VERSION "HNNBNNNYNNNNNNNNNNNNNNNNNNNNNNNNNNNNNNNNNN/4/%%%/4/'%**4NNN///"

NS_ :

BS_:

BU_: BAP_Tester conBox Gateway Gateway_PAG OTA_FC

BO_ 64 Airbag_01: 8 Gateway
 SG_ Airbag_01_CRC : 0|8@1+ (1,0) [0|255] ""  Vector__XXX
 SG_ Airbag_01_BZ : 8|4@1+ (1,0) [0|15] ""  Vector__XXX
 SG_ AB_RGS_Anst : 12|4@1+ (1.0,0.0) [0.0|15] ""  Vector__XXX
 SG_ AB_Front_Crash : 16|1@1+ (1.0,0.0) [0.0|1] ""  conBox
 SG_ AB_Heck_Crash : 17|1@1+ (1.0,0.0) [0.0|1] ""  conBox
 SG_ AB_SF_Crash : 18|1@1+ (1.0,0.0) [0.0|1] ""  conBox
 SG_ AB_SB_Crash : 19|1@1+ (1.0,0.0) [0.0|1] ""  conBox
 SG_ AB_Rollover_Crash : 20|1@1+ (1.0,0.0) [0.0|1] ""  conBox
 SG_ AB_Crash_Int : 21|3@1+ (1.0,0.0) [0.0|7] ""  conBox
 SG_ AB_Lampe : 24|1@1+ (1.0,0.0) [0.0|1] ""  Vector__XXX
 SG_ AB_Deaktiviert : 25|1@1+ (1.0,0.0) [0.0|1] ""  Vector__XXX
 SG_ AB_VB_deaktiviert : 26|1@1+ (1.0,0.0) [0.0|1] ""  Vector__XXX
 SG_ AB_Systemfehler : 27|1@1+ (1.0,0.0) [0.0|1] ""  conBox
 SG_ AB_Diagnose : 28|1@1+ (1.0,0.0) [0.0|1] ""  conBox
 SG_ AB_Stellgliedtest : 29|1@1+ (1.0,0.0) [0.0|1] ""  conBox
 SG_ AB_Erh_Auf_VB : 30|2@1+ (1.0,0.0) [0.0|3] ""  Vector__XXX
 SG_ AB_Gurtwarn_VF : 32|1@1+ (1.0,0.0) [0.0|1] ""  Vector__XXX
 SG_ AB_Gurtwarn_VB : 33|1@1+ (1.0,0.0) [0.0|1] ""  Vector__XXX
 SG_ AB_Anzeige_Fussg : 34|2@1+ (1.0,0.0) [0.0|3] ""  conBox
 SG_ AB_Texte_AKS : 36|2@1+ (1.0,0.0) [0.0|3] ""  Vector__XXX
 SG_ AB_MKB_gueltig : 39|1@1+ (1.0,0.0) [0.0|1] ""  Vector__XXX
 SG_ AB_MKB_Anforderung : 40|1@1+ (1.0,0.0) [0.0|1] ""  Vector__XXX
 SG_ AB_Versorgungsspannung : 41|1@1+ (1.0,0.0) [0.0|1] ""  Vector__XXX
 SG_ AB_Deaktivierung_HV : 42|3@1+ (1.0,0.0) [0.0|7] ""  Vector__XXX
 SG_ AB_EDR_Trigger : 45|2@1+ (1.0,0.0) [0.0|3] ""  Vector__XXX
 SG_ AB_Belegung_VF : 47|2@1+ (1.0,0.0) [0.0|3] ""  Vector__XXX
 SG_ SC_Masterzeit_Offset : 53|2@1+ (5.08,0) [0.00|15.24] "Unit_Secon"  Vector__XXX
 SG_ SC_LowSpeedCrashErkannt : 55|2@1+ (1.0,0.0) [0.0|3] ""  Vector__XXX
 SG_ SC_Masterzeit : 57|7@1+ (0.04,0) [0.00|5.04] "Unit_Secon"  Vector__XXX

BO_ 1312 Airbag_02: 8 Gateway
 SG_ Airbag_02_CRC : 0|8@1+ (1,0) [0|255] ""  Vector__XXX
 SG_ Airbag_02_BZ : 8|4@1+ (1,0) [0|15] ""  Vector__XXX
 SG_ LoGeWa_Event_Kombiwarnung : 12|4@1+ (1.0,0.0) [0.0|15] ""  Vector__XXX
 SG_ AB_Anforderung_eCall : 16|1@1+ (1.0,0.0) [0.0|1] ""  conBox
 SG_ AB_Anprall_Seite_Beifahrer : 17|1@1+ (1.0,0.0) [0.0|1] ""  Vector__XXX
 SG_ AB_Anprall_Rollover : 18|1@1+ (1.0,0.0) [0.0|1] ""  Vector__XXX
 SG_ AB_Anprall_FGS : 19|1@1+ (1.0,0.0) [0.0|1] ""  Vector__XXX
 SG_ AB_Anprall_Front_Beifahrer : 20|1@1+ (1.0,0.0) [0.0|1] ""  Vector__XXX
 SG_ AB_Anprall_Front_Fahrer : 21|1@1+ (1.0,0.0) [0.0|1] ""  Vector__XXX
 SG_ AB_Anprall_Heck_Beifahrer : 22|1@1+ (1.0,0.0) [0.0|1] ""  Vector__XXX
 SG_ AB_Anprall_Heck_Fahrer : 23|1@1+ (1.0,0.0) [0.0|1] ""  Vector__XXX
 SG_ AB_Wickelklappung_Reihe2_MI : 24|2@1+ (1.0,0.0) [0.0|3] ""  Vector__XXX
 SG_ AB_Belegung_VB : 26|2@1+ (1.0,0.0) [0.0|3] ""  conBox
 SG_ AB_Abschaltanf_SIH_BF : 28|1@1+ (1.0,0.0) [0.0|1] ""  Vector__XXX
 SG_ AB_Anprall_Seite_Fahrer : 29|1@1+ (1.0,0.0) [0.0|1] ""  Vector__XXX
 SG_ SC_PAO_Schriftzug_Anf : 30|2@1+ (1.0,0.0) [0.0|3] ""  Vector__XXX
 SG_ SC_PAO_ON_Anf : 32|2@1+ (1.0,0.0) [0.0|3] ""  Vector__XXX
 SG_ SC_PAO_OFF_Anf : 34|2@1+ (1.0,0.0) [0.0|3] ""  Vector__XXX
 SG_ AB_Crashschwere : 36|3@1+ (1.0,0.0) [0.0|7] ""  Vector__XXX
 SG_ AB_Anforderung_USM : 39|1@1+ (1.0,0.0) [0.0|1] ""  Vector__XXX
 SG_ AB_Gurtschloss_FA : 40|2@1+ (1.0,0.0) [0.0|3] ""  conBox
 SG_ AB_Gurtschloss_BF : 42|2@1+ (1.0,0.0) [0.0|3] ""  conBox
 SG_ AB_Gurtschloss_Reihe2_FA : 44|2@1+ (1.0,0.0) [0.0|3] ""  conBox
 SG_ AB_Gurtschloss_Reihe2_MI : 46|2@1+ (1.0,0.0) [0.0|3] ""  conBox
 SG_ AB_Gurtschloss_Reihe2_BF : 48|2@1+ (1.0,0.0) [0.0|3] ""  conBox
 SG_ AB_Gurtschloss_Reihe3_FA : 50|2@1+ (1.0,0.0) [0.0|3] ""  conBox
 SG_ AB_Gurtschloss_Reihe3_MI : 52|2@1+ (1.0,0.0) [0.0|3] ""  conBox
 SG_ AB_Gurtschloss_Reihe3_BF : 54|2@1+ (1.0,0.0) [0.0|3] ""  conBox
 SG_ AB_Sitzpos_Sens_FA : 56|2@1+ (1.0,0.0) [0.0|3] ""  Vector__XXX
 SG_ AB_Sitzpos_Sens_BF : 58|2@1+ (1.0,0.0) [0.0|3] ""  Vector__XXX
 SG_ AB_Wickelklappung_Reihe2_BF : 60|2@1+ (1.0,0.0) [0.0|3] ""  Vector__XXX
 SG_ AB_Wickelklappung_Reihe2_FA : 62|2@1+ (1.0,0.0) [0.0|3] ""  Vector__XXX

BO_ 2536705796 BAP_BC_ASG_05: 8 OTA_FC
 SG_ BAP_BC_ASG_05_Header : 0|8@1+ (1,0) [0|255] "Unit_None"  Gateway_PAG

BO_ 2536705808 BAP_BC_FSG_01: 8 Gateway_PAG
 SG_ BAP_BC_FSG_01_Header : 0|8@1+ (1.0,0.0) [0.0|255] ""  OTA_FC

BO_ 2536720128 BAP_ConnectionMngr_ASG_01: 8 Gateway
 SG_ BAP_ConnectionMngr_ASG_01_Header : 0|8@1+ (1,0) [0|255] "Unit_None"  Vector__XXX

BO_ 2536720129 BAP_ConnectionMngr_ASG_02: 8 Gateway
 SG_ BAP_ConnectionMngr_ASG_02_Header : 0|64@1+ (1.0,0.0) [0.0|18446744073709551615] ""  conBox

BO_ 2536720130 BAP_ConnectionMngr_ASG_03: 8 Gateway
 SG_ BAP_ConnectionMngr_ASG_03_Header : 0|64@1+ (1.0,0.0) [0.0|18446744073709551615] ""  conBox

BO_ 2536720144 BAP_ConnectionMngr_FSG_01: 8 conBox
 SG_ BAP_ConnectionMngr_FSG_01_Header : 0|8@1+ (1,0) [0|255] "Unit_None"  Gateway,Gateway_PAG

BO_ 2536767264 BAP_Debug_Cmd: 8 BAP_Tester
 SG_ BAP_Debug_Cmd : 0|16@1+ (1.0,0.0) [0.0|65535] ""  conBox,Gateway_PAG,OTA_FC

BO_ 2536767280 BAP_Debug_Data: 8 conBox
 SG_ BAP_Debug_Data : 0|64@1+ (1.0,0.0) [0.0|18446744073709551615] ""  BAP_Tester

BO_ 2536715008 BAP_eCall_ASG_01: 8 Gateway
 SG_ BAP_eCall_ASG_01_Header : 0|8@1+ (1.0,0.0) [0.0|255] ""  conBox

BO_ 2536715024 BAP_eCall_FSG_01: 8 conBox
 SG_ BAP_eCall_FSG_01_Header : 0|8@1+ (1.0,0.0) [0.0|255] ""  Gateway,Gateway_PAG

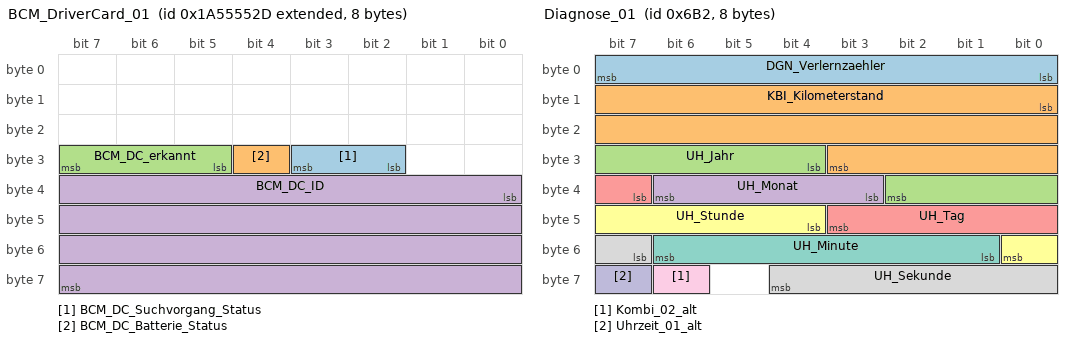
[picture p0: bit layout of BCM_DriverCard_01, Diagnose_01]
BO_ 2589283629 BCM_DriverCard_01: 8 Gateway
 SG_ BCM_DC_Suchvorgang_Status : 26|2@1+ (1.0,0.0) [0.0|3] ""  conBox
 SG_ BCM_DC_Batterie_Status : 28|1@1+ (1.0,0.0) [0.0|1] ""  conBox
 SG_ BCM_DC_erkannt : 29|3@1+ (1.0,0.0) [0.0|7] ""  conBox
 SG_ BCM_DC_ID : 32|32@1+ (1,0) [0|4294967294] ""  conBox

BO_ 961 BCM_Taster_01: 8 Gateway
 SG_ Heckrollo_2_Taster : 10|2@1+ (1.0,0.0) [0.0|3] ""  Vector__XXX
 SG_ APS_Taster : 12|2@1+ (1.0,0.0) [0.0|3] ""  Vector__XXX
 SG_ PLA_Taster : 14|2@1+ (1.0,0.0) [0.0|3] ""  Vector__XXX
 SG_ ESP_Off_Taster : 16|2@1+ (1.0,0.0) [0.0|3] ""  Vector__XXX
 SG_ HDC_Taster : 18|2@1+ (1.0,0.0) [0.0|3] ""  Vector__XXX
 SG_ AVH_Taster : 20|2@1+ (1.0,0.0) [0.0|3] ""  Vector__XXX
 SG_ Display_Taster : 22|2@1+ (1.0,0.0) [0.0|3] ""  Vector__XXX
 SG_ Heckrollo_Taster : 24|2@1+ (1.0,0.0) [0.0|3] ""  Vector__XXX
 SG_ Spoiler_Taster : 26|2@1+ (1.0,0.0) [0.0|3] ""  Vector__XXX
 SG_ Drivesel_1_Taster : 28|2@1+ (1.0,0.0) [0.0|3] ""  Vector__XXX
 SG_ Drivesel_2_Taster : 30|2@1+ (1.0,0.0) [0.0|3] ""  Vector__XXX
 SG_ Sideview_Taster : 32|2@1+ (1.0,0.0) [0.0|3] ""  Vector__XXX
 SG_ LIM_PAO_Alivesignal : 34|4@1+ (1,0) [0|15] ""  Vector__XXX
 SG_ LKS_Taster : 38|2@1+ (1.0,0.0) [0.0|3] ""  Vector__XXX
 SG_ SWA_Taster : 40|2@1+ (1.0,0.0) [0.0|3] ""  Vector__XXX
 SG_ LIM_bCall_Taster : 42|1@1+ (1.0,0.0) [0.0|1] ""  Vector__XXX
 SG_ eCall_Taste : 43|2@1+ (1.0,0.0) [0.0|3] ""  conBox
 SG_ PLA_Taster_Fehler_Roh : 45|1@1+ (1.0,0.0) [0.0|1] ""  Vector__XXX
 SG_ LIM_PAO_ON_Status : 46|2@1+ (1.0,0.0) [0.0|3] ""  Vector__XXX
 SG_ LIM_PAO_OFF_Status : 48|2@1+ (1.0,0.0) [0.0|3] ""  Vector__XXX
 SG_ LIM_PAO_Schriftzug_Status : 50|2@1+ (1.0,0.0) [0.0|3] ""  Vector__XXX
 SG_ Spoiler_LED_Status : 52|2@1+ (1.0,0.0) [0.0|3] ""  Vector__XXX
 SG_ AVH_LED_Status : 54|2@1+ (1.0,0.0) [0.0|3] ""  Vector__XXX
 SG_ HDC_LED_Status : 56|2@1+ (1.0,0.0) [0.0|3] ""  Vector__XXX
 SG_ PLA_LED_Status : 60|2@1+ (1.0,0.0) [0.0|3] ""  Vector__XXX
 SG_ APS_LED_Status : 62|2@1+ (1.0,0.0) [0.0|3] ""  Vector__XXX

BO_ 870 Blinkmodi_02: 8 Gateway
 SG_ BM_ZV_auf : 12|1@1+ (1.0,0.0) [0.0|1] ""  Vector__XXX
 SG_ BM_ZV_zu : 13|1@1+ (1.0,0.0) [0.0|1] ""  Vector__XXX
 SG_ BM_DWA_ein : 14|1@1+ (1.0,0.0) [0.0|1] ""  Vector__XXX
 SG_ BM_DWA_Alarm : 15|1@1+ (1.0,0.0) [0.0|1] ""  conBox
 SG_ BM_Crash : 16|1@1+ (1.0,0.0) [0.0|1] ""  Vector__XXX
 SG_ BM_Panik : 17|1@1+ (1.0,0.0) [0.0|1] ""  Vector__XXX
 SG_ BM_Not_Bremsung : 18|1@1+ (1.0,0.0) [0.0|1] ""  Vector__XXX
 SG_ BM_GDO : 19|1@1+ (1.0,0.0) [0.0|1] ""  Vector__XXX
 SG_ BM_Warnblinken : 20|1@1+ (1.0,0.0) [0.0|1] ""  conBox
 SG_ BM_Taxi_Notalarm : 21|1@1+ (1.0,0.0) [0.0|1] ""  Vector__XXX
 SG_ BM_Telematik : 22|1@1+ (1.0,0.0) [0.0|1] ""  Vector__XXX
 SG_ BM_links : 23|1@1+ (1.0,0.0) [0.0|1] ""  conBox
 SG_ BM_rechts : 24|1@1+ (1.0,0.0) [0.0|1] ""  conBox
 SG_ Blinken_li_Fzg_Takt : 25|1@1+ (1.0,0.0) [0.0|1] ""  Vector__XXX
 SG_ Blinken_re_Fzg_Takt : 26|1@1+ (1.0,0.0) [0.0|1] ""  Vector__XXX
 SG_ Blinken_li_Kombi_Takt : 27|1@1+ (1.0,0.0) [0.0|1] ""  Vector__XXX
 SG_ Blinken_re_Kombi_Takt : 28|1@1+ (1.0,0.0) [0.0|1] ""  Vector__XXX
 SG_ BM_NBA_n_codiert_n_aktiv : 29|1@1+ (1.0,0.0) [0.0|1] ""  Vector__XXX
 SG_ BM_NBA_Status : 30|2@1+ (1.0,0.0) [0.0|3] ""  Vector__XXX
 SG_ BM_WBT_Beleuchtung : 32|1@1+ (1.0,0.0) [0.0|1] ""  Vector__XXX
 SG_ BM_HD_Oeffnung_angelernt : 33|1@1+ (1.0,0.0) [0.0|1] ""  Vector__XXX
 SG_ BM_Autobahn : 34|1@1+ (1.0,0.0) [0.0|1] ""  Vector__XXX
 SG_ BM_Rollenmodus_Blinken : 35|1@1+ (1.0,0.0) [0.0|1] ""  Vector__XXX
 SG_ BM_Recas : 36|1@1+ (1.0,0.0) [0.0|1] ""  Vector__XXX
 SG_ BM_Wischblinken : 37|1@1+ (1.0,0.0) [0.0|1] ""  Vector__XXX
 SG_ BM_Telematik_Abbruchgrund : 38|6@1+ (1.0,0.0) [0.0|63] ""  Vector__XXX
 SG_ BM_PiloPa : 44|1@1+ (1.0,0.0) [0.0|1] ""  Vector__XXX
 SG_ DWA_Alarmquelle : 59|5@1+ (1.0,0.0) [0.0|31] ""  conBox

BO_ 2617195008 DEV_eCall_Resp_00: 8 conBox
 SG_ DEV_eCall_Resp_00_Data : 0|64@1+ (1.0,0.0) [0.0|18446744073709551615] ""  Vector__XXX

BO_ 2617195263 DEV_eCall_Resp_FF: 8 conBox
 SG_ DEV_eCall_Resp_FF_Data : 0|64@1+ (1.0,0.0) [0.0|18446744073709551615] ""  Vector__XXX

BO_ 2616996608 DEV_OTA_FC_Resp_00: 8 OTA_FC
 SG_ DEV_OTA_FC_Resp_00_Data : 0|64@1+ (1.0,0.0) [0.0|18446744073709551615] ""  Vector__XXX

BO_ 2616996863 DEV_OTA_FC_Resp_FF: 8 OTA_FC
 SG_ DEV_OTA_FC_Resp_FF_Data : 0|64@1+ (1.0,0.0) [0.0|18446744073709551615] ""  Vector__XXX

BO_ 1714 Diagnose_01: 8 Gateway
 SG_ DGN_Verlernzaehler : 0|8@1+ (1,0) [0|254] ""  conBox
 SG_ KBI_Kilometerstand : 8|20@1+ (1,0) [0|1048573] "Unit_KiloMeter"  conBox
 SG_ UH_Jahr : 28|7@1+ (1,2000) [2000|2127] "Unit_Year"  conBox
 SG_ UH_Monat : 35|4@1+ (1,0) [1|12] "Unit_Month"  conBox
 SG_ UH_Tag : 39|5@1+ (1,0) [1|31] "Unit_Day"  conBox
 SG_ UH_Stunde : 44|5@1+ (1,0) [0|23] "Unit_Hours"  conBox
 SG_ UH_Minute : 49|6@1+ (1,0) [0|59] "Unit_Minut"  conBox
 SG_ UH_Sekunde : 55|6@1+ (1,0) [0|59] "Unit_Secon"  conBox
 SG_ Kombi_02_alt : 62|1@1+ (1.0,0.0) [0.0|1] ""  Vector__XXX
 SG_ Uhrzeit_01_alt : 63|1@1+ (1.0,0.0) [0.0|1] ""  Vector__XXX

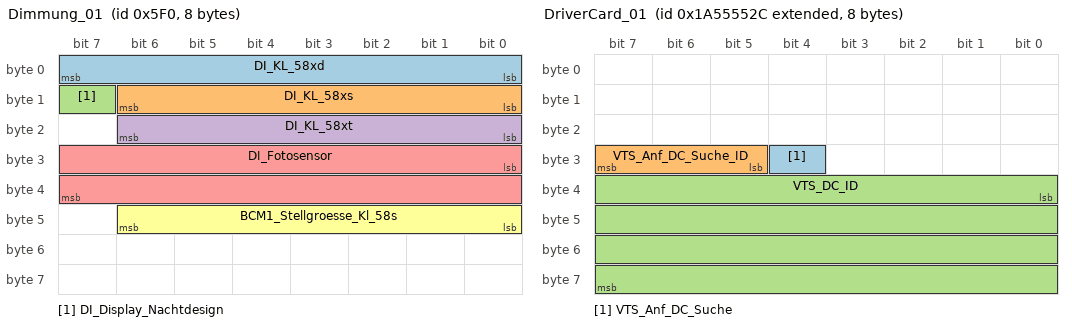
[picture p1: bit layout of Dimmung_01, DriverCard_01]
BO_ 1520 Dimmung_01: 8 Gateway
 SG_ DI_KL_58xd : 0|8@1+ (1,0) [0|253] ""  conBox
 SG_ DI_KL_58xs : 8|7@1+ (1,0) [0|100] "Unit_PerCent"  Vector__XXX
 SG_ DI_Display_Nachtdesign : 15|1@1+ (1.0,0.0) [0.0|1] ""  Vector__XXX
 SG_ DI_KL_58xt : 16|7@1+ (1,0) [0|100] "Unit_PerCent"  Vector__XXX
 SG_ DI_Fotosensor : 24|16@1+ (1,0) [0|65535] ""  Vector__XXX
 SG_ BCM1_Stellgroesse_Kl_58s : 40|7@1+ (1,0) [0|100] ""  Vector__XXX

BO_ 2589283628 DriverCard_01: 8 conBox
 SG_ VTS_Anf_DC_Suche : 28|1@1+ (1.0,0.0) [0.0|1] ""  Gateway,Gateway_PAG
 SG_ VTS_Anf_DC_Suche_ID : 29|3@1+ (1.0,0.0) [0.0|7] ""  Gateway,Gateway_PAG
 SG_ VTS_DC_ID : 32|32@1+ (1,0) [0|4294967294] "Unit_None"  Gateway,Gateway_PAG

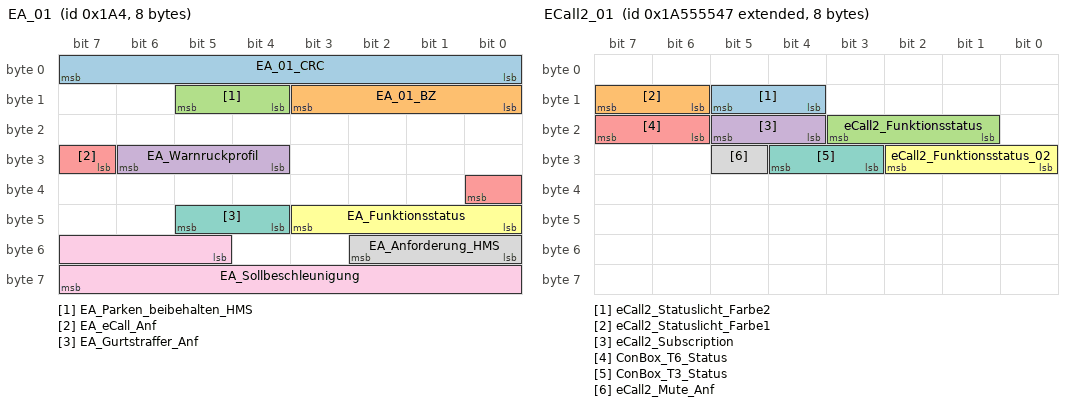
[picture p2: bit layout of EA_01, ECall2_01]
BO_ 420 EA_01: 8 Gateway
 SG_ EA_01_CRC : 0|8@1+ (1,0) [0|255] ""  Vector__XXX
 SG_ EA_01_BZ : 8|4@1+ (1,0) [0|15] ""  Vector__XXX
 SG_ EA_Parken_beibehalten_HMS : 12|2@1+ (1.0,0.0) [0.0|3] ""  Vector__XXX
 SG_ EA_Warnruckprofil : 28|3@1+ (1.0,0.0) [0.0|7] ""  Vector__XXX
 SG_ EA_eCall_Anf : 31|2@1+ (1.0,0.0) [0.0|3] ""  conBox
 SG_ EA_Funktionsstatus : 40|4@1+ (1.0,0.0) [0.0|15] ""  Vector__XXX
 SG_ EA_Gurtstraffer_Anf : 44|2@1+ (1.0,0.0) [0.0|3] ""  Vector__XXX
 SG_ EA_Anforderung_HMS : 48|3@1+ (1.0,0.0) [0.0|7] ""  Vector__XXX
 SG_ EA_Sollbeschleunigung : 53|11@1+ (0.005,-7.22) [-7.220|3.005] "Unit_MeterPerSeconSquar"  Vector__XXX

BO_ 2589283655 ECall2_01: 8 conBox
 SG_ eCall2_Statuslicht_Farbe2 : 12|2@1+ (1.0,0.0) [0.0|3] ""  Gateway,Gateway_PAG
 SG_ eCall2_Statuslicht_Farbe1 : 14|2@1+ (1.0,0.0) [0.0|3] ""  Gateway,Gateway_PAG
 SG_ eCall2_Funktionsstatus : 17|3@1+ (1.0,0.0) [0.0|7] ""  Gateway,Gateway_PAG
 SG_ eCall2_Subscription : 20|2@1+ (1.0,0.0) [0.0|3] ""  Gateway,Gateway_PAG
 SG_ ConBox_T6_Status : 22|2@1+ (1.0,0.0) [0.0|3] ""  Gateway,Gateway_PAG
 SG_ eCall2_Funktionsstatus_02 : 24|3@1+ (1.0,0.0) [0.0|7] ""  Gateway,Gateway_PAG
 SG_ ConBox_T3_Status : 27|2@1+ (1.0,0.0) [0.0|3] ""  Gateway,Gateway_PAG
 SG_ eCall2_Mute_Anf : 29|1@1+ (1.0,0.0) [0.0|1] ""  Gateway,Gateway_PAG

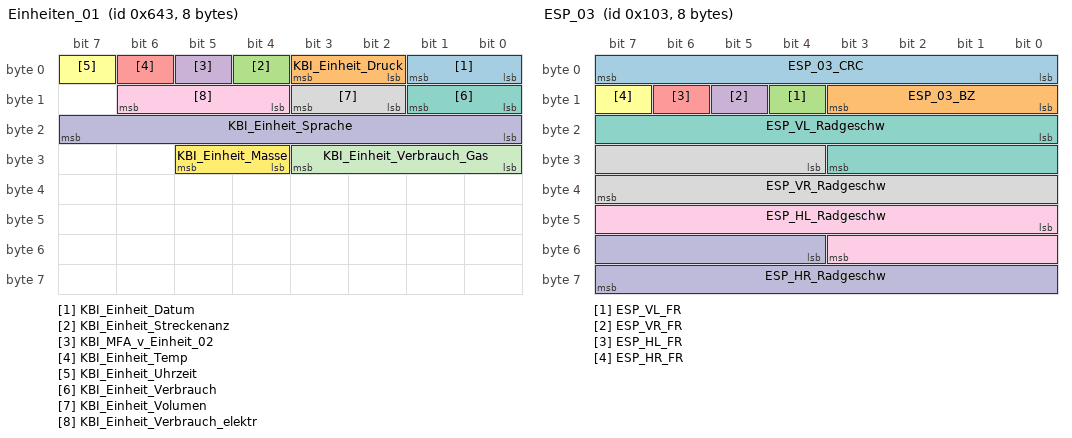
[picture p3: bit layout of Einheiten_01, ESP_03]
BO_ 1603 Einheiten_01: 8 Gateway
 SG_ KBI_Einheit_Datum : 0|2@1+ (1.0,0.0) [0.0|3] ""  Vector__XXX
 SG_ KBI_Einheit_Druck : 2|2@1+ (1.0,0.0) [0.0|3] ""  Vector__XXX
 SG_ KBI_Einheit_Streckenanz : 4|1@1+ (1.0,0.0) [0.0|1] ""  Vector__XXX
 SG_ KBI_MFA_v_Einheit_02 : 5|1@1+ (1.0,0.0) [0.0|1] ""  Vector__XXX
 SG_ KBI_Einheit_Temp : 6|1@1+ (1.0,0.0) [0.0|1] ""  Vector__XXX
 SG_ KBI_Einheit_Uhrzeit : 7|1@1+ (1.0,0.0) [0.0|1] ""  Vector__XXX
 SG_ KBI_Einheit_Verbrauch : 8|2@1+ (1.0,0.0) [0.0|3] ""  Vector__XXX
 SG_ KBI_Einheit_Volumen : 10|2@1+ (1.0,0.0) [0.0|3] ""  Vector__XXX
 SG_ KBI_Einheit_Verbrauch_elektr : 12|3@1+ (1.0,0.0) [0.0|7] ""  Vector__XXX
 SG_ KBI_Einheit_Sprache : 16|8@1+ (1,0) [0|255] ""  conBox
 SG_ KBI_Einheit_Verbrauch_Gas : 24|4@1+ (1.0,0.0) [0.0|15] ""  Vector__XXX
 SG_ KBI_Einheit_Masse : 28|2@1+ (1.0,0.0) [0.0|3] ""  Vector__XXX

BO_ 259 ESP_03: 8 Gateway
 SG_ ESP_03_CRC : 0|8@1+ (1,0) [0|255] ""  Vector__XXX
 SG_ ESP_03_BZ : 8|4@1+ (1,0) [0|15] ""  Vector__XXX
 SG_ ESP_VL_FR : 12|1@1+ (1.0,0.0) [0.0|1] ""  conBox
 SG_ ESP_VR_FR : 13|1@1+ (1.0,0.0) [0.0|1] ""  conBox
 SG_ ESP_HL_FR : 14|1@1+ (1.0,0.0) [0.0|1] ""  conBox
 SG_ ESP_HR_FR : 15|1@1+ (1.0,0.0) [0.0|1] ""  conBox
 SG_ ESP_VL_Radgeschw : 16|12@1+ (0.1,0) [0.0|409.2] "Unit_KiloMeterPerHour"  conBox
 SG_ ESP_VR_Radgeschw : 28|12@1+ (0.1,0) [0.0|409.2] "Unit_KiloMeterPerHour"  conBox
 SG_ ESP_HL_Radgeschw : 40|12@1+ (0.1,0) [0.0|409.2] "Unit_KiloMeterPerHour"  conBox
 SG_ ESP_HR_Radgeschw : 52|12@1+ (0.1,0) [0.0|409.2] "Unit_KiloMeterPerHour"  conBox

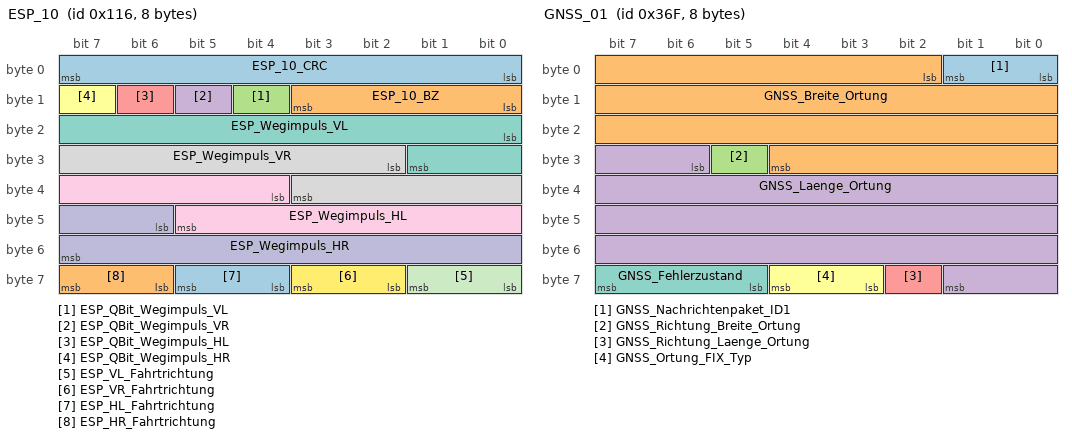
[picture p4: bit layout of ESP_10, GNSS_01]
BO_ 278 ESP_10: 8 Gateway
 SG_ ESP_10_CRC : 0|8@1+ (1,0) [0|255] ""  Vector__XXX
 SG_ ESP_10_BZ : 8|4@1+ (1,0) [0|15] ""  Vector__XXX
 SG_ ESP_QBit_Wegimpuls_VL : 12|1@1+ (1.0,0.0) [0.0|1] ""  conBox
 SG_ ESP_QBit_Wegimpuls_VR : 13|1@1+ (1.0,0.0) [0.0|1] ""  conBox
 SG_ ESP_QBit_Wegimpuls_HL : 14|1@1+ (1.0,0.0) [0.0|1] ""  conBox
 SG_ ESP_QBit_Wegimpuls_HR : 15|1@1+ (1.0,0.0) [0.0|1] ""  conBox
 SG_ ESP_Wegimpuls_VL : 16|10@1+ (1,0) [0|1000] ""  conBox
 SG_ ESP_Wegimpuls_VR : 26|10@1+ (1,0) [0|1000] ""  conBox
 SG_ ESP_Wegimpuls_HL : 36|10@1+ (1,0) [0|1000] ""  conBox
 SG_ ESP_Wegimpuls_HR : 46|10@1+ (1,0) [0|1000] ""  conBox
 SG_ ESP_VL_Fahrtrichtung : 56|2@1+ (1.0,0.0) [0.0|3] ""  conBox
 SG_ ESP_VR_Fahrtrichtung : 58|2@1+ (1.0,0.0) [0.0|3] ""  conBox
 SG_ ESP_HL_Fahrtrichtung : 60|2@1+ (1.0,0.0) [0.0|3] ""  conBox
 SG_ ESP_HR_Fahrtrichtung : 62|2@1+ (1.0,0.0) [0.0|3] ""  conBox

BO_ 1629 ESP_20: 8 Gateway
 SG_ ESP_20_CRC : 0|8@1+ (1,0) [0|255] ""  Vector__XXX
 SG_ ESP_20_BZ : 8|4@1+ (1,0) [0|15] ""  Vector__XXX
 SG_ BR_Systemart : 12|2@1+ (1.0,0.0) [0.0|3] ""  Vector__XXX
 SG_ ESP_SpannungsAnf_02 : 14|2@1+ (1.0,0.0) [0.0|3] ""  Vector__XXX
 SG_ ESP_Zaehnezahl : 16|8@1+ (1,0) [0|255] ""  conBox
 SG_ ESP_Charisma_FahrPr : 24|4@1+ (1.0,0.0) [0.0|15] ""  Vector__XXX
 SG_ ESP_Charisma_Status : 28|2@1+ (1.0,0.0) [0.0|3] ""  Vector__XXX
 SG_ ESP_Wiederstart_Anz_01 : 30|1@1+ (1.0,0.0) [0.0|1] ""  Vector__XXX
 SG_ ESP_Wiederstart_Anz_02 : 31|1@1+ (1.0,0.0) [0.0|1] ""  Vector__XXX
 SG_ ESP_Wiederstart_Anz_03 : 32|1@1+ (1.0,0.0) [0.0|1] ""  Vector__XXX
 SG_ ESP_Wiederstart_Anz_04 : 33|1@1+ (1.0,0.0) [0.0|1] ""  Vector__XXX
 SG_ ESP_Stoppverbot_Anz_01 : 34|1@1+ (1.0,0.0) [0.0|1] ""  Vector__XXX
 SG_ ESP_Stoppverbot_Anz_02 : 35|1@1+ (1.0,0.0) [0.0|1] ""  Vector__XXX
 SG_ ESP_Stoppverbot_Anz_03 : 36|1@1+ (1.0,0.0) [0.0|1] ""  Vector__XXX
 SG_ ESP_Stoppverbot_Anz_04 : 37|1@1+ (1.0,0.0) [0.0|1] ""  Vector__XXX
 SG_ ESP_Stoppverbot_Anz_05 : 38|1@1+ (1.0,0.0) [0.0|1] ""  Vector__XXX
 SG_ ESP_Stoppverbot_Anz_06 : 39|1@1+ (1.0,0.0) [0.0|1] ""  Vector__XXX
 SG_ ESP_Stoppverbot_Anz_07 : 40|1@1+ (1.0,0.0) [0.0|1] ""  Vector__XXX
 SG_ ESP_Stoppverbot_Anz_Std : 41|1@1+ (1.0,0.0) [0.0|1] ""  Vector__XXX
 SG_ ESP_Dachrelingsensor : 42|2@1+ (1.0,0.0) [0.0|3] ""  Vector__XXX
 SG_ ESP_Stoppverbot_Anz_08 : 44|1@1+ (1.0,0.0) [0.0|1] ""  Vector__XXX
 SG_ HDC_Charisma_FahrPr : 45|4@1+ (1.0,0.0) [0.0|15] ""  Vector__XXX
 SG_ HDC_Charisma_Status : 49|2@1+ (1.0,0.0) [0.0|3] ""  Vector__XXX
 SG_ BR_QBit_Reifenumfang : 51|1@1+ (1.0,0.0) [0.0|1] ""  conBox
 SG_ BR_Reifenumfang : 52|12@1+ (1,0) [0|4095] "Unit_MilliMeter"  conBox

BO_ 253 ESP_21: 8 Gateway
 SG_ ESP_21_CRC : 0|8@1+ (1,0) [0|255] ""  Vector__XXX
 SG_ ESP_21_BZ : 8|4@1+ (1,0) [0|15] ""  Vector__XXX
 SG_ BR_Eingriffsmoment : 12|10@1+ (1,-509) [-509|509] ""  Vector__XXX
 SG_ MSR_verfuegbar : 22|1@1+ (1.0,0.0) [0.0|1] ""  Vector__XXX
 SG_ ESP_Diagnose : 23|1@1+ (1.0,0.0) [0.0|1] ""  Vector__XXX
 SG_ ESC_v_Signal_Qualifier_High_Low : 24|3@1+ (1.0,0.0) [0.0|7] ""  Vector__XXX
 SG_ ESP_Vorsteuerung : 28|1@1+ (1.0,0.0) [0.0|1] ""  Vector__XXX
 SG_ OBD_Schlechtweg : 30|1@1+ (1.0,0.0) [0.0|1] ""  Vector__XXX
 SG_ OBD_QBit_Schlechtweg : 31|1@1+ (1.0,0.0) [0.0|1] ""  Vector__XXX
 SG_ ESP_v_Signal : 32|16@1+ (0.01,0) [0.00|655.32] "Unit_KiloMeterPerHour"  conBox
 SG_ ASR_Tastung_passiv : 48|1@1+ (1.0,0.0) [0.0|1] ""  Vector__XXX
 SG_ ESP_Tastung_passiv : 49|1@1+ (1.0,0.0) [0.0|1] ""  Vector__XXX
 SG_ ESP_Systemstatus : 50|1@1+ (1.0,0.0) [0.0|1] ""  conBox
 SG_ ASR_Schalteingriff : 51|2@1+ (1.0,0.0) [0.0|3] ""  Vector__XXX
 SG_ ESP_QBit_v_Signal : 55|1@1+ (1.0,0.0) [0.0|1] ""  conBox
 SG_ ABS_Bremsung : 56|1@1+ (1.0,0.0) [0.0|1] ""  conBox
 SG_ ASR_Anf : 57|1@1+ (1.0,0.0) [0.0|1] ""  Vector__XXX
 SG_ MSR_Anf : 58|1@1+ (1.0,0.0) [0.0|1] ""  Vector__XXX
 SG_ EBV_Eingriff : 59|1@1+ (1.0,0.0) [0.0|1] ""  conBox
 SG_ EDS_Eingriff : 60|1@1+ (1.0,0.0) [0.0|1] ""  Vector__XXX
 SG_ ESP_Eingriff : 61|1@1+ (1.0,0.0) [0.0|1] ""  conBox
 SG_ ESP_ASP : 62|1@1+ (1.0,0.0) [0.0|1] ""  Vector__XXX
 SG_ ESC_Neutralschaltung : 63|1@1+ (1.0,0.0) [0.0|1] ""  Vector__XXX

BO_ 508 ESP_32: 8 Gateway
 SG_ ESP_32_CRC : 0|8@1+ (1,0) [0|255] ""  Vector__XXX
 SG_ ESP_32_BZ : 8|4@1+ (1,0) [0|15] ""  Vector__XXX
 SG_ ESP_Status_Bremsentemp_02 : 12|2@1+ (1.0,0.0) [0.0|3] ""  Vector__XXX
 SG_ ESP_Aggregataktivitaet : 14|1@1+ (1.0,0.0) [0.0|1] ""  Vector__XXX
 SG_ ESP_Stillstandsflag : 15|1@1+ (1.0,0.0) [0.0|1] ""  conBox
 SG_ ESC_MBK_Meldungen : 16|2@1+ (1.0,0.0) [0.0|3] ""  Vector__XXX
 SG_ ESP_EDS_Anzeige : 32|3@1+ (1.0,0.0) [0.0|7] ""  Vector__XXX
 SG_ RLE_Anzeigen : 35|3@1+ (1.0,0.0) [0.0|7] ""  Vector__XXX
 SG_ ESP_Wiederstart_Anz_Std : 38|1@1+ (1.0,0.0) [0.0|1] ""  Vector__XXX
 SG_ ESC_Anforderung_Airbrake : 39|1@1+ (1.0,0.0) [0.0|1] ""  Vector__XXX
 SG_ ESC_FBA_Meldungen : 40|2@1+ (1.0,0.0) [0.0|3] ""  Vector__XXX
 SG_ ESP_Rollover_Status_dyn : 42|2@1+ (1.0,0.0) [0.0|3] ""  Vector__XXX
 SG_ ESP_Rollover_Status_stat : 44|2@1+ (1.0,0.0) [0.0|3] ""  Vector__XXX
 SG_ ESP_AVH_LED : 46|3@1+ (1.0,0.0) [0.0|7] ""  Vector__XXX
 SG_ ESP_HDC_LED : 49|3@1+ (1.0,0.0) [0.0|7] ""  Vector__XXX
 SG_ ESP_Off_LED : 52|3@1+ (1.0,0.0) [0.0|7] ""  Vector__XXX
 SG_ ESP_Notbremsanzeige : 55|1@1+ (1.0,0.0) [0.0|1] ""  conBox
 SG_ ESC_Motorstartverzoegerung : 56|1@1+ (1.0,0.0) [0.0|1] ""  Vector__XXX
 SG_ ESP_Offroad_Lampe : 57|1@1+ (1.0,0.0) [0.0|1] ""  Vector__XXX
 SG_ ESP_HDC_Textanzeigen : 58|5@1+ (1.0,0.0) [0.0|31] ""  Vector__XXX
 SG_ ESP_HOLD_verf : 63|1@1+ (1.0,0.0) [0.0|1] ""  Vector__XXX

BO_ 2549875590 FoD_OTA_FC_Req: 8 Gateway_PAG
 SG_ FoD_OTA_FC_Req_Data : 0|64@1+ (1.0,0.0) [0.0|18446744073709551615] ""  OTA_FC

BO_ 2550006662 FoD_OTA_FC_Resp: 8 OTA_FC
 SG_ FoD_OTA_FC_Resp_Data : 0|64@1+ (1.0,0.0) [0.0|18446744073709551615] ""  Gateway_PAG

BO_ 879 GNSS_01: 8 conBox
 SG_ GNSS_Nachrichtenpaket_ID1 : 0|2@1+ (1,0) [0|3] "Unit_Bit"  Gateway,Gateway_PAG
 SG_ GNSS_Breite_Ortung : 2|27@1+ (0.000001,0) [0.000000|90.000000] "Unit_DegreOfArc"  Gateway,Gateway_PAG
 SG_ GNSS_Richtung_Breite_Ortung : 29|1@1+ (1.0,0.0) [0.0|1] ""  Gateway,Gateway_PAG
 SG_ GNSS_Laenge_Ortung : 30|28@1+ (0.000001,0) [0.000000|180.000000] "Unit_DegreOfArc"  Gateway,Gateway_PAG
 SG_ GNSS_Richtung_Laenge_Ortung : 58|1@1+ (1.0,0.0) [0.0|1] ""  Gateway,Gateway_PAG
 SG_ GNSS_Ortung_FIX_Typ : 59|2@1+ (1.0,0.0) [0.0|3] ""  Gateway,Gateway_PAG
 SG_ GNSS_Fehlerzustand : 61|3@1+ (1.0,0.0) [0.0|7] ""  Gateway,Gateway_PAG

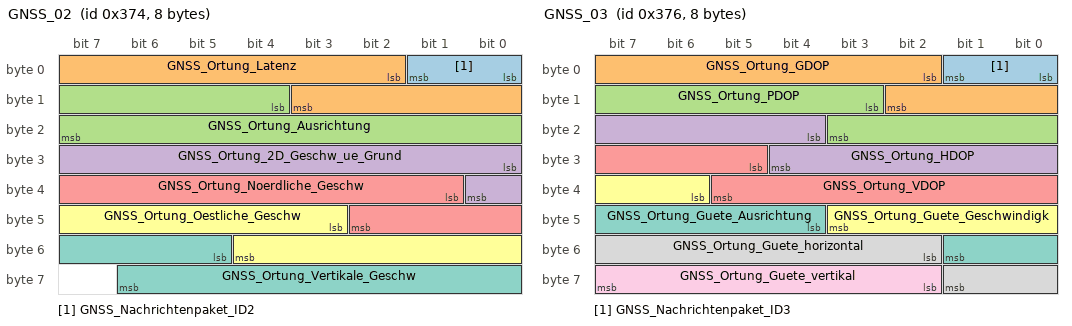
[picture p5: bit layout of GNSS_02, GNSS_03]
BO_ 884 GNSS_02: 8 conBox
 SG_ GNSS_Nachrichtenpaket_ID2 : 0|2@1+ (1,0) [0|3] "Unit_Bit"  Gateway,Gateway_PAG
 SG_ GNSS_Ortung_Latenz : 2|10@1+ (1,0) [0|1021] "Unit_MilliSecon"  Gateway,Gateway_PAG
 SG_ GNSS_Ortung_Ausrichtung : 12|12@1+ (0.1,0) [0.0|359.9] "Unit_DegreOfArc"  Gateway,Gateway_PAG
 SG_ GNSS_Ortung_2D_Geschw_ue_Grund : 24|9@1+ (0.25,0) [0.00|125.00] "Unit_MeterPerSecon"  Gateway,Gateway_PAG
 SG_ GNSS_Ortung_Noerdliche_Geschw : 33|10@1+ (0.25,-125) [-125.00|125.00] "Unit_MeterPerSecon"  Gateway,Gateway_PAG
 SG_ GNSS_Ortung_Oestliche_Geschw : 43|10@1+ (0.25,-125) [-125.00|125.00] "Unit_MeterPerSecon"  Gateway,Gateway_PAG
 SG_ GNSS_Ortung_Vertikale_Geschw : 53|10@1+ (0.25,-125) [-125.00|125.00] "Unit_MeterPerSecon"  Gateway,Gateway_PAG

BO_ 886 GNSS_03: 8 conBox
 SG_ GNSS_Nachrichtenpaket_ID3 : 0|2@1+ (1,0) [0|3] "Unit_Bit"  Gateway,Gateway_PAG
 SG_ GNSS_Ortung_GDOP : 2|9@1+ (0.1,0) [0.0|50.0] "Unit_None"  Gateway,Gateway_PAG
 SG_ GNSS_Ortung_PDOP : 11|9@1+ (0.1,0) [0.0|50.0] "Unit_None"  Gateway,Gateway_PAG
 SG_ GNSS_Ortung_HDOP : 20|9@1+ (0.1,0) [0.0|50.0] "Unit_None"  Gateway,Gateway_PAG
 SG_ GNSS_Ortung_VDOP : 29|9@1+ (0.1,0) [0.0|50.0] "Unit_None"  Gateway,Gateway_PAG
 SG_ GNSS_Ortung_Guete_Geschwindigk : 38|6@1+ (0.05,0) [0.00|3.05] "Unit_MeterPerSecon"  Gateway,Gateway_PAG
 SG_ GNSS_Ortung_Guete_Ausrichtung : 44|6@1+ (0.15,0) [0.00|9.15] "Unit_DegreOfArc"  Gateway,Gateway_PAG
 SG_ GNSS_Ortung_Guete_horizontal : 50|8@1+ (1,0) [0|250] "Unit_Meter"  Gateway,Gateway_PAG
 SG_ GNSS_Ortung_Guete_vertikal : 58|6@1+ (2,0) [0|122] "Unit_Meter"  Gateway,Gateway_PAG

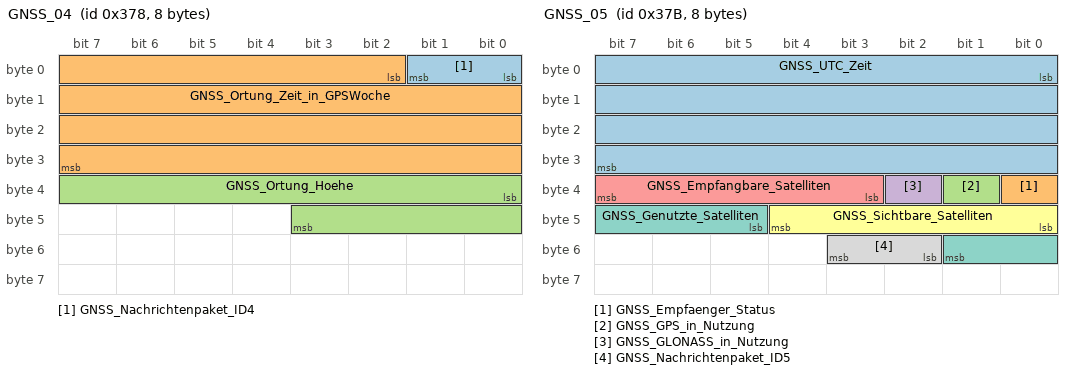
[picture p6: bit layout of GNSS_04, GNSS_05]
BO_ 888 GNSS_04: 8 conBox
 SG_ GNSS_Nachrichtenpaket_ID4 : 0|2@1+ (1,0) [0|3] "Unit_Bit"  Gateway,Gateway_PAG
 SG_ GNSS_Ortung_Zeit_in_GPSWoche : 2|30@1+ (1,0) [0|604800001] "Unit_MilliSecon"  Gateway,Gateway_PAG
 SG_ GNSS_Ortung_Hoehe : 32|12@1+ (2,-500) [-500|7686] "Unit_Meter"  Gateway,Gateway_PAG

BO_ 891 GNSS_05: 8 conBox
 SG_ GNSS_UTC_Zeit : 0|32@1+ (1,0) [1|4294967295] "Unit_Secon"  Gateway,Gateway_PAG
 SG_ GNSS_Empfaenger_Status : 32|1@1+ (1.0,0.0) [0.0|1] ""  Gateway,Gateway_PAG
 SG_ GNSS_GPS_in_Nutzung : 33|1@1+ (1.0,0.0) [0.0|1] ""  Gateway,Gateway_PAG
 SG_ GNSS_GLONASS_in_Nutzung : 34|1@1+ (1.0,0.0) [0.0|1] ""  Gateway,Gateway_PAG
 SG_ GNSS_Empfangbare_Satelliten : 35|5@1+ (1,0) [1|30] "Unit_None"  Gateway,Gateway_PAG
 SG_ GNSS_Sichtbare_Satelliten : 40|5@1+ (1,0) [1|30] "Unit_None"  Gateway,Gateway_PAG
 SG_ GNSS_Genutzte_Satelliten : 45|5@1+ (1,0) [1|30] "Unit_None"  Gateway,Gateway_PAG
 SG_ GNSS_Nachrichtenpaket_ID5 : 50|2@1+ (1,0) [0|3] "Unit_Bit"  Gateway,Gateway_PAG

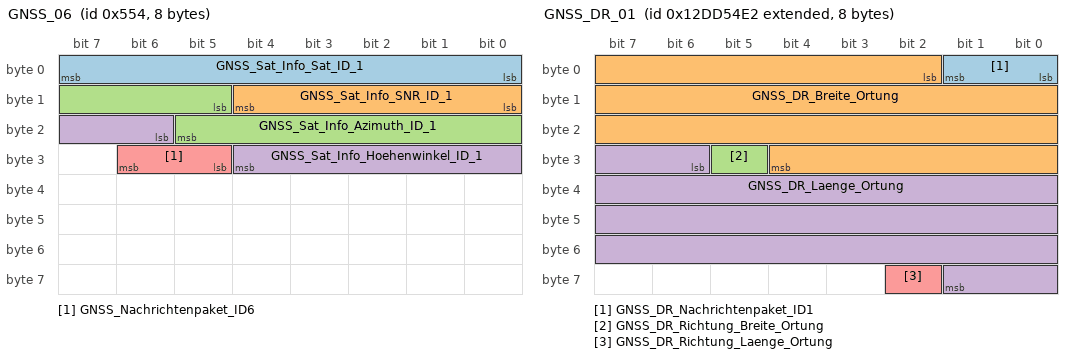
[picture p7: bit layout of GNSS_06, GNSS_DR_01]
BO_ 1364 GNSS_06: 8 conBox
 SG_ GNSS_Sat_Info_Sat_ID_1 : 0|8@1+ (1,0) [0|255] ""  Gateway,Gateway_PAG
 SG_ GNSS_Sat_Info_SNR_ID_1 : 8|5@1+ (2,0) [0|60] "Unit_DeziBel"  Gateway,Gateway_PAG
 SG_ GNSS_Sat_Info_Azimuth_ID_1 : 13|9@1+ (1,0) [0|359] "Unit_DegreOfArc"  Gateway,Gateway_PAG
 SG_ GNSS_Sat_Info_Hoehenwinkel_ID_1 : 22|7@1+ (1,0) [0|90] "Unit_DegreOfArc"  Gateway,Gateway_PAG
 SG_ GNSS_Nachrichtenpaket_ID6 : 29|2@1+ (1,0) [0|3] "Unit_Bit"  Gateway,Gateway_PAG

BO_ 2463978722 GNSS_DR_01: 8 conBox
 SG_ GNSS_DR_Nachrichtenpaket_ID1 : 0|2@1+ (1,0) [0|3] "Unit_Bit"  Gateway,Gateway_PAG
 SG_ GNSS_DR_Breite_Ortung : 2|27@1+ (0.000001,0) [0.000000|90.000000] "Unit_DegreOfArc"  Gateway,Gateway_PAG
 SG_ GNSS_DR_Richtung_Breite_Ortung : 29|1@1+ (1.0,0.0) [0.0|1] ""  Gateway,Gateway_PAG
 SG_ GNSS_DR_Laenge_Ortung : 30|28@1+ (0.000001,0) [0.000000|180.000000] "Unit_DegreOfArc"  Gateway,Gateway_PAG
 SG_ GNSS_DR_Richtung_Laenge_Ortung : 58|1@1+ (1.0,0.0) [0.0|1] ""  Gateway,Gateway_PAG

BO_TX_BU_ 64 :Gateway,Gateway_PAG;
BO_TX_BU_ 1312 :Gateway,Gateway_PAG;
BO_TX_BU_ 2536720129 :Gateway,Gateway_PAG;
BO_TX_BU_ 2536767280 :conBox,Gateway_PAG,OTA_FC;
BO_TX_BU_ 2536715008 :Gateway,Gateway_PAG;
BO_TX_BU_ 2589283629 :Gateway,Gateway_PAG;
BO_TX_BU_ 961 :Gateway,Gateway_PAG;
BO_TX_BU_ 870 :Gateway,Gateway_PAG;
BO_TX_BU_ 1714 :Gateway,Gateway_PAG;
BO_TX_BU_ 1520 :Gateway,Gateway_PAG;
BO_TX_BU_ 420 :Gateway,Gateway_PAG;
BO_TX_BU_ 1603 :Gateway,Gateway_PAG;
BO_TX_BU_ 259 :Gateway,Gateway_PAG;
BO_TX_BU_ 278 :Gateway,Gateway_PAG;
BO_TX_BU_ 1629 :Gateway,Gateway_PAG;
BO_TX_BU_ 253 :Gateway,Gateway_PAG;
BO_TX_BU_ 508 :Gateway,Gateway_PAG;

CM_ "MLBevo_CCAN_V8.24.00F Generated by BusNet_NG_Produktiv 9.24.4";
CM_ BU_ conBox "Connectivity-Box Steuergerät zur Anbindung an Infrastrukturnetzwerke";
CM_ BU_ Gateway "MLBevo Diagnoseinterface für Datenbus

connected Gateway Version 2.0, Zulieferer Conti Markdorf
- e & e4

connected Gateway Version 3.1, Zulieferer ESR/Lear
- e, e2, e5, e6";
CM_ BU_ Gateway_PAG "Gateway-Variante für PAG - Absprungbasis Gateway 3.x";
CM_ BU_ OTA_FC "OTA_FC (Over the Air Function Controller)";

CM_ BO_ 870 "Nur die Kombination des statischen und toggelnden Signals ergibt den Blinktakt für die Hell & Dunkelphase";
CM_ BO_ 1520 "ab MQB nach abgestimmten FLH Dimmung";
CM_ BO_ 1603 "ab MQB mit 8 Byte";
CM_ BO_ 259 "MLBevo - CRC-Absicherung";
CM_ BO_ 1629 "neu im MQB";
CM_ BO_ 253 "Neue Momente im MQB
Struktur ab MQB mit CRC8 entstanden aus ESP_01";
CM_ BO_ 508 "CAN-Botschaft";
CM_ BO_ 879 "Nachricht 1 für Ortung:
Position und Fixtyp.";
CM_ BO_ 884 "Nachricht 2 für Ortung:
Latenz, Geschwindigkeit und Richtung.";
CM_ BO_ 886 "Nachricht 3 für Ortung:
Qualität der Ortung.";
CM_ BO_ 888 "Nachricht 4 für Ortung:
Zeitstempel der Ortung.";
CM_ BO_ 891 "Nachricht 5:
Empfängerstatus und UTC.";
CM_ BO_ 1364 "Nachricht 6:
Enthält Informationen über die Satelliten. Die Daten des stärksten Satelliten werden übertragen";

CM_ SG_ 64 AB_Anzeige_Fussg "Anzeige für ausgelöste Fussgängerschutz-Aktuatorik";
CM_ SG_ 64 AB_Belegung_VF "Belegungserkennung vorne Fahrer.";
CM_ SG_ 64 AB_Crash_Int "Crash_Intensität_1 = fahrzeugabhängige Reaktionen im Crash
Crash_Intensität_2 = fahrzeugabhängige Reaktionen im Crash
Crash_Intensität_3 = fahrzeugabhängige Reaktionen im Crash

Die jeweiligen fahrzeugabhängigen Reaktionen im Crash sind in einem separ";
CM_ SG_ 64 AB_Deaktiviert "Airbag oder Gurtstraffer wurden per Anpassung deaktiviert: Aktualisierung erst nach Selbsttest";
CM_ SG_ 64 AB_Deaktivierung_HV "Deaktivierung des HV-Systems und der HV-Teilnehmer im Crash (u.a. Hybrid- und Elektrofahrzeuge)";
CM_ SG_ 64 AB_Diagnose "Airbag in Diagnose";
CM_ SG_ 64 AB_EDR_Trigger "Triggerbedingung zur dezentralen Aufzeichnung unfallrelevanter Daten im Event Data Recorder";
CM_ SG_ 64 AB_Erh_Auf_VB "Der Fahrer soll bei einem Statuswechsel des Beifahrerairbags (ausgelöst durch die Beifahrerinsassenerkennung oder den Schlüsselschloßschalter) aufmerksam gemacht werden durch eine Anzeige im Kombi. Nur Audi: gültig für: AB2 (4-Türer AU352), B7, C6, D3";
CM_ SG_ 64 AB_Front_Crash "Bit wird bei Überschreitung der Gurtstraffer-, US- und RdW-Schwelle gesetzt";
CM_ SG_ 64 AB_Gurtwarn_VB "Beifahrer hat Gurt nicht gesteckt, Anzeige im Kombi";
CM_ SG_ 64 AB_Gurtwarn_VF "Fahrer hat Gurt nicht gesteckt, Anzeige im Kombi";
CM_ SG_ 64 AB_Heck_Crash "Wird für alle neu anlaufenden Projekte umgesetzt: AB8.4, Audi8/VW8";
CM_ SG_ 64 AB_Lampe "Sicherheitswarnlampe im Kombi wird vom Airbag-SG angesteuert; Zustand der Lampe wird auf dem CAN-Bus ausgegeben (auch Blinkinformation).";
CM_ SG_ 64 AB_MKB_Anforderung "Anforderung Multi-Kollisions-Bremsung";
CM_ SG_ 64 AB_MKB_gueltig "Multi-Kollisions-Bremsung im Airbag freigeschaltet";
CM_ SG_ 64 AB_RGS_Anst "PreCrash-Ansteuerung reversibler Gurtstraffer (Aktivierung und Kraftniveau)

10xx = deaktiviert";
CM_ SG_ 64 AB_Rollover_Crash "Wird im B6/B7 Cabrio und New Beetle Cabrio bedient. ";
CM_ SG_ 64 AB_SB_Crash "Z.Zt. nur in Verbindung mit Crash-Intensität >= 100b (Kraftstoffpumpenabschaltung) verwendet.
";
CM_ SG_ 64 AB_SF_Crash "Z.Zt. nur in Verbindung mit Crash-Intensität >= 100b (Kraftstoffpumpenabschaltung) verwendet.";
CM_ SG_ 64 AB_Stellgliedtest "Information, ob Airbag im Stellgliedtest ist, um eine Notrufauflösung beim Stellgliedtest zu verhindern";
CM_ SG_ 64 AB_Systemfehler "Systemfehler Ggf. wird Warnlampe dauernd eingeschaltet.";
CM_ SG_ 64 AB_Texte_AKS "Textanzeige für pyrotechnische Auslösung der aktiven Kopfstütze (AKS)";
CM_ SG_ 64 AB_VB_deaktiviert "Als Option vorgehalten, Beifahrerairbag wurden per Schlüsselschalter oder Insassenerkennung deaktiviert";
CM_ SG_ 64 AB_Versorgungsspannung "Übertragung der Plausibilitätsinformation Kl.15-Last vs. Kl.15-CAN.
Bedienung im Fall Kl.15-Last 'EIN' und Kl.15-CAN 'AUS' mit Ausgabe Warnung/Akustik im Kombi.";
CM_ SG_ 64 Airbag_01_CRC "Für MLB:
'Berechnung siehe Lastenheft 'Kommunikationsabsicherung für FlexRay und CAN''

Ab MQB und MLBevo:
'Berechnung siehe Lastenheft 'End-to-End Kommunikationsabsicherung''

Endwerte siehe Begleitdokument 'S-PDU Kennungsfolgen'";
CM_ SG_ 64 SC_LowSpeedCrashErkannt "Crash erkannt bei niedriger Geschwindigkeit";
CM_ SG_ 64 SC_Masterzeit "Masterzeit für alle Objektlisten";
CM_ SG_ 64 SC_Masterzeit_Offset "Erweiterung des Signals SC_Masterzeit um zwei höherwertige Bits, so dass ein Zeitbereich von ~20s (statt 5s) abgedeckt werden kann. Der aus SC_Masterzeit_Offset und SC_Masterzeit zu bildende Zeitstempel wird für die Synchronisation von Ereignissen der Fun";

CM_ SG_ 1312 AB_Abschaltanf_SIH_BF "Die Insassenerkennung auf der Beifahrerseite fordert bei Übertemperatur eine Abschaltung der Sitzheizung an. Die Übertemperatur kann bei niederohmigen Nebenschlüssen der Sitzheizungsmatte als Folge von zu hohem resultierenden Strom auftreten.";
CM_ SG_ 1312 AB_Anforderung_eCall "Trigger für Car2X Steuergerät das ein eCall Ereignis erkannt wurde.";
CM_ SG_ 1312 AB_Anforderung_USM "Trigger für Gateway (OBDC) und MIB/MMI, dass ein USM-Ereignis erkannt wurde.";
CM_ SG_ 1312 AB_Anprall_FGS "Uebermittlung der Lage einer Kollision, Fussgaengerschutz-Aktorik";
CM_ SG_ 1312 AB_Anprall_Front_Beifahrer "Uebermittlung der Lage einer Kollision, Anprallzone Front Beifahrerseite";
CM_ SG_ 1312 AB_Anprall_Front_Fahrer "Uebermittlung der Lage einer Kollision, Anprallzone Front Fahrerseite";
CM_ SG_ 1312 AB_Anprall_Heck_Beifahrer "Uebermittlung der Lage einer Kollision, Anprallzone Beifahrerseite hinten";
CM_ SG_ 1312 AB_Anprall_Heck_Fahrer "Uebermittlung der Lage einer Kollision, Anprallzone Fahrerseite hinten";
CM_ SG_ 1312 AB_Anprall_Rollover "Uebermittlung der Lage einer Kollision, Rollover erkannt";
CM_ SG_ 1312 AB_Anprall_Seite_Beifahrer "Uebermittlung der Lage einer Kollision, Anprallzone Beifahrerseite Seite";
CM_ SG_ 1312 AB_Anprall_Seite_Fahrer "Uebermittlung der Lage einer Kollision, Anprallzone Fahrerseite Seite";
CM_ SG_ 1312 AB_Belegung_VB "Belegungserkennung vorne Beifahrer. Wird in US-Steuergeräten über Bladder-Matte bedient, optional bei RdW, falls SBE_EuroNCAP entschieden wird.";
CM_ SG_ 1312 AB_Crashschwere "Übermittlung der Crashschwere an das Gateway (OBDC)";
CM_ SG_ 1312 AB_Gurtschloss_BF "Gurtschlossstatus Beifahrerseite";
CM_ SG_ 1312 AB_Gurtschloss_FA "Gurtschlosstatatus Fahrerseite";
CM_ SG_ 1312 AB_Gurtschloss_Reihe2_BF "Gurtschlossstatus 2. Reihe Beifahrerseite,  Mehrausstattung";
CM_ SG_ 1312 AB_Gurtschloss_Reihe2_FA "Gurtschlossstatus 2. Reihe Fahrerseite, Mehrausstattung";
CM_ SG_ 1312 AB_Gurtschloss_Reihe2_MI "Gurtschlossstatus 2. Reihe Mitte,  Mehrausstattung";
CM_ SG_ 1312 AB_Gurtschloss_Reihe3_BF "Gurtschlossstatus 3. Reihe Beifahrerseite,  Mehrausstattung";
CM_ SG_ 1312 AB_Gurtschloss_Reihe3_FA "Gurtschlossstatus 3. Reihe Fahrerseite,  Mehrausstattung";
CM_ SG_ 1312 AB_Gurtschloss_Reihe3_MI "Gurtschlossstatus 3. Reihe Mitte,  Mehrausstattung";
CM_ SG_ 1312 AB_Sitzpos_Sens_BF "Ausgabe Sitzposition Beifahrer";
CM_ SG_ 1312 AB_Sitzpos_Sens_FA "Ausgabe Sitzposition Fahrer";
CM_ SG_ 1312 AB_Wickelklappung_Reihe2_BF "Status Wickelklappung 2. Reihe Beifahrerseite, Mehrausstattung";
CM_ SG_ 1312 AB_Wickelklappung_Reihe2_FA "Status Wickelklappung 2. Reihe Fahrerseite, Mehrausstattung";
CM_ SG_ 1312 AB_Wickelklappung_Reihe2_MI "Status Wickelklappung 2. Reihe Mitte, Mehrausstattung";
CM_ SG_ 1312 Airbag_02_CRC "Für MLB:
'Berechnung siehe Lastenheft 'Kommunikationsabsicherung für FlexRay und CAN''

Ab MQB und MLBevo:
'Berechnung siehe Lastenheft 'End-to-End Kommunikationsabsicherung''

Endwerte siehe Begleitdokument 'S-PDU Kennungsfolgen'";
CM_ SG_ 1312 LoGeWa_Event_Kombiwarnung "Event für Kombiwarnung";
CM_ SG_ 1312 SC_PAO_OFF_Anf "Sollwert für LED 'OFF' in Anzeige Passenger Airbag On/Off";
CM_ SG_ 1312 SC_PAO_ON_Anf "Sollwert für LED 'ON' in Anzeige Passenger Airbag On/Off";
CM_ SG_ 1312 SC_PAO_Schriftzug_Anf "Sollwert für LED 'PASSENGER AIRBAG' in Anzeige Passenger Airbag On/Off";

CM_ SG_ 2536705796 BAP_BC_ASG_05_Header "BC Anzeigesteuergeraet";

CM_ SG_ 2536720128 BAP_ConnectionMngr_ASG_01_Header "ConnectionMngr Anzeigesteuergeraet";

CM_ SG_ 2536720129 BAP_ConnectionMngr_ASG_02_Header "ConnectionMngr Anzeigesteuergeraet";

CM_ SG_ 2536720130 BAP_ConnectionMngr_ASG_03_Header "ConnectionMngr Anzeigesteuergerät";

CM_ SG_ 2536720144 BAP_ConnectionMngr_FSG_01_Header "ConnectionMngr Funktionssteuergeraet";

CM_ SG_ 2589283629 BCM_DC_Batterie_Status "Batteriestatus des Drivercard Schlüssels";
CM_ SG_ 2589283629 BCM_DC_erkannt "Rückmeldung gefundene Drivercard ID";
CM_ SG_ 2589283629 BCM_DC_ID "Rückmeldung einer gefundenen Drivercard (Transponder ID)
gekoppelt
BCM_St_Suche_Drivercard_ID
";
CM_ SG_ 2589283629 BCM_DC_Suchvorgang_Status "Rückmeldung Status/Fehlerfall für Drivercardsuche";

CM_ SG_ 961 APS_LED_Status "Das Signal beschreibt den Zustand der APS LED für die Einparkhilfe, die im MLBevo vom BCM1 oder LIN Schalterleiste (BCM1 Slave) angesteuert wird.";
CM_ SG_ 961 APS_Taster "Das Signal beschreibt den Zustand der Taste, die im MLBevo vom BCM1 eingelesen wird.";
CM_ SG_ 961 AVH_LED_Status "Das Signal beschreibt den Zustand der AVH LED, die im MLBevo vom BCM1 oder LIN Schalterleiste (BCM1 Slave) angesteuert wird.
";
CM_ SG_ 961 AVH_Taster "Das Signal beschreibt den Zustand der AVH Taste, die im MLBevo vom BCM1 eingelesen wird.
";
CM_ SG_ 961 Display_Taster "Taster für Display Klappung";
CM_ SG_ 961 Drivesel_1_Taster "Taster 1 für Drive Select Betätigung";
CM_ SG_ 961 Drivesel_2_Taster "Taster 2 für Drive Select Betätigung";
CM_ SG_ 961 eCall_Taste "Status der eCall-Taste. 
(Emergency Call / SOS Hilferuf)";
CM_ SG_ 961 ESP_Off_Taster "Das Signal beschreibt den Zustand der ESP Taste, die im MLBevo vom BCM1 eingelesen wird.
";
CM_ SG_ 961 HDC_LED_Status "Das Signal beschreibt den Zustand der HDC LED, die im MLBevo vom BCM1 oder LIN Schalterleiste (BCM1 Slave) angesteuert wird.	";
CM_ SG_ 961 HDC_Taster "Das Signal beschreibt den Zustand der HDC Taste, die im MLBevo vom BCM1 eingelesen wird
0 = Taste nicht betätigt
1 = Taste entprellt betätigt
2 = Init oder Taste nicht verbaut
3 = Fehler";
CM_ SG_ 961 Heckrollo_2_Taster "Taster 2 für Heckrollo Betätigung";
CM_ SG_ 961 Heckrollo_Taster "Taster für Heckrollo Betätigung";
CM_ SG_ 961 LIM_bCall_Taster "Statusinformation des Service Call Tasters im Dachmodul";
CM_ SG_ 961 LIM_PAO_Alivesignal "Alive-Information zur Absicherung von Timeouterkennung bei Routing über mehrere Bussegmente";
CM_ SG_ 961 LIM_PAO_OFF_Status "Istwert für LED 'OFF' in Anzeige Passenger Airbag On/Off";
CM_ SG_ 961 LIM_PAO_ON_Status "Istwert für LED 'ON' in Anzeige Passenger Airbag On/Off";
CM_ SG_ 961 LIM_PAO_Schriftzug_Status "Istwert für LED 'PASSENGER AIRBAG' in Anzeige Passenger Airbag On/Off";
CM_ SG_ 961 LKS_Taster "Taste zum de-/aktivieren der Funktion LKS (Lane Keeping System)

0 - Taste nicht betätigt
1 - Taste betätigt
2 - INIT oder Taste nicht verbaut
3 - Fehler (Timeout, hängender Taster)";
CM_ SG_ 961 PLA_LED_Status "Das Signal beschreibt den Zustand der PLA LED, die im MLBevo vom BCM1 oder LIN Schalterleiste (BCM1 Slave) angesteuert wird.";
CM_ SG_ 961 PLA_Taster "Das Signal beschreibt den Zustand der PLA (Parklenkassisten) Taste, die im MLBevo vom BCM1 eingelesen wird.";
CM_ SG_ 961 PLA_Taster_Fehler_Roh "PLA Taster Fehlerstatus als ungefiltertes Signal für eine schnelle Fehlererkennung und Verarbeitung im IPA";
CM_ SG_ 961 Sideview_Taster "Taster für SIDEVIEW Betätigung";
CM_ SG_ 961 Spoiler_LED_Status "Status der Funktions LED SPOILER Ein/Ausfahren.";
CM_ SG_ 961 Spoiler_Taster "Taster für SPOILER Betätigung";
CM_ SG_ 961 SWA_Taster "SWA Taster vom BCM1 (quelle LDS)";

CM_ SG_ 870 Blinken_li_Fzg_Takt "Fzg-Takt Blinker links

";
CM_ SG_ 870 Blinken_li_Kombi_Takt "Kombi-Takt Blinker links

";
CM_ SG_ 870 Blinken_re_Fzg_Takt "Fzg-Takt Blinker rechts

";
CM_ SG_ 870 Blinken_re_Kombi_Takt "Kombi-Takt Blinker rechts

";
CM_ SG_ 870 BM_Autobahn "Status Autobahnblinken
";
CM_ SG_ 870 BM_Crash "Status Crashblinken
";
CM_ SG_ 870 BM_DWA_Alarm "Status DWA-Alarmblinken
";
CM_ SG_ 870 BM_DWA_ein "Status Quittierungsblinken DWA";
CM_ SG_ 870 BM_GDO "Blinken bei UGDO anlernen

";
CM_ SG_ 870 BM_HD_Oeffnung_angelernt "HD_Rueckmeld_prog eine Blinkerquittierung wird beim BCM2 angefordert.
Wenn die Geschwindigkeit kleiner einer vorgegebenen Schwelle (default 2km/h) ist wird das Signal BM_HD_Öffnung_angelernt versendet und die Blinkerquittierung ausgelöst";
CM_ SG_ 870 BM_links "Richtungsblinken links

";
CM_ SG_ 870 BM_NBA_n_codiert_n_aktiv "Notbremsanzeige nicht codiert/nicht aktiv (Fehler)";
CM_ SG_ 870 BM_NBA_Status "Notbremsanzeige Status nicht aktiv / BRL Dunkelphase / BRL Hellphase";
CM_ SG_ 870 BM_Not_Bremsung "Das Signal BM_Not_Bremsung  zeigt an,  ob ein Warnblinken aufgrund einer vom Bremssystem signalisierten Notbremsung aktiv ist.";
CM_ SG_ 870 BM_Panik "Panikblinken
";
CM_ SG_ 870 BM_PiloPa "Quittierungsblinken bei pilotierten Parkvorgängen";
CM_ SG_ 870 BM_Recas "Blinkermodus RECAS  (RearEndCollisionAlertSignal)";
CM_ SG_ 870 BM_rechts "Richtungsblinken rechts

";
CM_ SG_ 870 BM_Rollenmodus_Blinken "Das Signal wird statisch gesetzt, wenn die Blinkerart Rollenmodus_Blinken aktiv ist.";
CM_ SG_ 870 BM_Taxi_Notalarm "Blinken bei Taxi-Not-Alarm

";
CM_ SG_ 870 BM_Telematik "Telematikblinken
";
CM_ SG_ 870 BM_Telematik_Abbruchgrund "Gibt bei erwaretem aber ausbleibendem Flankenanstieg der BM_Telematik an wieso die Ausführung verhindert wurde. Bei Flankenabfall der BM_Telematik wird angegeben wieso die Ausführung beendet wurde.

Bei nicht bereitem Sender soll 'init' gesendet werden,";
CM_ SG_ 870 BM_Warnblinken "Warnblinken

";
CM_ SG_ 870 BM_WBT_Beleuchtung "Aktivierung Warnblinktasterfunktionsbeleuchtung
Warnblinktasterfunktionsbeleuchtung soll aktiviert werden (statisch auf 1)";
CM_ SG_ 870 BM_Wischblinken "Blinkermodus Wisch_Blinken";
CM_ SG_ 870 BM_ZV_auf "Blinken bei ZV auf

";
CM_ SG_ 870 BM_ZV_zu "Blinken bei ZV zu

";
CM_ SG_ 870 DWA_Alarmquelle "Signalisiert den Auslösegrund der DWA";

CM_ SG_ 1714 DGN_Verlernzaehler "wrap around 254 --> 0";
CM_ SG_ 1714 KBI_Kilometerstand "Fehler wird ausgegeben, falls Kilometerstand nicht restaurierbar
";
CM_ SG_ 1714 UH_Minute "0x3C- 0x3f = Werte ungültig";
CM_ SG_ 1714 UH_Monat "0x0D, 0xF =  Werte ungültig
0x0E = Relatives Datum (nur VW)";
CM_ SG_ 1714 UH_Sekunde "0x3C- 0x3f = Werte ungültig";
CM_ SG_ 1714 UH_Stunde "0x18 - 0x1F = Werte ungültig";
CM_ SG_ 1714 UH_Tag "0x0: reserviert bei VW";
CM_ SG_ 1714 Uhrzeit_01_alt "
";

CM_ SG_ 1520 BCM1_Stellgroesse_Kl_58s "Rohwert Dimmpoti";
CM_ SG_ 1520 DI_Display_Nachtdesign "Für Displays sind oft  automatische Umschaltungen von Tag-/Nachtdesign vorgesehen.
Es gibt jedoch Zustände, an denen auch tagsüber das Abblendlicht eingeschaltet ist.
z.B. Dauerfahrlicht, Geschwindigkeitsabhängiges 'Licht-An-Bei-Autobahn', 'Regenlicht',";
CM_ SG_ 1520 DI_Fotosensor "Helligkeitswert Fotosensor
Für die Dimmung relevanter Wert zur Sensierung der Umgebungshelligkeit
Im Detail beschrieben im 'Funktionslastenheft Dimmung MQB'.";
CM_ SG_ 1520 DI_KL_58xd "Klemme 58xd Display- und Funktionsbeleuchtung
Mit der Klemme 58xd wird die Helligkeit der Display- und der Funktionsbeleuchtungen der Schalter gesteuert.
Im Detail beschrieben im 'Funktionslastenheft Dimmung MQB'.";
CM_ SG_ 1520 DI_KL_58xs "Suchbeleuchtung Schalter
EIN-AUS-Schaltalgorithmus der allgemeinen Schaltersuchbeleuchtung. 
Im Detail beschrieben im 'Funktionslastenheft Dimmung MQB'.
";
CM_ SG_ 1520 DI_KL_58xt "Timergesteuerte Suchbeleuchtung
Der EIN-AUS-Schaltalgorithmus für die vor- und nachlaufende Schaltersuchbeleuchtungen beim Ein- & Aussteigen; z.B.: Start/Stop-Taster.
Im Detail beschrieben im 'Funktionslastenheft Dimmung MQB'.";

CM_ SG_ 2589283628 VTS_Anf_DC_Suche "Anforderung Drivercardsuche";
CM_ SG_ 2589283628 VTS_Anf_DC_Suche_ID "Anforderung der zu suchenden Driver Card (Transponder ID) ";
CM_ SG_ 2589283628 VTS_DC_ID "Übergabe der zu suchenden Drivercard (Transponder ID)
gekoppelt an VTS_Anf_Suche_Drivercard_ID (Multiplexer)";

CM_ SG_ 420 EA_01_BZ "EA Botschaftszähler
Botschaft asynchron geroutet. Zählerwert kann springen.";
CM_ SG_ 420 EA_01_CRC "Ab MQB und MLBevo:
'Berechnung siehe Lastenheft 'End-to-End Kommunikationsabsicherung''";
CM_ SG_ 420 EA_Anforderung_HMS "Emergency Assist Anforderung an HMS";
CM_ SG_ 420 EA_eCall_Anf "Emergency Assist Anforderung eCall";
CM_ SG_ 420 EA_Funktionsstatus "Emergency Assist Funktionsstatus";
CM_ SG_ 420 EA_Gurtstraffer_Anf "Emergency Assist Anforderung reversibler Gurtstraffer";
CM_ SG_ 420 EA_Parken_beibehalten_HMS "Anforderung um automatisches lösen der Parkbremse zu verhindern";
CM_ SG_ 420 EA_Sollbeschleunigung "Emergency Assist Beschleunigungsanforderung";
CM_ SG_ 420 EA_Warnruckprofil "Emergency Assist Anforderung an ESP, welcher Ruck verwendet werden soll.";

CM_ SG_ 2589283655 ConBox_T3_Status "Status des Timers T3";
CM_ SG_ 2589283655 ConBox_T6_Status "Status des Timers T6";
CM_ SG_ 2589283655 eCall2_Funktionsstatus "HMI-Aufruf im Kombi (Broadcast)
Fehlerfälle die im Kombi angezeigt werden können";
CM_ SG_ 2589283655 eCall2_Funktionsstatus_02 "Erweiterung des Funktionsstatus für andere Funktionen
ACN aktiv, MEC aktiv
MEC = manual emergency call = maueller Notruf
ACN = automatic emergency call = automatischer Notruf";
CM_ SG_ 2589283655 eCall2_Mute_Anf "Signalisiert die Aufforderungen alle Soundquellen im Fahrzeug während eines aktiven Notrufs zu muten";
CM_ SG_ 2589283655 eCall2_Statuslicht_Farbe1 "Steuerung Statuslicht (Farbe1) für Funktionsrückmeldungen Emergency Call / SOS Hilferuf,
z.B. LED-Anzeige im Dachmodul.";
CM_ SG_ 2589283655 eCall2_Statuslicht_Farbe2 "Steuerung Statuslicht (Farbe2) für Funktionsrückmeldungen Emergency Call / SOS Hilferuf,
z.B. LED-Anzeige im Dachmodul.";
CM_ SG_ 2589283655 eCall2_Subscription "Anzeige 'Service Unsubscribed' im Kombi - Aktualisierte Namensgebung";

CM_ SG_ 1603 KBI_Einheit_Datum "Anzeigevariante des Datums";
CM_ SG_ 1603 KBI_Einheit_Druck "Einheit des Druckes";
CM_ SG_ 1603 KBI_Einheit_Masse "Einheit der Masse (Verwendung z.B. ASTA)";
CM_ SG_ 1603 KBI_Einheit_Sprache "Siehe BAP-Datenfestlegung UnitMaster";
CM_ SG_ 1603 KBI_Einheit_Streckenanz "Einheit der Streckenanzeige";
CM_ SG_ 1603 KBI_Einheit_Temp "Einheit der Temperatur";
CM_ SG_ 1603 KBI_Einheit_Uhrzeit "Anzeigevariante der Uhrzeit";
CM_ SG_ 1603 KBI_Einheit_Verbrauch "Einheit der Verbrauchs";
CM_ SG_ 1603 KBI_Einheit_Verbrauch_elektr "Einheit elektrischer Verbrauch";
CM_ SG_ 1603 KBI_Einheit_Verbrauch_Gas "Unterscheidung zwischen M3/h und kg/h für Komfortverbrauchsberechnung.";
CM_ SG_ 1603 KBI_Einheit_Volumen "Einheit des Volumens";
CM_ SG_ 1603 KBI_MFA_v_Einheit_02 "Einheit der Geschwindigkeit, die vom Fahrer im Car-Menü gewählt wurde. Veränderliche Grösse, im Gegensatz zur Einheit des Tachokranzes.

Redundant in der Einheiten_01 Botschaft definiert, um Konsistenz zur BAP-Festlegung zu haben.";

CM_ SG_ 259 ESP_03_CRC "Ab MQB und MLBevo:
'Berechnung siehe Lastenheft 'End-to-End Kommunikationsabsicherung''

Endwerte siehe Begleitdokument 'S-PDU Kennungsfolgen'";
CM_ SG_ 259 ESP_HL_FR "Fahrtrichtungserkennung Rad Hinten Links
";
CM_ SG_ 259 ESP_HL_Radgeschw "Radgeschwindigkeit hinten links";
CM_ SG_ 259 ESP_HR_FR "Fahrtrichtungserkennung Rad Hinten Rechts
";
CM_ SG_ 259 ESP_HR_Radgeschw "Radgeschwindigkeit hinten rechts";
CM_ SG_ 259 ESP_VL_FR "Fahrtrichtungserkennung Rad Vorne Links
";
CM_ SG_ 259 ESP_VL_Radgeschw "Radgeschwindigkeit vorne links";
CM_ SG_ 259 ESP_VR_FR "Fahrtrichtungserkennung Rad Vorne Rechts

";
CM_ SG_ 259 ESP_VR_Radgeschw "Radgeschwindigkeit vorne rechts";

CM_ SG_ 278 ESP_10_BZ "Botschaftszähler

Wird im Projekt D4 und D4Hybrid nicht verwendet!  Wird im D4 PA verwendet
Botschaft asynchron geroutet. Zählerwert kann springen.";
CM_ SG_ 278 ESP_10_CRC "Für MLB:
'Berechnung siehe Lastenheft 'Kommunikationsabsicherung für FlexRay und CAN''

Ab MQB und MLBevo:
'Berechnung siehe Lastenheft 'End-to-End Kommunikationsabsicherung''

Endwerte siehe Begleitdokument 'S-PDU Kennungsfolgen'

Wird im Projekt";
CM_ SG_ 278 ESP_HL_Fahrtrichtung "Drehrichtung Rad HL

Weiterführende Informationen im Lastenheft spezifiziert und in der entsprechenden Fachabteilung zu erfragen.

Wird im Projekt D4 und D4Hybrid nicht verwendet!  Wird im D4 PA verwendet";
CM_ SG_ 278 ESP_HR_Fahrtrichtung "Drehrichtung Rad HR

Weiterführende Informationen im Lastenheft spezifiziert und in der entsprechenden Fachabteilung zu erfragen.

Wird im Projekt D4 und D4Hybrid nicht verwendet!  Wird im D4 PA verwendet";
CM_ SG_ 278 ESP_QBit_Wegimpuls_HL "Qualifizierungsbit Wegimpulszähler HL

Wird im Projekt D4 und D4Hybrid nicht verwendet!  Wird im D4 PA verwendet";
CM_ SG_ 278 ESP_QBit_Wegimpuls_HR "Qualifizierungsbit Wegimpulszähler HR

Wird im Projekt D4 und D4Hybrid nicht verwendet!  Wird im D4 PA verwendet";
CM_ SG_ 278 ESP_QBit_Wegimpuls_VL "Qualifizierungsbit Wegimpulszähler VL

Wird im Projekt D4 und D4Hybrid nicht verwendet!  Wird im D4 PA verwendet";
CM_ SG_ 278 ESP_QBit_Wegimpuls_VR "Qualifizierungsbit Wegimpulszähler VR

Wird im Projekt D4 und D4Hybrid nicht verwendet!  Wird im D4 PA verwendet";
CM_ SG_ 278 ESP_VL_Fahrtrichtung "Drehrichtung Rad VL

Weiterführende Informationen im Lastenheft spezifiziert und in der entsprechenden Fachabteilung zu erfragen.

Wird im Projekt D4 und D4Hybrid nicht verwendet!  Wird im D4 PA verwendet";
CM_ SG_ 278 ESP_VR_Fahrtrichtung "Drehrichtung Rad VR

Weiterführende Informationen im Lastenheft spezifiziert und in der entsprechenden Fachabteilung zu erfragen.

Wird im Projekt D4 und D4Hybrid nicht verwendet!  Wird im D4 PA verwendet";
CM_ SG_ 278 ESP_Wegimpuls_HL "Wegimpulszähler HL.
Anzahl der Wegimpulse Hinterrad links (steigende und fallende Flanke)
Zähler läuft grundsätzlich vorwärts, auch bei Rückwärtsfahrt.
Nach SG-Reset ist immer, ohne Ausnahme, 1mal der Init Wert 1021 zu senden.

Wird im Projekt D4 und";
CM_ SG_ 278 ESP_Wegimpuls_HR "Wegimpulszähler HR.
Anzahl der Wegimpulse Hinterrad rechts (steigende und fallende Flanke)
Zähler läuft grundsätzlich vorwärts, auch bei Rückwärtsfahrt.
Nach SG-Reset ist immer, ohne Ausnahme, 1mal der Init Wert 1021 zu senden.

Wird im Projekt D4 un";
CM_ SG_ 278 ESP_Wegimpuls_VL "Wegimpulszähler VL.
Anzahl der Wegimpulse Vorderrad links (steigende und fallende Flanke)
Zähler läuft grundsätzlich vorwärts, auch bei Rückwärtsfahrt.
Nach SG-Reset ist immer, ohne Ausnahme, 1mal der Init Wert 1021 zu senden.

Wird im Projekt D4 und";
CM_ SG_ 278 ESP_Wegimpuls_VR "Wegimpulszähler VR.
Anzahl der Wegimpulse Vorderrad rechts (steigende und fallende Flanke)
Zähler läuft grundsätzlich vorwärts, auch bei Rückwärtsfahrt.
Nach SG-Reset ist immer, ohne Ausnahme, 1mal der Init Wert 1021 zu senden.

Wird im Projekt D4 un";

CM_ SG_ 1629 BR_QBit_Reifenumfang "Gesetzt bei Ersatzwert, Init oder Fehler.";
CM_ SG_ 1629 BR_Reifenumfang "Mittlerer Radumfang gerechnet in Millimeter.
Von der Bremse plausibilisierter Wert (Kopie von KBI_Reifenumfang wenn dieser plausibel) oder Ersatzwert aus Bremse wenn KBI_Reifenumfang unplausibel. Bitte das QBit beachten!

Im MEB wird das Signal KBI_Rei";
CM_ SG_ 1629 BR_Systemart "Identifikation des verbauten Bremssystems

Dient dem Kombi zur Plausibilisierung";
CM_ SG_ 1629 ESP_20_BZ "Botschaft asynchron geroutet. Zählerwert kann springen.";
CM_ SG_ 1629 ESP_20_CRC "Für MLB:
'Berechnung siehe Lastenheft 'Kommunikationsabsicherung für FlexRay und CAN''

Ab MQB und MLBevo:
'Berechnung siehe Lastenheft 'End-to-End Kommunikationsabsicherung''

Endwerte siehe Begleitdokument 'S-PDU Kennungsfolgen'";
CM_ SG_ 1629 ESP_Charisma_FahrPr "MLBevo: Aktuelles Fahrprogramm des Charisma-Teilnehmers (siehe Systemlastenheft Drive Select)
MQB: Istwert der Kennlinie (siehe Systemlastenheft MQB FPA)";
CM_ SG_ 1629 ESP_Charisma_Status "Systemstatus des Charismateilnehmers

Wert 0x3 ist nur für Fahrzeuge ab MQB relevant";
CM_ SG_ 1629 ESP_Dachrelingsensor "Erkennung auf Verbau des Dachrelingsensors und Dachquerträger.";
CM_ SG_ 1629 ESP_SpannungsAnf_02 "Forderung des ESP-SG's zur Spannungsanhebung.";
CM_ SG_ 1629 ESP_Stoppverbot_Anz_01 "Dieses Signal gibt die detaillierte Begründung für ein Stoppverbot vom Bremsensteuergerät an.";
CM_ SG_ 1629 ESP_Stoppverbot_Anz_02 "Dieses Signal gibt die detaillierte Begründung für ein Stoppverbot vom Bremsensteuergerät an.";
CM_ SG_ 1629 ESP_Stoppverbot_Anz_03 "Dieses Signal gibt die detaillierte Begründung für ein Stoppverbot vom Bremsensteuergerät an.";
CM_ SG_ 1629 ESP_Stoppverbot_Anz_04 "Dieses Signal gibt die detaillierte Begründung für ein Stoppverbot vom Bremsensteuergerät an.";
CM_ SG_ 1629 ESP_Stoppverbot_Anz_05 "Dieses Signal gibt die detaillierte Begründung für ein Stoppverbot vom Bremsensteuergerät an.";
CM_ SG_ 1629 ESP_Stoppverbot_Anz_06 "Dieses Signal gibt die detaillierte Begründung für ein Stoppverbot vom Bremsensteuergerät an.";
CM_ SG_ 1629 ESP_Stoppverbot_Anz_07 "Dieses Signal gibt die detaillierte Begründung für ein Stoppverbot vom Bremsensteuergerät an.";
CM_ SG_ 1629 ESP_Stoppverbot_Anz_08 "Dieses Signal gibt die detaillierte Begründung für ein Stoppverbot vom Bremsensteuergerät an.";
CM_ SG_ 1629 ESP_Stoppverbot_Anz_Std "Dieses Signal gibt die detaillierte Begründung für ein Stoppverbot vom Bremsensteuergerät an.";
CM_ SG_ 1629 ESP_Wiederstart_Anz_01 "Dieses Signal gibt die detaillierte Begründung für einen Wiederstart vom Bremsensteuergerät an. ";
CM_ SG_ 1629 ESP_Wiederstart_Anz_02 "Dieses Signal gibt die detaillierte Begründung für einen Wiederstart vom Bremsensteuergerät an. ";
CM_ SG_ 1629 ESP_Wiederstart_Anz_03 "Dieses Signal gibt die detaillierte Begründung für einen Wiederstart vom Bremsensteuergerät an. ";
CM_ SG_ 1629 ESP_Wiederstart_Anz_04 "Dieses Signal gibt die detaillierte Begründung für einen Wiederstart vom Bremsensteuergerät an.";
CM_ SG_ 1629 ESP_Zaehnezahl "Konstanter Wert der Zähnezahl des verwendeten Impulsrades wird ausgegeben, jeder Empfänger der Wegimpulse muss die Zähnezahl einlesen, um eine volle Umdrehung des Rades zu erkennen. 

Weiterführende Informationen im Lastenheft spezifiziert und in der en";
CM_ SG_ 1629 HDC_Charisma_FahrPr "MLBevo: Aktuelles Fahrprogramm des Charisma-Teilnehmers (siehe Systemlastenheft Drive Select)
MQB: Istwert der Kennlinie (siehe Systemlastenheft MQB FPA)";
CM_ SG_ 1629 HDC_Charisma_Status "Systemstatus des Charismateilnehmers

Wert 0x3 ist nur für Fahrzeuge ab MQB relevant";

CM_ SG_ 253 ABS_Bremsung "Antiblockiersystem, Bit zeigt auch Druckabbau an (z.B. ESP hat zuviel Druck aufgebaut oder ungebremste Regelung auf Bahnübergang)
Weiterführende Informationen im Lastenheft spezifiziert und in der entsprechenden Fachabteilung zu erfragen.";
CM_ SG_ 253 ASR_Anf "MLB: Die Momentenanforderung 'ASR_MSR_Moment_schnell' und 'ASR_Moment_langsam' sind auszuführen
MQB: Die Momentenanforderung 'BR_Eingriffsmoment' ist auszuführen";
CM_ SG_ 253 ASR_Schalteingriff "Wunsch an das Getriebe während einer ASR Regelung

MLB: Es wird nur 0x0 und 0x1 genutzt

";
CM_ SG_ 253 ASR_Tastung_passiv "ASR deaktiviert oder Schwellen geändert (projektabhängig)
Weiterführende Informationen im Lastenheft spezifiziert und in der entsprechenden Fachabteilung zu erfragen.
";
CM_ SG_ 253 BR_Eingriffsmoment "Einheitenloser Wert! Faktor in MO_Faktor_Momente_02 in Motor_Code_01 beachten!
Schnelle reduzierende (ASR) oder erhöhende (MSR) Momentanforderung an den Motor.";
CM_ SG_ 253 EBV_Eingriff "Elektronische Bremskraftverteilung, aktueller Eingriff (Druckhalten, Druckabbau)

Im MLB: kein ABS / ESP-Eingriff ???";
CM_ SG_ 253 EDS_Eingriff "Elektronische Differentialsperre";
CM_ SG_ 253 ESC_Neutralschaltung "Aufforderung seitens ABS an das Getriebe die Momentenübertragung zu unterbrechen";
CM_ SG_ 253 ESC_v_Signal_Qualifier_High_Low "Das Qualifizerungssignal ESC_v_Signal_Qualifier_High_Low gibt eine Information über die Güte der vom Bremsregelsystem ausgegebenen Geschwindigkeitsinformation 'mittlere Geschwindigkeit', wobei Vertrauensbereiche für das ausgegebene Geschwindigkeitssignal ";
CM_ SG_ 253 ESP_21_BZ "Botschaft asynchron geroutet. Zählerwert kann springen.";
CM_ SG_ 253 ESP_21_CRC "Für MLB:
'Berechnung siehe Lastenheft 'Kommunikationsabsicherung für FlexRay und CAN''

Ab MQB und MLBevo:
'Berechnung siehe Lastenheft 'End-to-End Kommunikationsabsicherung''

Endwerte siehe Begleitdokument 'S-PDU Kennungsfolgen'";
CM_ SG_ 253 ESP_ASP "MLB: Anhaenger-Stabilisierungs-Programm
MQB: Gespannstabilisierung";
CM_ SG_ 253 ESP_Diagnose "MLB: Nach Diagnoseende wird ein SW-Reset ausgelöst welcher einen Kommunikatiosausfall für max. 150ms verursacht. Dies ist bei SG mit verschärfter Timeoutüberwachung (nicht nach Konzern-LH) zu beachten.

MQB: Weiterführende Informationen im Lastenheft sp";
CM_ SG_ 253 ESP_Eingriff "Eingriff des Fahrdynamikreglers";
CM_ SG_ 253 ESP_QBit_v_Signal "Geschwindigkeit wird vom ABS/ASR oder ESP aus Ersatzwerten errechnet, wenn Bit gesetzt ist. Güte des Signals ist verändert.";
CM_ SG_ 253 ESP_Systemstatus "Fehler steht für Stillegung ESP mit Fehlereintrag.

MLB: Flag wird bei Unterspannung im Stand bis einmalig 6km/h (AU48x) oder 10 km/h (AU641, AU57x) überschritten nicht gesetzt (Ausblendung Startvorgang)
Im AU64x, AU57x gilt ESP D4 Funktionsanforderung";
CM_ SG_ 253 ESP_Tastung_passiv "ESP deaktiviert oder Schwellen geändert (projektabhängig)
Weiterführende Informationen im Lastenheft spezifiziert und in der entsprechenden Fachabteilung zu erfragen.";
CM_ SG_ 253 ESP_v_Signal "Geschwindigkeitssignal vom ABS/ASR oder ESP. Mittelwert der angetriebenen Räder.
Bei MSR oder ABS Eingriffen wird die ABS-Referenzgeschwindigkeit für >= 200ms eingespiegelt (Zeit wird mit Aktiv-Flanke der Funktionsbits getriggert)

MQB: Bei Frontantrie";
CM_ SG_ 253 ESP_Vorsteuerung "zur Unterscheidung zwischen ESP-Vorsteuermaßnahmen und ESP-Regeleingriffen";
CM_ SG_ 253 MSR_Anf "MLB: Die Momentenanforderung 'ASR_MSR_Moment_schnell' ist auszuführen.
MQB: Die Momentenanforderung 'BR_Eingriffsmoment' ist auszuführen";
CM_ SG_ 253 MSR_verfuegbar "Anzeige Verfügbarkeit der MSR Funktion 
0 = verfuegbar (MSR_Vollsystem oder MSR_Backup)
1 = nicht_verfuegbar (Init und Fehler)";
CM_ SG_ 253 OBD_Schlechtweg "Für Ausblendung der Zündaussetzererkennung im Motorsteuergerät (Otto). Bit wird gesetzt, wenn Rad-Drehbeschleunigung im ESP > Grenzwert ist. Vorteil gegenüber Radgeschwindigkeiten, dass ESP alle 2 ms dynamisch die Rad-Drehbeschleunigung errechnet und dem ";

CM_ SG_ 508 ESC_Anforderung_Airbrake "ESC fordert die Bremsperformancestellung der aktiven Aerodynamik";
CM_ SG_ 508 ESC_FBA_Meldungen "Hinweis an den Fahrer über das Kombi, bei dauerhafter Bergabfahrt einen Gang einzulegen um die Motorbremse zu nutzen.
Unterscheidung zwischen: 
Handschalterfahrzeugen (FBA_Warnung_aktiv_MT)
Automatikfahrzeugen (FBA_Warnung_aktiv_AT)";
CM_ SG_ 508 ESC_MBK_Meldungen "Das Signal steuert die Schaltempfehlung im Kombi, die bei Bergabfahrt den Fahrer darauf hinweist in eine geeignete Fahrstufe zu schalten um eine Rekuperation zu ermöglichen.";
CM_ SG_ 508 ESC_Motorstartverzoegerung "Mit dem Signal 'Motorstartverzögerung' wird den aktiven Teilnehmern ermöglicht, einen Motorstart durch die Start-Stop-Funktion zu verzögern.";
CM_ SG_ 508 ESP_32_BZ "Botschaft asynchron geroutet. Zählerwert kann springen.";
CM_ SG_ 508 ESP_32_CRC "Für MLB:
'Berechnung siehe Lastenheft 'Kommunikationsabsicherung für FlexRay und CAN''

Ab MQB und MLBevo:
'Berechnung siehe Lastenheft 'End-to-End Kommunikationsabsicherung''

Endwerte siehe Begleitdokument 'S-PDU Kennungsfolgen'";
CM_ SG_ 508 ESP_Aggregataktivitaet "Info über die Aktivität des ESP Aggregats bei aktivem Druckaufbau oder Ventilaktivität";
CM_ SG_ 508 ESP_AVH_LED "Ansteuerung der AVH Funktions-LED durch das BCM.
0 = LED aus
1 = LED ein
2 = LED blinken
3 = Funktion gesperrt, LED aus
4 = frei
5 = frei
6 = Init
7 = frei";
CM_ SG_ 508 ESP_EDS_Anzeige "Grafische Anzeige der EDS-Funktion im Kombiinstrument und MMI für Bentley";
CM_ SG_ 508 ESP_HDC_LED "Ansteuerung der HDC LED in der Schalterleiste durch BCM
0 = LED aus
1 = LED ein
2 = LED blinken
3 = Funktion gesperrt, LED aus
4 = frei
5 = frei
6 = Init
7 = frei";
CM_ SG_ 508 ESP_HDC_Textanzeigen "Textanzeigen der HDC im Kombiinstrument
Zustände 16,17,18 nur für Porsche";
CM_ SG_ 508 ESP_HOLD_verf "Das Signal ESP_HOLD_verf = 1 signalisiert dem Empfänger, dass die Aktivierungsbedingungen für die autonome HOLD-Funktion erfüllt sind (Steigung > parametrierbare Grenzsteigung mit Wunschfahrtrichtung bergauf) und die autonome HOLD-Funktion aktivierbar ist";
CM_ SG_ 508 ESP_Notbremsanzeige "ABS/ASR oder ESP hat Notbremssituation erkannt.
Weiterführende Informationen im Lastenheft spezifiziert und in der entsprechenden Fachabteilung zu erfragen.

";
CM_ SG_ 508 ESP_Off_LED "Ansteuerung der ESP-Off LED in der Schalterleiste durch BCM
0 = LED aus
1 = LED ein
2 = LED blinken
3 = Funktion gesperrt, LED aus
4 = frei
5 = frei
6 = Init
7 = frei";
CM_ SG_ 508 ESP_Offroad_Lampe "Anzeige der ESC-Offroad-Lampe im Kombiinstrument für Bentley";
CM_ SG_ 508 ESP_Rollover_Status_dyn "Information vom ESP an die Dämpferregelung über den dynamischen Rolloverstatus";
CM_ SG_ 508 ESP_Rollover_Status_stat "Information vom ESP an die Dämpferregelung über den statischen Rolloverstatus";
CM_ SG_ 508 ESP_Status_Bremsentemp_02 "Bremsscheibentemperaturmodell. Rückmeldung für Sender einer Verzögerungsanforderung";
CM_ SG_ 508 ESP_Stillstandsflag "Bei RB-Projekten wird das Stillstandsflag gesetzt, wenn der absolute Stillstand der Raddrehzahlsensoren erkannt wurde, d.h. kein Zahn bewegt sich mehr. Dieses Bit wird bspw. im MOST für TV-Tuner-Abschaltung Australien verwendet, d.h. leichte Erschütterung";
CM_ SG_ 508 ESP_Wiederstart_Anz_Std "Dieses Signal gibt die detaillierte Begründung für einen Wiederstart vom Bremsensteuergerät ausgelöst durch die HBC Funktion an.";
CM_ SG_ 508 RLE_Anzeigen "Anzeigen für die Radlöseerkennung";

CM_ SG_ 2549875590 FoD_OTA_FC_Req_Data "Function on demand request an OTA-FC";

CM_ SG_ 2550006662 FoD_OTA_FC_Resp_Data "Function on demand response vom OTA-FC";

CM_ SG_ 879 GNSS_Breite_Ortung "Breitengrad des Ortungsergebnisses nach WGS84 als Kombination von mehreren GNSSen";
CM_ SG_ 879 GNSS_Fehlerzustand "Fehlerzustand von der GNSS-Funktion, daraufhin können keine GNSS-Daten geliefert werden";
CM_ SG_ 879 GNSS_Laenge_Ortung "Längengrad des Ortungsergebnisses nach WGS84 als Kombination von mehreren GNSSen";
CM_ SG_ 879 GNSS_Nachrichtenpaket_ID1 "+1 für jedes neue Paket. Zyklische ID-Vergabe (Zähler). Zur Identifizierung zusammenhängender Nachrichten, die die Daten derselben GNSS-Ortung enthalten und somit zum selben Zyklus gehören. D.h. Daten in den Nachrichten wurden zur selben Zeit erzeugt. Der";
CM_ SG_ 879 GNSS_Ortung_FIX_Typ "Art des 'GNSS-Fix' für die aktuelle Position auf Basis mehrerer GNSS Systeme.";
CM_ SG_ 879 GNSS_Richtung_Breite_Ortung "Richtung des Breitengrads des Ortungsergebnisses nach WGS84 als Kombination von mehreren GNSSen";
CM_ SG_ 879 GNSS_Richtung_Laenge_Ortung "Richtung des Längengrads des Ortungsergebnisses nach WGS84 als Kombination von mehreren GNSSen";

CM_ SG_ 884 GNSS_Nachrichtenpaket_ID2 "+1 für jedes neue Paket. Zyklische ID-Vergabe (Zähler). Zur Identifizierung zusammenhängender Nachrichten, die die Daten derselben GNSS-Ortung enthalten und somit zum selben Zyklus gehören. D.h. Daten in den Nachrichten wurden zur selben Zeit erzeugt. Der";
CM_ SG_ 884 GNSS_Ortung_2D_Geschw_ue_Grund "Geschwindigkeit in m pro Sekunde entsprechend dem GNSS-Empfänger";
CM_ SG_ 884 GNSS_Ortung_Ausrichtung "Ausrichtung (Kurswinkel) der GNSS-Messung";
CM_ SG_ 884 GNSS_Ortung_Latenz "Latenz zwischen GNSS-Messung und aktueller Verteilung über CAN-Bus.
Hinweis: Zur Stabilisierung der Latenz soll die GNSS-Zeit für die Bestimmung der CAN-Zyklendauer verwendet werden.";
CM_ SG_ 884 GNSS_Ortung_Noerdliche_Geschw "Geschwindigkeit in m pro Sekunde in Nordrichtung entsprechend dem GNSS-Empfänger";
CM_ SG_ 884 GNSS_Ortung_Oestliche_Geschw "Geschwindigkeit in m pro Sekunde in Ostrichtung entsprechend dem GNSS-Empfänger";
CM_ SG_ 884 GNSS_Ortung_Vertikale_Geschw "Geschwindigkeit  in m pro Sekunde in vertikaler Richtung (aufwärts) entsprechend dem GNSS-Empfänger";

CM_ SG_ 886 GNSS_Nachrichtenpaket_ID3 "+1 für jedes neue Paket. Zyklische ID-Vergabe (Zähler). Zur Identifizierung zusammenhängender Nachrichten, die die Daten derselben GNSS-Ortung enthalten und somit zum selben Zyklus gehören. D.h. Daten in den Nachrichten wurden zur selben Zeit erzeugt. Der";
CM_ SG_ 886 GNSS_Ortung_GDOP "Synthetischer Wert für den Verlust an Präzision der Postions- und Zeitmessung auf Grund der Satellitenkonstellation";
CM_ SG_ 886 GNSS_Ortung_Guete_Ausrichtung "Gesamtgenauigkeit bezüglich der Ausrichtung (Kurswinkel)";
CM_ SG_ 886 GNSS_Ortung_Guete_Geschwindigk "Gesamtgenauigkeit bezüglich Geschwindigkeit am Erdboden";
CM_ SG_ 886 GNSS_Ortung_Guete_horizontal "Gesamtgenauigkeit bezüglich der 2D-Position (horzontal)";
CM_ SG_ 886 GNSS_Ortung_Guete_vertikal "Gesamtgenauigkeit bezüglich der 1D-Position (vertikal)";
CM_ SG_ 886 GNSS_Ortung_HDOP "Synthetischer Wert für den Verlust an Präzision der 2D-Postionsmessung (horizontal) auf Grund der Satellitenkonstellation";
CM_ SG_ 886 GNSS_Ortung_PDOP "Synthetischer Wert für den Verlust an Präzision der Postionsmessung auf Grund der Satellitenkonstellation";
CM_ SG_ 886 GNSS_Ortung_VDOP "Synthetischer Wert für den Verlust an Präzision der 1D-Postionsmessung (vertikal) auf Grund der Satellitenkonstellation";

CM_ SG_ 888 GNSS_Nachrichtenpaket_ID4 "+1 für jedes neue Paket. Zyklische ID-Vergabe (Zähler). Zur Identifizierung zusammenhängender Nachrichten, die die Daten derselben GNSS-Ortung enthalten und somit zum selben Zyklus gehören. D.h. Daten in den Nachrichten wurden zur selben Zeit erzeugt. Der";
CM_ SG_ 888 GNSS_Ortung_Hoehe "Höhe über dem Meeresspiegel";
CM_ SG_ 888 GNSS_Ortung_Zeit_in_GPSWoche "Zeitstempel für die Jitter-Prüfung aso. Zeit muss sychron zur Zeit der GNSS-Ortung sein.";

CM_ SG_ 891 GNSS_Empfaenger_Status "Im 'Backup Mode' wird z.B. die UTC Zeit durch eine gepufferte 'Realtime Clock' bereitgestellt.
Im 'Live Mode' wird die UTC Zeit durch das GNSS Modul bereitgestellt. ";
CM_ SG_ 891 GNSS_Empfangbare_Satelliten "Anzahl der Satelliten, welche bei der aktuellen Satellitenkonfiguration ptentiell verfügbar sind";
CM_ SG_ 891 GNSS_Genutzte_Satelliten "Anzahl der Satelliten, welche für die aktuelle Ortung verwendet werden";
CM_ SG_ 891 GNSS_GLONASS_in_Nutzung "1: das genannte GNSS wurde für die Ortung verwendet";
CM_ SG_ 891 GNSS_GPS_in_Nutzung "1: das genannte GNSS wurde für die Ortung verwendet";
CM_ SG_ 891 GNSS_Nachrichtenpaket_ID5 "+1 für jedes neue Paket. Zyklische ID-Vergabe (Zähler). Zur Identifizierung zusammenhängender Nachrichten, die die Daten derselben GNSS-Ortung enthalten und somit zum selben Zyklus gehören. D.h. Daten in den Nachrichten wurden zur selben Zeit erzeugt. Der";
CM_ SG_ 891 GNSS_Sichtbare_Satelliten "Anzahl der Satelliten, welche aktuell empfangen werden";
CM_ SG_ 891 GNSS_UTC_Zeit "UTC-Zeit, Sekunden seit dem 01.01.1970 00:00";

CM_ SG_ 1364 GNSS_Nachrichtenpaket_ID6 "+1 für jedes neue Paket. Zyklische ID-Vergabe (Zähler). Zur Identifizierung zusammenhängender Nachrichten, die die Daten derselben GNSS-Ortung enthalten und somit zum selben Zyklus gehören. D.h. Daten in den Nachrichten wurden zur selben Zeit erzeugt. Der";
CM_ SG_ 1364 GNSS_Sat_Info_Azimuth_ID_1 "Azimut des Satelliten";
CM_ SG_ 1364 GNSS_Sat_Info_Hoehenwinkel_ID_1 "Höhenwinkel des Satelliten";
CM_ SG_ 1364 GNSS_Sat_Info_Sat_ID_1 "ID des Satelliten";
CM_ SG_ 1364 GNSS_Sat_Info_SNR_ID_1 "Signal-Rausch-Verhältnis des Satelliten";

CM_ SG_ 2463978722 GNSS_DR_Breite_Ortung "Dead Reckoning Breitengrad des Ortungsergebnisses nach WGS84 als Kombination von mehreren GNSSen";
CM_ SG_ 2463978722 GNSS_DR_Laenge_Ortung "Dead Reckoning Längengrad des Ortungsergebnisses nach WGS84 als Kombination von mehreren GNSSen";
CM_ SG_ 2463978722 GNSS_DR_Nachrichtenpaket_ID1 "+1 für jedes neue Paket. Zyklische ID-Vergabe (Zähler). Zur Identifizierung zusammenhängender Nachrichten, die die Daten derselben GNSS-Ortung enthalten und somit zum selben Zyklus gehören. D.h. Daten in den Nachrichten wurden zur selben Zeit erzeugt. Der";
CM_ SG_ 2463978722 GNSS_DR_Richtung_Breite_Ortung "Dead Reckoning Richtung des Breitengrads des Ortungsergebnisses nach WGS84 als Kombination von mehreren GNSSen";
CM_ SG_ 2463978722 GNSS_DR_Richtung_Laenge_Ortung "Dead Reckoning Richtung des Längengrads des Ortungsergebnisses nach WGS84 als Kombination von mehreren GNSSen";

BA_DEF_  "DBName" STRING;
BA_DEF_  "GenNWMApBusSleep" STRING;
BA_DEF_  "GenNWMApCanNormal" STRING;
BA_DEF_  "GenNWMApCanOff" STRING;
BA_DEF_  "GenNWMApCanOn" STRING;
BA_DEF_  "GenNWMApCanSleep" STRING;
BA_DEF_  "GenNWMApCanWakeUp" STRING;
BA_DEF_  "GenNWMGotoMode_Awake" STRING;
BA_DEF_  "GenNWMGotoMode_BusSleep" STRING;
BA_DEF_  "GenNWMSleepTime" INT 0 1000000;
BA_DEF_  "GenNWMTalkNM" STRING;
BA_DEF_  "Manufacturer" STRING;
BA_DEF_  "NmhBaseAddress" HEX 0 536870911;
BA_DEF_  "NmhMessageCount" INT 0 1024;
BA_DEF_  "NmType" STRING;
BA_DEF_  "VAGTP20_SetupMessageCount" INT 0 255;
BA_DEF_  "VAGTP20_SetupStartAddress" HEX 0 2047;
BA_DEF_  "VersionDay" INT 1 31;
BA_DEF_  "VersionMonth" INT 1 12;
BA_DEF_  "VersionWeek" INT 1 52;
BA_DEF_  "VersionYear" INT 0 99;
BA_DEF_  "VersionNumber" INT 0 65535;
BA_DEF_  "BusType" STRING;
BA_DEF_  "Baudrate" INT 1 1000000;
BA_DEF_  "SamplePointMin" INT 1 100;
BA_DEF_  "SamplePointMax" INT 1 100;
BA_DEF_  "SyncJumpWidthMin" INT 1 4;
BA_DEF_  "SyncJumpWidthMax" INT 1 4;
BA_DEF_  "NBTMin" INT 1 30;
BA_DEF_  "NBTMax" INT 1 30;
BA_DEF_  "NmhTimeoutTimer" INT 0 65535;
BA_DEF_  "NmhWaitBusSleepTimer" INT 0 65535;
BA_DEF_  "NmhPrepareBusSleepTimer" INT 0 65535;
BA_DEF_  "NmhLongTimer" INT 0 65535;
BA_DEF_  "NmhNStart" INT 0 255;
BA_DEF_ BU_  "GenNodAutoGenDsp" ENUM "No", "Yes";
BA_DEF_ BU_  "GenNodAutoGenSnd" ENUM "No", "Yes";
BA_DEF_ BU_  "GenNodSleepTime" INT 0 1000000;
BA_DEF_ BU_  "ILUsed" ENUM "No", "Yes";
BA_DEF_ BU_  "ECUVariantDefault" ENUM "No", "Yes";
BA_DEF_ BU_  "ECUVariantGroup" STRING;
BA_DEF_ BU_  "NodeLayerModules" STRING;
BA_DEF_ BU_  "NmhNode" ENUM "No", "Yes";
BA_DEF_ BU_  "NmNode" ENUM "No", "Yes";
BA_DEF_REL_ BU_SG_REL_  "GenSigTimeoutTime" INT 0 65535;
BA_DEF_ BO_  "DiagRequest" ENUM "No", "Yes";
BA_DEF_ BO_  "DiagResponse" ENUM "No", "Yes";
BA_DEF_ BO_  "DiagState" ENUM "No", "Yes";
BA_DEF_ BO_  "GenMsgChkConstant" HEX 0 4095;
BA_DEF_ BO_  "GenMsgCycleTime" INT 0 65535;
BA_DEF_ BO_  "GenMsgCycleTimeFast" INT 0 65535;
BA_DEF_ BO_  "GenMsgDelayTime" INT 0 100000;
BA_DEF_ BO_  "GenMsgILSupport" ENUM "No", "Yes";
BA_DEF_ BO_  "GenMsgNrOfRepetition" INT 0 100;
BA_DEF_ BO_  "GenMsgPDUConstants" STRING;
BA_DEF_ BO_  "GenMsgSendType" ENUM "Cyclic", "not_used", "not_used", "not_used", "not_used", "not_used", "not_used", "IfActive", "NoMsgSendType";
BA_DEF_ BO_  "GenMsgStartDelayTime" INT 0 100000;
BA_DEF_ BO_  "NmMessage" ENUM "No", "Yes";
BA_DEF_ BO_  "NmhMessage" ENUM "No", "Yes";
BA_DEF_ BO_  "MsgType" ENUM "Application", "NM ", "NMH", "TP2.0", "ISO-TP ", "BAP", "EID", "KS", "XCP_PRE_CONFIGURED", "XCP_RUNTIME_CONFIGURED";
BA_DEF_ BO_  "VAGTP20_API" HEX 0 255;
BA_DEF_ BO_  "VAGTP20_DynConnection" ENUM "No", "Yes";
BA_DEF_ BO_  "VAGTP20_DynSetup" ENUM "No", "Yes";
BA_DEF_ BO_  "VAGTP20_StatConnection" ENUM "No", "Yes";
BA_DEF_ SG_  "GenSigActiveRepetitions" INT -2147483648 2147483647;
BA_DEF_ SG_  "GenSigSendType" ENUM "Cyclic", "OnWrite", "OnWriteWithRepetition", "OnChange", "OnChangeWithRepetition", "IfActive", "IfActiveWithRepetition", "NoSigSendType", "OnChangeAndIfActive", "OnChangeAndIfActiveWithRepetition";
BA_DEF_ SG_  "GenSigStartValue" INT -2147483648 2147483647;
BA_DEF_ SG_  "NWM-WakeupAllowed" ENUM "No", "Yes";
BA_DEF_ SG_  "GenSigFuncType" ENUM "NoFunction", "MsgCounter", "CRC-8", "XOR", "XOR-2", "DatedBit", "SW-Kl15", "CHK", "Constant", "Protocol", "CRC-8-SAE_J1850", "CRC-32", "DataLength", "DataID", "MsgCounter16", "SOK-Signatur", "Cluster";
BA_DEF_ SG_  "GenSigSwitchedByIgnition" ENUM "No", "Yes";
BA_DEF_ SG_  "Fehlerwert" HEX 0 2147483647;
BA_DEF_ SG_  "GenSigMissingSourceValue" HEX 0 2147483647;
BA_DEF_DEF_  "DBName" "";
BA_DEF_DEF_  "GenNWMApBusSleep" "";
BA_DEF_DEF_  "GenNWMApCanNormal" "";
BA_DEF_DEF_  "GenNWMApCanOff" "";
BA_DEF_DEF_  "GenNWMApCanOn" "";
BA_DEF_DEF_  "GenNWMApCanSleep" "";
BA_DEF_DEF_  "GenNWMApCanWakeUp" "";
BA_DEF_DEF_  "GenNWMGotoMode_Awake" "";
BA_DEF_DEF_  "GenNWMGotoMode_BusSleep" "";
BA_DEF_DEF_  "GenNWMSleepTime" 0;
BA_DEF_DEF_  "GenNWMTalkNM" "";
BA_DEF_DEF_  "Manufacturer" "";
BA_DEF_DEF_  "NmhBaseAddress" 0;
BA_DEF_DEF_  "NmhMessageCount" 1;
BA_DEF_DEF_  "NmType" "None";
BA_DEF_DEF_  "VAGTP20_SetupMessageCount" 0;
BA_DEF_DEF_  "VAGTP20_SetupStartAddress" 0;
BA_DEF_DEF_  "VersionDay" 2;
BA_DEF_DEF_  "VersionMonth" 6;
BA_DEF_DEF_  "VersionWeek" 23;
BA_DEF_DEF_  "VersionYear" 22;
BA_DEF_DEF_  "VersionNumber" 0;
BA_DEF_DEF_  "BusType" "";
BA_DEF_DEF_  "Baudrate" 1;
BA_DEF_DEF_  "SamplePointMin" 1;
BA_DEF_DEF_  "SamplePointMax" 1;
BA_DEF_DEF_  "SyncJumpWidthMin" 1;
BA_DEF_DEF_  "SyncJumpWidthMax" 1;
BA_DEF_DEF_  "NBTMin" 10;
BA_DEF_DEF_  "NBTMax" 20;
BA_DEF_DEF_  "NmhTimeoutTimer" 0;
BA_DEF_DEF_  "NmhWaitBusSleepTimer" 0;
BA_DEF_DEF_  "NmhPrepareBusSleepTimer" 0;
BA_DEF_DEF_  "NmhLongTimer" 0;
BA_DEF_DEF_  "NmhNStart" 0;
BA_DEF_DEF_  "GenNodAutoGenDsp" "Yes";
BA_DEF_DEF_  "GenNodAutoGenSnd" "Yes";
BA_DEF_DEF_  "GenNodSleepTime" 0;
BA_DEF_DEF_  "ILUsed" "Yes";
BA_DEF_DEF_  "ECUVariantDefault" "Yes";
BA_DEF_DEF_  "ECUVariantGroup" "";
BA_DEF_DEF_  "NodeLayerModules" "";
BA_DEF_DEF_  "NmhNode" "Yes";
BA_DEF_DEF_  "NmNode" "No";
BA_DEF_DEF_REL_  "GenSigTimeoutTime" 0;
BA_DEF_DEF_  "DiagRequest" "No";
BA_DEF_DEF_  "DiagResponse" "No";
BA_DEF_DEF_  "DiagState" "No";
BA_DEF_DEF_  "GenMsgChkConstant" 0;
BA_DEF_DEF_  "GenMsgCycleTime" 0;
BA_DEF_DEF_  "GenMsgCycleTimeFast" 0;
BA_DEF_DEF_  "GenMsgDelayTime" 0;
BA_DEF_DEF_  "GenMsgILSupport" "No";
BA_DEF_DEF_  "GenMsgNrOfRepetition" 0;
BA_DEF_DEF_  "GenMsgPDUConstants" "";
BA_DEF_DEF_  "GenMsgSendType" "NoMsgSendType";
BA_DEF_DEF_  "GenMsgStartDelayTime" 0;
BA_DEF_DEF_  "NmMessage" "No";
BA_DEF_DEF_  "NmhMessage" "No";
BA_DEF_DEF_  "MsgType" "Application";
BA_DEF_DEF_  "VAGTP20_API" 0;
BA_DEF_DEF_  "VAGTP20_DynConnection" "No";
BA_DEF_DEF_  "VAGTP20_DynSetup" "No";
BA_DEF_DEF_  "VAGTP20_StatConnection" "No";
BA_DEF_DEF_  "GenSigActiveRepetitions" 0;
BA_DEF_DEF_  "GenSigSendType" "NoSigSendType";
BA_DEF_DEF_  "GenSigStartValue" 0;
BA_DEF_DEF_  "NWM-WakeupAllowed" "No";
BA_DEF_DEF_  "GenSigFuncType" "NoFunction";
BA_DEF_DEF_  "GenSigSwitchedByIgnition" "Yes";
BA_DEF_DEF_  "Fehlerwert" 0;
BA_DEF_DEF_  "GenSigMissingSourceValue" 0;
BA_  "DBName" "MLBevo_CCAN";
BA_  "GenNWMApBusSleep" "NMIndNetSDN()";
BA_  "GenNWMApCanNormal" "apCanNormal()";
BA_  "GenNWMApCanOff" "NMIndnetOff()";
BA_  "GenNWMApCanOn" "NMIndnetOn()";
BA_  "GenNWMApCanSleep" "apCanSleep()";
BA_  "GenNWMApCanWakeUp" "apCanWakeUp()";
BA_  "GenNWMGotoMode_Awake" "Nmh_ReqNetOn()";
BA_  "GenNWMGotoMode_BusSleep" "Nmh_ReqNetOff()";
BA_  "GenNWMSleepTime" 4000;
BA_  "GenNWMTalkNM" "Nmh_ReqNetOn()";
BA_  "Manufacturer" "VAG";
BA_  "NmhBaseAddress" 452984832;
BA_  "NmhMessageCount" 256;
BA_  "NmType" "NM-High";
BA_  "VAGTP20_SetupMessageCount" 128;
BA_  "VAGTP20_SetupStartAddress" 512;
BA_  "VersionNumber" 2400;
BA_  "BusType" "CAN";
BA_  "Baudrate" 500000;
BA_  "SamplePointMin" 80;
BA_  "SamplePointMax" 84;
BA_  "SyncJumpWidthMin" 2;
BA_  "SyncJumpWidthMax" 4;
BA_  "NmhTimeoutTimer" 1000;
BA_  "NmhWaitBusSleepTimer" 750;
BA_  "NmhPrepareBusSleepTimer" 500;
BA_  "NmhLongTimer" 200;
BA_  "NmhNStart" 20;
BA_ "GenNodSleepTime" BU_ BAP_Tester 4000;
BA_ "ECUVariantGroup" BU_ BAP_Tester "BAP";
BA_ "NmhNode" BU_ BAP_Tester 0;
BA_ "GenNodSleepTime" BU_ conBox 4000;
BA_ "ECUVariantGroup" BU_ conBox "OCU";
BA_ "NodeLayerModules" BU_ conBox "NMHigh.DLL";
BA_ "GenNodSleepTime" BU_ Gateway 4000;
BA_ "ECUVariantGroup" BU_ Gateway "Gateway";
BA_ "NodeLayerModules" BU_ Gateway "NMHigh.DLL";
BA_ "GenNodSleepTime" BU_ Gateway_PAG 4000;
BA_ "ECUVariantDefault" BU_ Gateway_PAG 0;
BA_ "ECUVariantGroup" BU_ Gateway_PAG "Gateway";
BA_ "NodeLayerModules" BU_ Gateway_PAG "NMHigh.DLL";
BA_ "GenNodSleepTime" BU_ OTA_FC 4000;
BA_ "ECUVariantGroup" BU_ OTA_FC "OTA_FC";
BA_ "NodeLayerModules" BU_ OTA_FC "NMHigh.DLL";
BA_ "GenMsgChkConstant" BO_ 64 64;
BA_ "GenMsgCycleTime" BO_ 64 40;
BA_ "GenMsgCycleTimeFast" BO_ 64 10;
BA_ "GenMsgDelayTime" BO_ 64 10;
BA_ "GenMsgILSupport" BO_ 64 1;
BA_ "GenMsgNrOfRepetition" BO_ 64 5;
BA_ "GenMsgPDUConstants" BO_ 64 "0x40,0x40,0x40,0x40,0x40,0x40,0x40,0x40,0x40,0x40,0x40,0x40,0x40,0x40,0x40,0x40";
BA_ "GenMsgSendType" BO_ 64 0;
BA_ "GenMsgChkConstant" BO_ 1312 68;
BA_ "GenMsgCycleTime" BO_ 1312 200;
BA_ "GenMsgDelayTime" BO_ 1312 20;
BA_ "GenMsgILSupport" BO_ 1312 1;
BA_ "GenMsgPDUConstants" BO_ 1312 "0x44,0x44,0x44,0x44,0x44,0x44,0x44,0x44,0x44,0x44,0x44,0x44,0x44,0x44,0x44,0x44";
BA_ "GenMsgSendType" BO_ 1312 0;
BA_ "MsgType" BO_ 2536705796 5;
BA_ "MsgType" BO_ 2536705808 5;
BA_ "MsgType" BO_ 2536720128 5;
BA_ "MsgType" BO_ 2536720129 5;
BA_ "MsgType" BO_ 2536720130 5;
BA_ "MsgType" BO_ 2536720144 5;
BA_ "MsgType" BO_ 2536767264 5;
BA_ "MsgType" BO_ 2536767280 5;
BA_ "MsgType" BO_ 2536715008 5;
BA_ "MsgType" BO_ 2536715024 5;
BA_ "GenMsgCycleTime" BO_ 2589283629 1000;
BA_ "GenMsgDelayTime" BO_ 2589283629 100;
BA_ "GenMsgILSupport" BO_ 2589283629 1;
BA_ "GenMsgSendType" BO_ 2589283629 0;
BA_ "GenMsgCycleTime" BO_ 961 200;
BA_ "GenMsgCycleTimeFast" BO_ 961 20;
BA_ "GenMsgDelayTime" BO_ 961 20;
BA_ "GenMsgILSupport" BO_ 961 1;
BA_ "GenMsgNrOfRepetition" BO_ 961 5;
BA_ "GenMsgSendType" BO_ 961 0;
BA_ "GenMsgCycleTime" BO_ 870 1000;
BA_ "GenMsgCycleTimeFast" BO_ 870 50;
BA_ "GenMsgDelayTime" BO_ 870 10;
BA_ "GenMsgILSupport" BO_ 870 1;
BA_ "GenMsgNrOfRepetition" BO_ 870 5;
BA_ "GenMsgSendType" BO_ 870 0;
BA_ "MsgType" BO_ 2617195008 6;
BA_ "MsgType" BO_ 2617195263 6;
BA_ "MsgType" BO_ 2616996608 6;
BA_ "MsgType" BO_ 2616996863 6;
BA_ "GenMsgCycleTime" BO_ 1714 1000;
BA_ "GenMsgILSupport" BO_ 1714 1;
BA_ "GenMsgSendType" BO_ 1714 0;
BA_ "GenMsgStartDelayTime" BO_ 1714 55;
BA_ "GenMsgCycleTime" BO_ 1520 200;
BA_ "GenMsgDelayTime" BO_ 1520 50;
BA_ "GenMsgILSupport" BO_ 1520 1;
BA_ "GenMsgSendType" BO_ 1520 0;
BA_ "GenMsgCycleTime" BO_ 2589283628 1000;
BA_ "GenMsgDelayTime" BO_ 2589283628 100;
BA_ "GenMsgILSupport" BO_ 2589283628 1;
BA_ "GenMsgSendType" BO_ 2589283628 0;
BA_ "GenMsgCycleTime" BO_ 420 500;
BA_ "GenMsgILSupport" BO_ 420 1;
BA_ "GenMsgPDUConstants" BO_ 420 "0x69,0xbb,0x54,0xe6,0x4e,0x46,0x8d,0x7b,0xea,0x87,0xe9,0xb3,0x63,0xce,0xf8,0xbf";
BA_ "GenMsgSendType" BO_ 420 0;
BA_ "GenMsgCycleTime" BO_ 2589283655 500;
BA_ "GenMsgDelayTime" BO_ 2589283655 50;
BA_ "GenMsgILSupport" BO_ 2589283655 1;
BA_ "GenMsgSendType" BO_ 2589283655 0;
BA_ "GenMsgCycleTime" BO_ 1603 1000;
BA_ "GenMsgDelayTime" BO_ 1603 100;
BA_ "GenMsgILSupport" BO_ 1603 1;
BA_ "GenMsgSendType" BO_ 1603 0;
BA_ "GenMsgChkConstant" BO_ 259 2;
BA_ "GenMsgCycleTime" BO_ 259 20;
BA_ "GenMsgILSupport" BO_ 259 1;
BA_ "GenMsgPDUConstants" BO_ 259 "0x02,0x02,0x02,0x02,0x02,0x02,0x02,0x02,0x02,0x02,0x02,0x02,0x02,0x02,0x02,0x02";
BA_ "GenMsgSendType" BO_ 259 0;
BA_ "GenMsgChkConstant" BO_ 278 172;
BA_ "GenMsgCycleTime" BO_ 278 50;
BA_ "GenMsgILSupport" BO_ 278 1;
BA_ "GenMsgPDUConstants" BO_ 278 "0xac,0xac,0xac,0xac,0xac,0xac,0xac,0xac,0xac,0xac,0xac,0xac,0xac,0xac,0xac,0xac";
BA_ "GenMsgSendType" BO_ 278 0;
BA_ "GenMsgCycleTime" BO_ 1629 160;
BA_ "GenMsgILSupport" BO_ 1629 1;
BA_ "GenMsgPDUConstants" BO_ 1629 "0xac,0xb3,0xab,0xeb,0x7a,0xe1,0x3b,0xf7,0x73,0xba,0x7c,0x9e,0x06,0x5f,0x02,0xd9";
BA_ "GenMsgSendType" BO_ 1629 0;
BA_ "GenMsgCycleTime" BO_ 253 20;
BA_ "GenMsgPDUConstants" BO_ 253 "0xb4,0xef,0xf8,0x49,0x1e,0xe5,0xc2,0xc0,0x97,0x19,0x3c,0xc9,0xf1,0x98,0xd6,0x61";
BA_ "GenMsgSendType" BO_ 253 0;
BA_ "GenMsgCycleTime" BO_ 508 200;
BA_ "GenMsgDelayTime" BO_ 508 20;
BA_ "GenMsgILSupport" BO_ 508 1;
BA_ "GenMsgPDUConstants" BO_ 508 "0x01,0x10,0x05,0xde,0xe0,0xdc,0x34,0xc4,0x8a,0xb1,0x6d,0x7b,0x62,0xef,0x1f,0x95";
BA_ "GenMsgSendType" BO_ 508 0;
BA_ "MsgType" BO_ 2549875590 4;
BA_ "MsgType" BO_ 2550006662 4;
BA_ "GenMsgCycleTime" BO_ 879 1000;
BA_ "GenMsgILSupport" BO_ 879 1;
BA_ "GenMsgSendType" BO_ 879 0;
BA_ "GenMsgCycleTime" BO_ 884 1000;
BA_ "GenMsgILSupport" BO_ 884 1;
BA_ "GenMsgSendType" BO_ 884 0;
BA_ "GenMsgCycleTime" BO_ 886 1000;
BA_ "GenMsgILSupport" BO_ 886 1;
BA_ "GenMsgSendType" BO_ 886 0;
BA_ "GenMsgCycleTime" BO_ 888 1000;
BA_ "GenMsgILSupport" BO_ 888 1;
BA_ "GenMsgSendType" BO_ 888 0;
BA_ "GenMsgCycleTime" BO_ 891 1000;
BA_ "GenMsgILSupport" BO_ 891 1;
BA_ "GenMsgSendType" BO_ 891 0;
BA_ "GenMsgCycleTime" BO_ 1364 1000;
BA_ "GenMsgILSupport" BO_ 1364 1;
BA_ "GenMsgSendType" BO_ 1364 0;
BA_ "GenMsgCycleTime" BO_ 2463978722 100;
BA_ "GenMsgILSupport" BO_ 2463978722 1;
BA_ "GenMsgSendType" BO_ 2463978722 0;
BA_ "GenSigSendType" SG_ 64 AB_Anzeige_Fussg 0;
BA_ "GenSigSwitchedByIgnition" SG_ 64 AB_Anzeige_Fussg 0;
BA_ "GenSigSendType" SG_ 64 AB_Belegung_VF 0;
BA_ "GenSigSwitchedByIgnition" SG_ 64 AB_Belegung_VF 0;
BA_ "Fehlerwert" SG_ 64 AB_Belegung_VF 1;
BA_ "GenSigActiveRepetitions" SG_ 64 AB_Crash_Int 5;
BA_ "GenSigSendType" SG_ 64 AB_Crash_Int 4;
BA_ "GenSigSwitchedByIgnition" SG_ 64 AB_Crash_Int 0;
BA_ "GenSigSendType" SG_ 64 AB_Deaktiviert 0;
BA_ "GenSigSwitchedByIgnition" SG_ 64 AB_Deaktiviert 0;
BA_ "GenSigActiveRepetitions" SG_ 64 AB_Deaktivierung_HV 5;
BA_ "GenSigSendType" SG_ 64 AB_Deaktivierung_HV 4;
BA_ "GenSigSwitchedByIgnition" SG_ 64 AB_Deaktivierung_HV 0;
BA_ "Fehlerwert" SG_ 64 AB_Deaktivierung_HV 7;
BA_ "GenSigSendType" SG_ 64 AB_Diagnose 0;
BA_ "GenSigSwitchedByIgnition" SG_ 64 AB_Diagnose 0;
BA_ "GenSigSendType" SG_ 64 AB_EDR_Trigger 3;
BA_ "GenSigSwitchedByIgnition" SG_ 64 AB_EDR_Trigger 0;
BA_ "GenSigSendType" SG_ 64 AB_Erh_Auf_VB 0;
BA_ "GenSigSwitchedByIgnition" SG_ 64 AB_Erh_Auf_VB 0;
BA_ "GenSigActiveRepetitions" SG_ 64 AB_Front_Crash 5;
BA_ "GenSigSendType" SG_ 64 AB_Front_Crash 4;
BA_ "GenSigSwitchedByIgnition" SG_ 64 AB_Front_Crash 0;
BA_ "GenSigSendType" SG_ 64 AB_Gurtwarn_VB 0;
BA_ "GenSigSwitchedByIgnition" SG_ 64 AB_Gurtwarn_VB 0;
BA_ "GenSigSendType" SG_ 64 AB_Gurtwarn_VF 0;
BA_ "GenSigSwitchedByIgnition" SG_ 64 AB_Gurtwarn_VF 0;
BA_ "GenSigActiveRepetitions" SG_ 64 AB_Heck_Crash 5;
BA_ "GenSigSendType" SG_ 64 AB_Heck_Crash 4;
BA_ "GenSigSwitchedByIgnition" SG_ 64 AB_Heck_Crash 0;
BA_ "GenSigSendType" SG_ 64 AB_Lampe 0;
BA_ "GenSigStartValue" SG_ 64 AB_Lampe 1;
BA_ "GenSigSwitchedByIgnition" SG_ 64 AB_Lampe 0;
BA_ "GenSigActiveRepetitions" SG_ 64 AB_MKB_Anforderung 5;
BA_ "GenSigSendType" SG_ 64 AB_MKB_Anforderung 4;
BA_ "GenSigSwitchedByIgnition" SG_ 64 AB_MKB_Anforderung 0;
BA_ "GenSigSendType" SG_ 64 AB_MKB_gueltig 0;
BA_ "GenSigSwitchedByIgnition" SG_ 64 AB_MKB_gueltig 0;
BA_ "GenSigSendType" SG_ 64 AB_RGS_Anst 0;
BA_ "GenSigStartValue" SG_ 64 AB_RGS_Anst 8;
BA_ "GenSigSwitchedByIgnition" SG_ 64 AB_RGS_Anst 0;
BA_ "GenSigActiveRepetitions" SG_ 64 AB_Rollover_Crash 5;
BA_ "GenSigSendType" SG_ 64 AB_Rollover_Crash 4;
BA_ "GenSigSwitchedByIgnition" SG_ 64 AB_Rollover_Crash 0;
BA_ "GenSigActiveRepetitions" SG_ 64 AB_SB_Crash 5;
BA_ "GenSigSendType" SG_ 64 AB_SB_Crash 4;
BA_ "GenSigSwitchedByIgnition" SG_ 64 AB_SB_Crash 0;
BA_ "GenSigActiveRepetitions" SG_ 64 AB_SF_Crash 5;
BA_ "GenSigSendType" SG_ 64 AB_SF_Crash 4;
BA_ "GenSigSwitchedByIgnition" SG_ 64 AB_SF_Crash 0;
BA_ "GenSigSendType" SG_ 64 AB_Stellgliedtest 0;
BA_ "GenSigSwitchedByIgnition" SG_ 64 AB_Stellgliedtest 0;
BA_ "GenSigSendType" SG_ 64 AB_Systemfehler 0;
BA_ "GenSigSwitchedByIgnition" SG_ 64 AB_Systemfehler 0;
BA_ "GenSigSendType" SG_ 64 AB_Texte_AKS 0;
BA_ "GenSigSwitchedByIgnition" SG_ 64 AB_Texte_AKS 0;
BA_ "GenSigSendType" SG_ 64 AB_VB_deaktiviert 0;
BA_ "GenSigStartValue" SG_ 64 AB_VB_deaktiviert 1;
BA_ "GenSigSwitchedByIgnition" SG_ 64 AB_VB_deaktiviert 0;
BA_ "GenSigSendType" SG_ 64 AB_Versorgungsspannung 0;
BA_ "GenSigSwitchedByIgnition" SG_ 64 AB_Versorgungsspannung 0;
BA_ "GenSigSendType" SG_ 64 Airbag_01_BZ 0;
BA_ "GenSigFuncType" SG_ 64 Airbag_01_BZ 1;
BA_ "GenSigSwitchedByIgnition" SG_ 64 Airbag_01_BZ 0;
BA_ "GenSigSendType" SG_ 64 Airbag_01_CRC 0;
BA_ "GenSigFuncType" SG_ 64 Airbag_01_CRC 2;
BA_ "GenSigSwitchedByIgnition" SG_ 64 Airbag_01_CRC 0;
BA_ "GenSigSendType" SG_ 64 SC_LowSpeedCrashErkannt 0;
BA_ "GenSigSwitchedByIgnition" SG_ 64 SC_LowSpeedCrashErkannt 0;
BA_ "GenSigSendType" SG_ 64 SC_Masterzeit 0;
BA_ "GenSigStartValue" SG_ 64 SC_Masterzeit 127;
BA_ "GenSigSendType" SG_ 64 SC_Masterzeit_Offset 0;
BA_ "GenSigSendType" SG_ 1312 AB_Abschaltanf_SIH_BF 3;
BA_ "GenSigSendType" SG_ 1312 AB_Anforderung_eCall 0;
BA_ "GenSigSwitchedByIgnition" SG_ 1312 AB_Anforderung_eCall 0;
BA_ "GenSigSendType" SG_ 1312 AB_Anforderung_USM 0;
BA_ "GenSigSwitchedByIgnition" SG_ 1312 AB_Anforderung_USM 0;
BA_ "GenSigSendType" SG_ 1312 AB_Anprall_FGS 3;
BA_ "GenSigSendType" SG_ 1312 AB_Anprall_Front_Beifahrer 3;
BA_ "GenSigSendType" SG_ 1312 AB_Anprall_Front_Fahrer 3;
BA_ "GenSigSendType" SG_ 1312 AB_Anprall_Heck_Beifahrer 3;
BA_ "GenSigSendType" SG_ 1312 AB_Anprall_Heck_Fahrer 3;
BA_ "GenSigSendType" SG_ 1312 AB_Anprall_Rollover 3;
BA_ "GenSigSendType" SG_ 1312 AB_Anprall_Seite_Beifahrer 3;
BA_ "GenSigSendType" SG_ 1312 AB_Anprall_Seite_Fahrer 3;
BA_ "GenSigSendType" SG_ 1312 AB_Belegung_VB 0;
BA_ "GenSigSwitchedByIgnition" SG_ 1312 AB_Belegung_VB 0;
BA_ "Fehlerwert" SG_ 1312 AB_Belegung_VB 1;
BA_ "GenSigSendType" SG_ 1312 AB_Crashschwere 3;
BA_ "GenSigSwitchedByIgnition" SG_ 1312 AB_Crashschwere 0;
BA_ "Fehlerwert" SG_ 1312 AB_Crashschwere 7;
BA_ "GenSigSendType" SG_ 1312 AB_Gurtschloss_BF 3;
BA_ "GenSigStartValue" SG_ 1312 AB_Gurtschloss_BF 1;
BA_ "GenSigSwitchedByIgnition" SG_ 1312 AB_Gurtschloss_BF 0;
BA_ "GenSigSendType" SG_ 1312 AB_Gurtschloss_FA 3;
BA_ "GenSigStartValue" SG_ 1312 AB_Gurtschloss_FA 1;
BA_ "GenSigSwitchedByIgnition" SG_ 1312 AB_Gurtschloss_FA 0;
BA_ "GenSigSendType" SG_ 1312 AB_Gurtschloss_Reihe2_BF 3;
BA_ "GenSigStartValue" SG_ 1312 AB_Gurtschloss_Reihe2_BF 1;
BA_ "GenSigSwitchedByIgnition" SG_ 1312 AB_Gurtschloss_Reihe2_BF 0;
BA_ "GenSigSendType" SG_ 1312 AB_Gurtschloss_Reihe2_FA 3;
BA_ "GenSigStartValue" SG_ 1312 AB_Gurtschloss_Reihe2_FA 1;
BA_ "GenSigSwitchedByIgnition" SG_ 1312 AB_Gurtschloss_Reihe2_FA 0;
BA_ "GenSigSendType" SG_ 1312 AB_Gurtschloss_Reihe2_MI 3;
BA_ "GenSigStartValue" SG_ 1312 AB_Gurtschloss_Reihe2_MI 1;
BA_ "GenSigSwitchedByIgnition" SG_ 1312 AB_Gurtschloss_Reihe2_MI 0;
BA_ "GenSigSendType" SG_ 1312 AB_Gurtschloss_Reihe3_BF 3;
BA_ "GenSigStartValue" SG_ 1312 AB_Gurtschloss_Reihe3_BF 1;
BA_ "GenSigSwitchedByIgnition" SG_ 1312 AB_Gurtschloss_Reihe3_BF 0;
BA_ "GenSigSendType" SG_ 1312 AB_Gurtschloss_Reihe3_FA 3;
BA_ "GenSigStartValue" SG_ 1312 AB_Gurtschloss_Reihe3_FA 1;
BA_ "GenSigSwitchedByIgnition" SG_ 1312 AB_Gurtschloss_Reihe3_FA 0;
BA_ "GenSigSendType" SG_ 1312 AB_Gurtschloss_Reihe3_MI 3;
BA_ "GenSigStartValue" SG_ 1312 AB_Gurtschloss_Reihe3_MI 1;
BA_ "GenSigSwitchedByIgnition" SG_ 1312 AB_Gurtschloss_Reihe3_MI 0;
BA_ "GenSigSendType" SG_ 1312 AB_Sitzpos_Sens_BF 0;
BA_ "GenSigSwitchedByIgnition" SG_ 1312 AB_Sitzpos_Sens_BF 0;
BA_ "Fehlerwert" SG_ 1312 AB_Sitzpos_Sens_BF 1;
BA_ "GenSigSendType" SG_ 1312 AB_Sitzpos_Sens_FA 0;
BA_ "GenSigSwitchedByIgnition" SG_ 1312 AB_Sitzpos_Sens_FA 0;
BA_ "Fehlerwert" SG_ 1312 AB_Sitzpos_Sens_FA 1;
BA_ "GenSigSendType" SG_ 1312 AB_Wickelklappung_Reihe2_BF 3;
BA_ "GenSigStartValue" SG_ 1312 AB_Wickelklappung_Reihe2_BF 1;
BA_ "GenSigSwitchedByIgnition" SG_ 1312 AB_Wickelklappung_Reihe2_BF 0;
BA_ "GenSigSendType" SG_ 1312 AB_Wickelklappung_Reihe2_FA 3;
BA_ "GenSigStartValue" SG_ 1312 AB_Wickelklappung_Reihe2_FA 1;
BA_ "GenSigSwitchedByIgnition" SG_ 1312 AB_Wickelklappung_Reihe2_FA 0;
BA_ "GenSigSendType" SG_ 1312 AB_Wickelklappung_Reihe2_MI 3;
BA_ "GenSigStartValue" SG_ 1312 AB_Wickelklappung_Reihe2_MI 1;
BA_ "GenSigSwitchedByIgnition" SG_ 1312 AB_Wickelklappung_Reihe2_MI 0;
BA_ "GenSigSendType" SG_ 1312 Airbag_02_BZ 0;
BA_ "GenSigFuncType" SG_ 1312 Airbag_02_BZ 1;
BA_ "GenSigSwitchedByIgnition" SG_ 1312 Airbag_02_BZ 0;
BA_ "GenSigSendType" SG_ 1312 Airbag_02_CRC 0;
BA_ "GenSigFuncType" SG_ 1312 Airbag_02_CRC 2;
BA_ "GenSigSwitchedByIgnition" SG_ 1312 Airbag_02_CRC 0;
BA_ "GenSigSendType" SG_ 1312 LoGeWa_Event_Kombiwarnung 3;
BA_ "GenSigSwitchedByIgnition" SG_ 1312 LoGeWa_Event_Kombiwarnung 0;
BA_ "GenSigSendType" SG_ 1312 SC_PAO_OFF_Anf 0;
BA_ "GenSigSwitchedByIgnition" SG_ 1312 SC_PAO_OFF_Anf 0;
BA_ "GenSigSendType" SG_ 1312 SC_PAO_ON_Anf 0;
BA_ "GenSigSwitchedByIgnition" SG_ 1312 SC_PAO_ON_Anf 0;
BA_ "GenSigSendType" SG_ 1312 SC_PAO_Schriftzug_Anf 0;
BA_ "GenSigSwitchedByIgnition" SG_ 1312 SC_PAO_Schriftzug_Anf 0;
BA_ "GenSigSendType" SG_ 2536705796 BAP_BC_ASG_05_Header 3;
BA_ "GenSigSwitchedByIgnition" SG_ 2536705796 BAP_BC_ASG_05_Header 0;
BA_ "GenSigSendType" SG_ 2536705808 BAP_BC_FSG_01_Header 3;
BA_ "GenSigSwitchedByIgnition" SG_ 2536705808 BAP_BC_FSG_01_Header 0;
BA_ "GenSigSendType" SG_ 2536720128 BAP_ConnectionMngr_ASG_01_Header 3;
BA_ "GenSigSwitchedByIgnition" SG_ 2536720128 BAP_ConnectionMngr_ASG_01_Header 0;
BA_ "GenSigSendType" SG_ 2536720129 BAP_ConnectionMngr_ASG_02_Header 3;
BA_ "GenSigSwitchedByIgnition" SG_ 2536720129 BAP_ConnectionMngr_ASG_02_Header 0;
BA_ "GenSigSendType" SG_ 2536720130 BAP_ConnectionMngr_ASG_03_Header 3;
BA_ "GenSigSwitchedByIgnition" SG_ 2536720130 BAP_ConnectionMngr_ASG_03_Header 0;
BA_ "GenSigSendType" SG_ 2536720144 BAP_ConnectionMngr_FSG_01_Header 3;
BA_ "GenSigSwitchedByIgnition" SG_ 2536720144 BAP_ConnectionMngr_FSG_01_Header 0;
BA_ "GenSigSendType" SG_ 2536767264 BAP_Debug_Cmd 3;
BA_ "GenSigSwitchedByIgnition" SG_ 2536767264 BAP_Debug_Cmd 0;
BA_ "GenSigSendType" SG_ 2536767280 BAP_Debug_Data 3;
BA_ "GenSigSwitchedByIgnition" SG_ 2536767280 BAP_Debug_Data 0;
BA_ "GenSigSendType" SG_ 2536715008 BAP_eCall_ASG_01_Header 3;
BA_ "GenSigSwitchedByIgnition" SG_ 2536715008 BAP_eCall_ASG_01_Header 0;
BA_ "GenSigSendType" SG_ 2536715024 BAP_eCall_FSG_01_Header 3;
BA_ "GenSigSwitchedByIgnition" SG_ 2536715024 BAP_eCall_FSG_01_Header 0;
BA_ "GenSigSendType" SG_ 2589283629 BCM_DC_Batterie_Status 3;
BA_ "GenSigSwitchedByIgnition" SG_ 2589283629 BCM_DC_Batterie_Status 0;
BA_ "GenSigSendType" SG_ 2589283629 BCM_DC_erkannt 3;
BA_ "GenSigSwitchedByIgnition" SG_ 2589283629 BCM_DC_erkannt 0;
BA_ "GenSigSendType" SG_ 2589283629 BCM_DC_ID 3;
BA_ "GenSigSwitchedByIgnition" SG_ 2589283629 BCM_DC_ID 0;
BA_ "GenSigSendType" SG_ 2589283629 BCM_DC_Suchvorgang_Status 3;
BA_ "GenSigSwitchedByIgnition" SG_ 2589283629 BCM_DC_Suchvorgang_Status 0;
BA_ "GenSigActiveRepetitions" SG_ 961 APS_LED_Status 5;
BA_ "GenSigSendType" SG_ 961 APS_LED_Status 4;
BA_ "GenSigSwitchedByIgnition" SG_ 961 APS_LED_Status 0;
BA_ "Fehlerwert" SG_ 961 APS_LED_Status 3;
BA_ "GenSigActiveRepetitions" SG_ 961 APS_Taster 5;
BA_ "GenSigSendType" SG_ 961 APS_Taster 4;
BA_ "GenSigStartValue" SG_ 961 APS_Taster 2;
BA_ "GenSigSwitchedByIgnition" SG_ 961 APS_Taster 0;
BA_ "Fehlerwert" SG_ 961 APS_Taster 3;
BA_ "GenSigActiveRepetitions" SG_ 961 AVH_LED_Status 5;
BA_ "GenSigSendType" SG_ 961 AVH_LED_Status 4;
BA_ "GenSigSwitchedByIgnition" SG_ 961 AVH_LED_Status 0;
BA_ "Fehlerwert" SG_ 961 AVH_LED_Status 3;
BA_ "GenSigActiveRepetitions" SG_ 961 AVH_Taster 5;
BA_ "GenSigSendType" SG_ 961 AVH_Taster 4;
BA_ "GenSigStartValue" SG_ 961 AVH_Taster 2;
BA_ "GenSigSwitchedByIgnition" SG_ 961 AVH_Taster 0;
BA_ "Fehlerwert" SG_ 961 AVH_Taster 3;
BA_ "GenSigActiveRepetitions" SG_ 961 Display_Taster 5;
BA_ "GenSigSendType" SG_ 961 Display_Taster 4;
BA_ "GenSigStartValue" SG_ 961 Display_Taster 2;
BA_ "GenSigSwitchedByIgnition" SG_ 961 Display_Taster 0;
BA_ "Fehlerwert" SG_ 961 Display_Taster 3;
BA_ "GenSigActiveRepetitions" SG_ 961 Drivesel_1_Taster 5;
BA_ "GenSigSendType" SG_ 961 Drivesel_1_Taster 4;
BA_ "GenSigStartValue" SG_ 961 Drivesel_1_Taster 2;
BA_ "GenSigSwitchedByIgnition" SG_ 961 Drivesel_1_Taster 0;
BA_ "Fehlerwert" SG_ 961 Drivesel_1_Taster 3;
BA_ "GenSigActiveRepetitions" SG_ 961 Drivesel_2_Taster 5;
BA_ "GenSigSendType" SG_ 961 Drivesel_2_Taster 4;
BA_ "GenSigStartValue" SG_ 961 Drivesel_2_Taster 2;
BA_ "GenSigSwitchedByIgnition" SG_ 961 Drivesel_2_Taster 0;
BA_ "Fehlerwert" SG_ 961 Drivesel_2_Taster 3;
BA_ "GenSigActiveRepetitions" SG_ 961 eCall_Taste 5;
BA_ "GenSigSendType" SG_ 961 eCall_Taste 4;
BA_ "GenSigSwitchedByIgnition" SG_ 961 eCall_Taste 0;
BA_ "Fehlerwert" SG_ 961 eCall_Taste 3;
BA_ "GenSigActiveRepetitions" SG_ 961 ESP_Off_Taster 5;
BA_ "GenSigSendType" SG_ 961 ESP_Off_Taster 4;
BA_ "GenSigStartValue" SG_ 961 ESP_Off_Taster 2;
BA_ "GenSigSwitchedByIgnition" SG_ 961 ESP_Off_Taster 0;
BA_ "Fehlerwert" SG_ 961 ESP_Off_Taster 3;
BA_ "GenSigActiveRepetitions" SG_ 961 HDC_LED_Status 5;
BA_ "GenSigSendType" SG_ 961 HDC_LED_Status 4;
BA_ "GenSigSwitchedByIgnition" SG_ 961 HDC_LED_Status 0;
BA_ "Fehlerwert" SG_ 961 HDC_LED_Status 3;
BA_ "GenSigActiveRepetitions" SG_ 961 HDC_Taster 5;
BA_ "GenSigSendType" SG_ 961 HDC_Taster 4;
BA_ "GenSigStartValue" SG_ 961 HDC_Taster 2;
BA_ "GenSigSwitchedByIgnition" SG_ 961 HDC_Taster 0;
BA_ "Fehlerwert" SG_ 961 HDC_Taster 3;
BA_ "GenSigActiveRepetitions" SG_ 961 Heckrollo_2_Taster 5;
BA_ "GenSigSendType" SG_ 961 Heckrollo_2_Taster 4;
BA_ "GenSigStartValue" SG_ 961 Heckrollo_2_Taster 2;
BA_ "GenSigSwitchedByIgnition" SG_ 961 Heckrollo_2_Taster 0;
BA_ "Fehlerwert" SG_ 961 Heckrollo_2_Taster 3;
BA_ "GenSigActiveRepetitions" SG_ 961 Heckrollo_Taster 5;
BA_ "GenSigSendType" SG_ 961 Heckrollo_Taster 4;
BA_ "GenSigStartValue" SG_ 961 Heckrollo_Taster 2;
BA_ "GenSigSwitchedByIgnition" SG_ 961 Heckrollo_Taster 0;
BA_ "Fehlerwert" SG_ 961 Heckrollo_Taster 3;
BA_ "GenSigActiveRepetitions" SG_ 961 LIM_bCall_Taster 5;
BA_ "GenSigSendType" SG_ 961 LIM_bCall_Taster 4;
BA_ "GenSigSwitchedByIgnition" SG_ 961 LIM_bCall_Taster 0;
BA_ "GenSigSendType" SG_ 961 LIM_PAO_Alivesignal 3;
BA_ "GenSigSwitchedByIgnition" SG_ 961 LIM_PAO_Alivesignal 0;
BA_ "GenSigSendType" SG_ 961 LIM_PAO_OFF_Status 3;
BA_ "GenSigSwitchedByIgnition" SG_ 961 LIM_PAO_OFF_Status 0;
BA_ "GenSigSendType" SG_ 961 LIM_PAO_ON_Status 3;
BA_ "GenSigSwitchedByIgnition" SG_ 961 LIM_PAO_ON_Status 0;
BA_ "GenSigSendType" SG_ 961 LIM_PAO_Schriftzug_Status 3;
BA_ "GenSigSwitchedByIgnition" SG_ 961 LIM_PAO_Schriftzug_Status 0;
BA_ "GenSigActiveRepetitions" SG_ 961 LKS_Taster 5;
BA_ "GenSigSendType" SG_ 961 LKS_Taster 4;
BA_ "GenSigStartValue" SG_ 961 LKS_Taster 2;
BA_ "GenSigSwitchedByIgnition" SG_ 961 LKS_Taster 0;
BA_ "Fehlerwert" SG_ 961 LKS_Taster 3;
BA_ "GenSigActiveRepetitions" SG_ 961 PLA_LED_Status 5;
BA_ "GenSigSendType" SG_ 961 PLA_LED_Status 4;
BA_ "GenSigSwitchedByIgnition" SG_ 961 PLA_LED_Status 0;
BA_ "Fehlerwert" SG_ 961 PLA_LED_Status 3;
BA_ "GenSigActiveRepetitions" SG_ 961 PLA_Taster 5;
BA_ "GenSigSendType" SG_ 961 PLA_Taster 4;
BA_ "GenSigStartValue" SG_ 961 PLA_Taster 2;
BA_ "GenSigSwitchedByIgnition" SG_ 961 PLA_Taster 0;
BA_ "Fehlerwert" SG_ 961 PLA_Taster 3;
BA_ "GenSigSendType" SG_ 961 PLA_Taster_Fehler_Roh 3;
BA_ "GenSigSwitchedByIgnition" SG_ 961 PLA_Taster_Fehler_Roh 0;
BA_ "GenSigActiveRepetitions" SG_ 961 Sideview_Taster 5;
BA_ "GenSigSendType" SG_ 961 Sideview_Taster 4;
BA_ "GenSigStartValue" SG_ 961 Sideview_Taster 2;
BA_ "GenSigSwitchedByIgnition" SG_ 961 Sideview_Taster 0;
BA_ "Fehlerwert" SG_ 961 Sideview_Taster 3;
BA_ "GenSigActiveRepetitions" SG_ 961 Spoiler_LED_Status 5;
BA_ "GenSigSendType" SG_ 961 Spoiler_LED_Status 4;
BA_ "GenSigSwitchedByIgnition" SG_ 961 Spoiler_LED_Status 0;
BA_ "Fehlerwert" SG_ 961 Spoiler_LED_Status 3;
BA_ "GenSigActiveRepetitions" SG_ 961 Spoiler_Taster 5;
BA_ "GenSigSendType" SG_ 961 Spoiler_Taster 4;
BA_ "GenSigStartValue" SG_ 961 Spoiler_Taster 2;
BA_ "GenSigSwitchedByIgnition" SG_ 961 Spoiler_Taster 0;
BA_ "Fehlerwert" SG_ 961 Spoiler_Taster 3;
BA_ "GenSigActiveRepetitions" SG_ 961 SWA_Taster 5;
BA_ "GenSigSendType" SG_ 961 SWA_Taster 4;
BA_ "GenSigSwitchedByIgnition" SG_ 961 SWA_Taster 0;
BA_ "Fehlerwert" SG_ 961 SWA_Taster 3;
BA_ "GenSigActiveRepetitions" SG_ 870 Blinken_li_Fzg_Takt 5;
BA_ "GenSigSendType" SG_ 870 Blinken_li_Fzg_Takt 4;
BA_ "GenSigSwitchedByIgnition" SG_ 870 Blinken_li_Fzg_Takt 0;
BA_ "GenSigActiveRepetitions" SG_ 870 Blinken_li_Kombi_Takt 5;
BA_ "GenSigSendType" SG_ 870 Blinken_li_Kombi_Takt 4;
BA_ "GenSigSwitchedByIgnition" SG_ 870 Blinken_li_Kombi_Takt 0;
BA_ "GenSigActiveRepetitions" SG_ 870 Blinken_re_Fzg_Takt 5;
BA_ "GenSigSendType" SG_ 870 Blinken_re_Fzg_Takt 4;
BA_ "GenSigSwitchedByIgnition" SG_ 870 Blinken_re_Fzg_Takt 0;
BA_ "GenSigActiveRepetitions" SG_ 870 Blinken_re_Kombi_Takt 5;
BA_ "GenSigSendType" SG_ 870 Blinken_re_Kombi_Takt 4;
BA_ "GenSigSwitchedByIgnition" SG_ 870 Blinken_re_Kombi_Takt 0;
BA_ "GenSigActiveRepetitions" SG_ 870 BM_Autobahn 5;
BA_ "GenSigSendType" SG_ 870 BM_Autobahn 4;
BA_ "GenSigSwitchedByIgnition" SG_ 870 BM_Autobahn 0;
BA_ "GenSigActiveRepetitions" SG_ 870 BM_Crash 5;
BA_ "GenSigSendType" SG_ 870 BM_Crash 4;
BA_ "GenSigSwitchedByIgnition" SG_ 870 BM_Crash 0;
BA_ "GenSigActiveRepetitions" SG_ 870 BM_DWA_Alarm 5;
BA_ "GenSigSendType" SG_ 870 BM_DWA_Alarm 4;
BA_ "GenSigSwitchedByIgnition" SG_ 870 BM_DWA_Alarm 0;
BA_ "GenSigActiveRepetitions" SG_ 870 BM_DWA_ein 5;
BA_ "GenSigSendType" SG_ 870 BM_DWA_ein 4;
BA_ "GenSigSwitchedByIgnition" SG_ 870 BM_DWA_ein 0;
BA_ "GenSigActiveRepetitions" SG_ 870 BM_GDO 5;
BA_ "GenSigSendType" SG_ 870 BM_GDO 4;
BA_ "GenSigSwitchedByIgnition" SG_ 870 BM_GDO 0;
BA_ "GenSigActiveRepetitions" SG_ 870 BM_HD_Oeffnung_angelernt 5;
BA_ "GenSigSendType" SG_ 870 BM_HD_Oeffnung_angelernt 4;
BA_ "GenSigSwitchedByIgnition" SG_ 870 BM_HD_Oeffnung_angelernt 0;
BA_ "GenSigActiveRepetitions" SG_ 870 BM_links 5;
BA_ "GenSigSendType" SG_ 870 BM_links 4;
BA_ "GenSigSwitchedByIgnition" SG_ 870 BM_links 0;
BA_ "GenSigActiveRepetitions" SG_ 870 BM_NBA_n_codiert_n_aktiv 5;
BA_ "GenSigSendType" SG_ 870 BM_NBA_n_codiert_n_aktiv 4;
BA_ "GenSigStartValue" SG_ 870 BM_NBA_n_codiert_n_aktiv 1;
BA_ "GenSigSwitchedByIgnition" SG_ 870 BM_NBA_n_codiert_n_aktiv 0;
BA_ "GenSigActiveRepetitions" SG_ 870 BM_NBA_Status 5;
BA_ "GenSigSendType" SG_ 870 BM_NBA_Status 4;
BA_ "GenSigSwitchedByIgnition" SG_ 870 BM_NBA_Status 0;
BA_ "GenSigActiveRepetitions" SG_ 870 BM_Not_Bremsung 5;
BA_ "GenSigSendType" SG_ 870 BM_Not_Bremsung 4;
BA_ "GenSigSwitchedByIgnition" SG_ 870 BM_Not_Bremsung 0;
BA_ "GenSigActiveRepetitions" SG_ 870 BM_Panik 5;
BA_ "GenSigSendType" SG_ 870 BM_Panik 4;
BA_ "GenSigSwitchedByIgnition" SG_ 870 BM_Panik 0;
BA_ "GenSigActiveRepetitions" SG_ 870 BM_PiloPa 5;
BA_ "GenSigSendType" SG_ 870 BM_PiloPa 4;
BA_ "GenSigSwitchedByIgnition" SG_ 870 BM_PiloPa 0;
BA_ "GenSigActiveRepetitions" SG_ 870 BM_Recas 5;
BA_ "GenSigSendType" SG_ 870 BM_Recas 4;
BA_ "GenSigSwitchedByIgnition" SG_ 870 BM_Recas 0;
BA_ "GenSigActiveRepetitions" SG_ 870 BM_rechts 5;
BA_ "GenSigSendType" SG_ 870 BM_rechts 4;
BA_ "GenSigSwitchedByIgnition" SG_ 870 BM_rechts 0;
BA_ "GenSigActiveRepetitions" SG_ 870 BM_Rollenmodus_Blinken 5;
BA_ "GenSigSendType" SG_ 870 BM_Rollenmodus_Blinken 4;
BA_ "GenSigSwitchedByIgnition" SG_ 870 BM_Rollenmodus_Blinken 0;
BA_ "GenSigActiveRepetitions" SG_ 870 BM_Taxi_Notalarm 5;
BA_ "GenSigSendType" SG_ 870 BM_Taxi_Notalarm 4;
BA_ "GenSigSwitchedByIgnition" SG_ 870 BM_Taxi_Notalarm 0;
BA_ "GenSigActiveRepetitions" SG_ 870 BM_Telematik 5;
BA_ "GenSigSendType" SG_ 870 BM_Telematik 4;
BA_ "GenSigSwitchedByIgnition" SG_ 870 BM_Telematik 0;
BA_ "GenSigActiveRepetitions" SG_ 870 BM_Telematik_Abbruchgrund 5;
BA_ "GenSigSendType" SG_ 870 BM_Telematik_Abbruchgrund 4;
BA_ "GenSigSwitchedByIgnition" SG_ 870 BM_Telematik_Abbruchgrund 0;
BA_ "GenSigActiveRepetitions" SG_ 870 BM_Warnblinken 5;
BA_ "GenSigSendType" SG_ 870 BM_Warnblinken 4;
BA_ "GenSigSwitchedByIgnition" SG_ 870 BM_Warnblinken 0;
BA_ "GenSigActiveRepetitions" SG_ 870 BM_WBT_Beleuchtung 5;
BA_ "GenSigSendType" SG_ 870 BM_WBT_Beleuchtung 4;
BA_ "GenSigSwitchedByIgnition" SG_ 870 BM_WBT_Beleuchtung 0;
BA_ "GenSigActiveRepetitions" SG_ 870 BM_Wischblinken 5;
BA_ "GenSigSendType" SG_ 870 BM_Wischblinken 4;
BA_ "GenSigSwitchedByIgnition" SG_ 870 BM_Wischblinken 0;
BA_ "GenSigActiveRepetitions" SG_ 870 BM_ZV_auf 5;
BA_ "GenSigSendType" SG_ 870 BM_ZV_auf 4;
BA_ "GenSigSwitchedByIgnition" SG_ 870 BM_ZV_auf 0;
BA_ "GenSigActiveRepetitions" SG_ 870 BM_ZV_zu 5;
BA_ "GenSigSendType" SG_ 870 BM_ZV_zu 4;
BA_ "GenSigSwitchedByIgnition" SG_ 870 BM_ZV_zu 0;
BA_ "GenSigSendType" SG_ 870 DWA_Alarmquelle 3;
BA_ "GenSigStartValue" SG_ 870 DWA_Alarmquelle 30;
BA_ "GenSigSwitchedByIgnition" SG_ 870 DWA_Alarmquelle 0;
BA_ "Fehlerwert" SG_ 870 DWA_Alarmquelle 31;
BA_ "GenSigSwitchedByIgnition" SG_ 2617195008 DEV_eCall_Resp_00_Data 0;
BA_ "GenSigSwitchedByIgnition" SG_ 2617195263 DEV_eCall_Resp_FF_Data 0;
BA_ "GenSigSwitchedByIgnition" SG_ 2616996608 DEV_OTA_FC_Resp_00_Data 0;
BA_ "GenSigSwitchedByIgnition" SG_ 2616996863 DEV_OTA_FC_Resp_FF_Data 0;
BA_ "GenSigSendType" SG_ 1714 DGN_Verlernzaehler 0;
BA_ "GenSigSwitchedByIgnition" SG_ 1714 DGN_Verlernzaehler 0;
BA_ "GenSigSendType" SG_ 1714 KBI_Kilometerstand 0;
BA_ "GenSigStartValue" SG_ 1714 KBI_Kilometerstand 1048574;
BA_ "GenSigSwitchedByIgnition" SG_ 1714 KBI_Kilometerstand 0;
BA_ "Fehlerwert" SG_ 1714 KBI_Kilometerstand 1048575;
BA_ "GenSigSendType" SG_ 1714 Kombi_02_alt 0;
BA_ "GenSigStartValue" SG_ 1714 Kombi_02_alt 1;
BA_ "GenSigFuncType" SG_ 1714 Kombi_02_alt 5;
BA_ "GenSigSwitchedByIgnition" SG_ 1714 Kombi_02_alt 0;
BA_ "GenSigSendType" SG_ 1714 UH_Jahr 0;
BA_ "GenSigSwitchedByIgnition" SG_ 1714 UH_Jahr 0;
BA_ "GenSigSendType" SG_ 1714 UH_Minute 0;
BA_ "GenSigSwitchedByIgnition" SG_ 1714 UH_Minute 0;
BA_ "GenSigSendType" SG_ 1714 UH_Monat 0;
BA_ "GenSigSwitchedByIgnition" SG_ 1714 UH_Monat 0;
BA_ "Fehlerwert" SG_ 1714 UH_Monat 15;
BA_ "GenSigSendType" SG_ 1714 UH_Sekunde 0;
BA_ "GenSigSwitchedByIgnition" SG_ 1714 UH_Sekunde 0;
BA_ "GenSigSendType" SG_ 1714 UH_Stunde 0;
BA_ "GenSigSwitchedByIgnition" SG_ 1714 UH_Stunde 0;
BA_ "GenSigSendType" SG_ 1714 UH_Tag 0;
BA_ "GenSigSwitchedByIgnition" SG_ 1714 UH_Tag 0;
BA_ "GenSigSendType" SG_ 1714 Uhrzeit_01_alt 0;
BA_ "GenSigStartValue" SG_ 1714 Uhrzeit_01_alt 1;
BA_ "GenSigFuncType" SG_ 1714 Uhrzeit_01_alt 5;
BA_ "GenSigSwitchedByIgnition" SG_ 1714 Uhrzeit_01_alt 0;
BA_ "GenSigSendType" SG_ 1520 BCM1_Stellgroesse_Kl_58s 3;
BA_ "GenSigStartValue" SG_ 1520 BCM1_Stellgroesse_Kl_58s 126;
BA_ "GenSigSwitchedByIgnition" SG_ 1520 BCM1_Stellgroesse_Kl_58s 0;
BA_ "Fehlerwert" SG_ 1520 BCM1_Stellgroesse_Kl_58s 127;
BA_ "GenSigSendType" SG_ 1520 DI_Display_Nachtdesign 3;
BA_ "GenSigSwitchedByIgnition" SG_ 1520 DI_Display_Nachtdesign 0;
BA_ "GenSigSendType" SG_ 1520 DI_Fotosensor 3;
BA_ "GenSigSwitchedByIgnition" SG_ 1520 DI_Fotosensor 0;
BA_ "GenSigSendType" SG_ 1520 DI_KL_58xd 3;
BA_ "GenSigStartValue" SG_ 1520 DI_KL_58xd 254;
BA_ "GenSigSwitchedByIgnition" SG_ 1520 DI_KL_58xd 0;
BA_ "Fehlerwert" SG_ 1520 DI_KL_58xd 255;
BA_ "GenSigSendType" SG_ 1520 DI_KL_58xs 3;
BA_ "GenSigStartValue" SG_ 1520 DI_KL_58xs 126;
BA_ "GenSigSwitchedByIgnition" SG_ 1520 DI_KL_58xs 0;
BA_ "Fehlerwert" SG_ 1520 DI_KL_58xs 127;
BA_ "GenSigSendType" SG_ 1520 DI_KL_58xt 3;
BA_ "GenSigStartValue" SG_ 1520 DI_KL_58xt 126;
BA_ "GenSigSwitchedByIgnition" SG_ 1520 DI_KL_58xt 0;
BA_ "Fehlerwert" SG_ 1520 DI_KL_58xt 127;
BA_ "GenSigSendType" SG_ 2589283628 VTS_Anf_DC_Suche 3;
BA_ "GenSigSwitchedByIgnition" SG_ 2589283628 VTS_Anf_DC_Suche 0;
BA_ "GenSigSendType" SG_ 2589283628 VTS_Anf_DC_Suche_ID 3;
BA_ "GenSigSwitchedByIgnition" SG_ 2589283628 VTS_Anf_DC_Suche_ID 0;
BA_ "GenSigSendType" SG_ 2589283628 VTS_DC_ID 3;
BA_ "GenSigSwitchedByIgnition" SG_ 2589283628 VTS_DC_ID 0;
BA_ "GenSigSendType" SG_ 420 EA_01_BZ 0;
BA_ "GenSigFuncType" SG_ 420 EA_01_BZ 1;
BA_ "GenSigSendType" SG_ 420 EA_01_CRC 0;
BA_ "GenSigFuncType" SG_ 420 EA_01_CRC 2;
BA_ "GenSigSendType" SG_ 420 EA_Anforderung_HMS 0;
BA_ "GenSigSendType" SG_ 420 EA_eCall_Anf 0;
BA_ "GenSigSwitchedByIgnition" SG_ 420 EA_eCall_Anf 0;
BA_ "GenSigSendType" SG_ 420 EA_Funktionsstatus 0;
BA_ "GenSigSendType" SG_ 420 EA_Gurtstraffer_Anf 0;
BA_ "GenSigSendType" SG_ 420 EA_Parken_beibehalten_HMS 0;
BA_ "GenSigStartValue" SG_ 420 EA_Parken_beibehalten_HMS 2;
BA_ "Fehlerwert" SG_ 420 EA_Parken_beibehalten_HMS 3;
BA_ "GenSigSendType" SG_ 420 EA_Sollbeschleunigung 0;
BA_ "GenSigStartValue" SG_ 420 EA_Sollbeschleunigung 2046;
BA_ "Fehlerwert" SG_ 420 EA_Sollbeschleunigung 2047;
BA_ "GenSigSendType" SG_ 420 EA_Warnruckprofil 0;
BA_ "GenSigSendType" SG_ 2589283655 ConBox_T3_Status 3;
BA_ "GenSigSwitchedByIgnition" SG_ 2589283655 ConBox_T3_Status 0;
BA_ "GenSigSendType" SG_ 2589283655 ConBox_T6_Status 3;
BA_ "GenSigSwitchedByIgnition" SG_ 2589283655 ConBox_T6_Status 0;
BA_ "GenSigSendType" SG_ 2589283655 eCall2_Funktionsstatus 3;
BA_ "GenSigSwitchedByIgnition" SG_ 2589283655 eCall2_Funktionsstatus 0;
BA_ "GenSigSendType" SG_ 2589283655 eCall2_Funktionsstatus_02 3;
BA_ "GenSigStartValue" SG_ 2589283655 eCall2_Funktionsstatus_02 7;
BA_ "GenSigSwitchedByIgnition" SG_ 2589283655 eCall2_Funktionsstatus_02 0;
BA_ "GenSigSendType" SG_ 2589283655 eCall2_Mute_Anf 3;
BA_ "GenSigSwitchedByIgnition" SG_ 2589283655 eCall2_Mute_Anf 0;
BA_ "GenSigSendType" SG_ 2589283655 eCall2_Statuslicht_Farbe1 3;
BA_ "GenSigSwitchedByIgnition" SG_ 2589283655 eCall2_Statuslicht_Farbe1 0;
BA_ "GenSigSendType" SG_ 2589283655 eCall2_Statuslicht_Farbe2 3;
BA_ "GenSigSwitchedByIgnition" SG_ 2589283655 eCall2_Statuslicht_Farbe2 0;
BA_ "GenSigSendType" SG_ 2589283655 eCall2_Subscription 3;
BA_ "GenSigSwitchedByIgnition" SG_ 2589283655 eCall2_Subscription 0;
BA_ "GenSigSendType" SG_ 1603 KBI_Einheit_Datum 3;
BA_ "GenSigSwitchedByIgnition" SG_ 1603 KBI_Einheit_Datum 0;
BA_ "GenSigSendType" SG_ 1603 KBI_Einheit_Druck 3;
BA_ "GenSigSwitchedByIgnition" SG_ 1603 KBI_Einheit_Druck 0;
BA_ "GenSigSendType" SG_ 1603 KBI_Einheit_Masse 3;
BA_ "GenSigSwitchedByIgnition" SG_ 1603 KBI_Einheit_Masse 0;
BA_ "GenSigSendType" SG_ 1603 KBI_Einheit_Sprache 3;
BA_ "GenSigSwitchedByIgnition" SG_ 1603 KBI_Einheit_Sprache 0;
BA_ "GenSigSendType" SG_ 1603 KBI_Einheit_Streckenanz 3;
BA_ "GenSigSwitchedByIgnition" SG_ 1603 KBI_Einheit_Streckenanz 0;
BA_ "GenSigSendType" SG_ 1603 KBI_Einheit_Temp 3;
BA_ "GenSigSwitchedByIgnition" SG_ 1603 KBI_Einheit_Temp 0;
BA_ "GenSigSendType" SG_ 1603 KBI_Einheit_Uhrzeit 3;
BA_ "GenSigSwitchedByIgnition" SG_ 1603 KBI_Einheit_Uhrzeit 0;
BA_ "GenSigSendType" SG_ 1603 KBI_Einheit_Verbrauch 3;
BA_ "GenSigSwitchedByIgnition" SG_ 1603 KBI_Einheit_Verbrauch 0;
BA_ "GenSigSendType" SG_ 1603 KBI_Einheit_Verbrauch_elektr 3;
BA_ "GenSigSwitchedByIgnition" SG_ 1603 KBI_Einheit_Verbrauch_elektr 0;
BA_ "GenSigSendType" SG_ 1603 KBI_Einheit_Verbrauch_Gas 3;
BA_ "GenSigSwitchedByIgnition" SG_ 1603 KBI_Einheit_Verbrauch_Gas 0;
BA_ "GenSigSendType" SG_ 1603 KBI_Einheit_Volumen 3;
BA_ "GenSigSwitchedByIgnition" SG_ 1603 KBI_Einheit_Volumen 0;
BA_ "GenSigSendType" SG_ 1603 KBI_MFA_v_Einheit_02 3;
BA_ "GenSigSwitchedByIgnition" SG_ 1603 KBI_MFA_v_Einheit_02 0;
BA_ "GenSigSendType" SG_ 259 ESP_03_BZ 0;
BA_ "GenSigFuncType" SG_ 259 ESP_03_BZ 1;
BA_ "GenSigSwitchedByIgnition" SG_ 259 ESP_03_BZ 0;
BA_ "GenSigSendType" SG_ 259 ESP_03_CRC 0;
BA_ "GenSigFuncType" SG_ 259 ESP_03_CRC 2;
BA_ "GenSigSwitchedByIgnition" SG_ 259 ESP_03_CRC 0;
BA_ "GenSigSendType" SG_ 259 ESP_HL_FR 0;
BA_ "GenSigSwitchedByIgnition" SG_ 259 ESP_HL_FR 0;
BA_ "GenSigSendType" SG_ 259 ESP_HL_Radgeschw 0;
BA_ "GenSigStartValue" SG_ 259 ESP_HL_Radgeschw 4094;
BA_ "GenSigSwitchedByIgnition" SG_ 259 ESP_HL_Radgeschw 0;
BA_ "Fehlerwert" SG_ 259 ESP_HL_Radgeschw 4095;
BA_ "GenSigSendType" SG_ 259 ESP_HR_FR 0;
BA_ "GenSigSwitchedByIgnition" SG_ 259 ESP_HR_FR 0;
BA_ "GenSigSendType" SG_ 259 ESP_HR_Radgeschw 0;
BA_ "GenSigStartValue" SG_ 259 ESP_HR_Radgeschw 4094;
BA_ "GenSigSwitchedByIgnition" SG_ 259 ESP_HR_Radgeschw 0;
BA_ "Fehlerwert" SG_ 259 ESP_HR_Radgeschw 4095;
BA_ "GenSigSendType" SG_ 259 ESP_VL_FR 0;
BA_ "GenSigSwitchedByIgnition" SG_ 259 ESP_VL_FR 0;
BA_ "GenSigSendType" SG_ 259 ESP_VL_Radgeschw 0;
BA_ "GenSigStartValue" SG_ 259 ESP_VL_Radgeschw 4094;
BA_ "GenSigSwitchedByIgnition" SG_ 259 ESP_VL_Radgeschw 0;
BA_ "Fehlerwert" SG_ 259 ESP_VL_Radgeschw 4095;
BA_ "GenSigSendType" SG_ 259 ESP_VR_FR 0;
BA_ "GenSigSwitchedByIgnition" SG_ 259 ESP_VR_FR 0;
BA_ "GenSigSendType" SG_ 259 ESP_VR_Radgeschw 0;
BA_ "GenSigStartValue" SG_ 259 ESP_VR_Radgeschw 4094;
BA_ "GenSigSwitchedByIgnition" SG_ 259 ESP_VR_Radgeschw 0;
BA_ "Fehlerwert" SG_ 259 ESP_VR_Radgeschw 4095;
BA_ "GenSigSendType" SG_ 278 ESP_10_BZ 0;
BA_ "GenSigFuncType" SG_ 278 ESP_10_BZ 1;
BA_ "GenSigSwitchedByIgnition" SG_ 278 ESP_10_BZ 0;
BA_ "GenSigSendType" SG_ 278 ESP_10_CRC 0;
BA_ "GenSigFuncType" SG_ 278 ESP_10_CRC 2;
BA_ "GenSigSwitchedByIgnition" SG_ 278 ESP_10_CRC 0;
BA_ "GenSigSendType" SG_ 278 ESP_HL_Fahrtrichtung 0;
BA_ "GenSigStartValue" SG_ 278 ESP_HL_Fahrtrichtung 2;
BA_ "GenSigSwitchedByIgnition" SG_ 278 ESP_HL_Fahrtrichtung 0;
BA_ "GenSigSendType" SG_ 278 ESP_HR_Fahrtrichtung 0;
BA_ "GenSigStartValue" SG_ 278 ESP_HR_Fahrtrichtung 2;
BA_ "GenSigSwitchedByIgnition" SG_ 278 ESP_HR_Fahrtrichtung 0;
BA_ "GenSigSendType" SG_ 278 ESP_QBit_Wegimpuls_HL 0;
BA_ "GenSigStartValue" SG_ 278 ESP_QBit_Wegimpuls_HL 1;
BA_ "GenSigSwitchedByIgnition" SG_ 278 ESP_QBit_Wegimpuls_HL 0;
BA_ "GenSigSendType" SG_ 278 ESP_QBit_Wegimpuls_HR 0;
BA_ "GenSigStartValue" SG_ 278 ESP_QBit_Wegimpuls_HR 1;
BA_ "GenSigSwitchedByIgnition" SG_ 278 ESP_QBit_Wegimpuls_HR 0;
BA_ "GenSigSendType" SG_ 278 ESP_QBit_Wegimpuls_VL 0;
BA_ "GenSigStartValue" SG_ 278 ESP_QBit_Wegimpuls_VL 1;
BA_ "GenSigSwitchedByIgnition" SG_ 278 ESP_QBit_Wegimpuls_VL 0;
BA_ "GenSigSendType" SG_ 278 ESP_QBit_Wegimpuls_VR 0;
BA_ "GenSigStartValue" SG_ 278 ESP_QBit_Wegimpuls_VR 1;
BA_ "GenSigSwitchedByIgnition" SG_ 278 ESP_QBit_Wegimpuls_VR 0;
BA_ "GenSigSendType" SG_ 278 ESP_VL_Fahrtrichtung 0;
BA_ "GenSigStartValue" SG_ 278 ESP_VL_Fahrtrichtung 2;
BA_ "GenSigSwitchedByIgnition" SG_ 278 ESP_VL_Fahrtrichtung 0;
BA_ "GenSigSendType" SG_ 278 ESP_VR_Fahrtrichtung 0;
BA_ "GenSigStartValue" SG_ 278 ESP_VR_Fahrtrichtung 2;
BA_ "GenSigSwitchedByIgnition" SG_ 278 ESP_VR_Fahrtrichtung 0;
BA_ "GenSigSendType" SG_ 278 ESP_Wegimpuls_HL 0;
BA_ "GenSigStartValue" SG_ 278 ESP_Wegimpuls_HL 1021;
BA_ "GenSigSwitchedByIgnition" SG_ 278 ESP_Wegimpuls_HL 0;
BA_ "Fehlerwert" SG_ 278 ESP_Wegimpuls_HL 1023;
BA_ "GenSigSendType" SG_ 278 ESP_Wegimpuls_HR 0;
BA_ "GenSigStartValue" SG_ 278 ESP_Wegimpuls_HR 1021;
BA_ "GenSigSwitchedByIgnition" SG_ 278 ESP_Wegimpuls_HR 0;
BA_ "Fehlerwert" SG_ 278 ESP_Wegimpuls_HR 1023;
BA_ "GenSigSendType" SG_ 278 ESP_Wegimpuls_VL 0;
BA_ "GenSigStartValue" SG_ 278 ESP_Wegimpuls_VL 1021;
BA_ "GenSigSwitchedByIgnition" SG_ 278 ESP_Wegimpuls_VL 0;
BA_ "Fehlerwert" SG_ 278 ESP_Wegimpuls_VL 1023;
BA_ "GenSigSendType" SG_ 278 ESP_Wegimpuls_VR 0;
BA_ "GenSigStartValue" SG_ 278 ESP_Wegimpuls_VR 1021;
BA_ "GenSigSwitchedByIgnition" SG_ 278 ESP_Wegimpuls_VR 0;
BA_ "Fehlerwert" SG_ 278 ESP_Wegimpuls_VR 1023;
BA_ "GenSigSendType" SG_ 1629 BR_QBit_Reifenumfang 0;
BA_ "GenSigStartValue" SG_ 1629 BR_QBit_Reifenumfang 1;
BA_ "GenSigSwitchedByIgnition" SG_ 1629 BR_QBit_Reifenumfang 0;
BA_ "GenSigSendType" SG_ 1629 BR_Reifenumfang 0;
BA_ "GenSigSwitchedByIgnition" SG_ 1629 BR_Reifenumfang 0;
BA_ "GenSigSendType" SG_ 1629 BR_Systemart 0;
BA_ "GenSigFuncType" SG_ 1629 BR_Systemart 8;
BA_ "GenSigSwitchedByIgnition" SG_ 1629 BR_Systemart 0;
BA_ "GenSigSendType" SG_ 1629 ESP_20_BZ 0;
BA_ "GenSigFuncType" SG_ 1629 ESP_20_BZ 1;
BA_ "GenSigSwitchedByIgnition" SG_ 1629 ESP_20_BZ 0;
BA_ "GenSigSendType" SG_ 1629 ESP_20_CRC 0;
BA_ "GenSigFuncType" SG_ 1629 ESP_20_CRC 2;
BA_ "GenSigSwitchedByIgnition" SG_ 1629 ESP_20_CRC 0;
BA_ "GenSigSendType" SG_ 1629 ESP_Charisma_FahrPr 0;
BA_ "GenSigSwitchedByIgnition" SG_ 1629 ESP_Charisma_FahrPr 0;
BA_ "GenSigSendType" SG_ 1629 ESP_Charisma_Status 0;
BA_ "GenSigSwitchedByIgnition" SG_ 1629 ESP_Charisma_Status 0;
BA_ "GenSigSendType" SG_ 1629 ESP_Dachrelingsensor 0;
BA_ "GenSigSwitchedByIgnition" SG_ 1629 ESP_Dachrelingsensor 0;
BA_ "Fehlerwert" SG_ 1629 ESP_Dachrelingsensor 3;
BA_ "GenSigSendType" SG_ 1629 ESP_SpannungsAnf_02 0;
BA_ "GenSigSwitchedByIgnition" SG_ 1629 ESP_SpannungsAnf_02 0;
BA_ "GenSigSendType" SG_ 1629 ESP_Stoppverbot_Anz_01 0;
BA_ "GenSigSwitchedByIgnition" SG_ 1629 ESP_Stoppverbot_Anz_01 0;
BA_ "GenSigSendType" SG_ 1629 ESP_Stoppverbot_Anz_02 0;
BA_ "GenSigSwitchedByIgnition" SG_ 1629 ESP_Stoppverbot_Anz_02 0;
BA_ "GenSigSendType" SG_ 1629 ESP_Stoppverbot_Anz_03 0;
BA_ "GenSigSwitchedByIgnition" SG_ 1629 ESP_Stoppverbot_Anz_03 0;
BA_ "GenSigSendType" SG_ 1629 ESP_Stoppverbot_Anz_04 0;
BA_ "GenSigSwitchedByIgnition" SG_ 1629 ESP_Stoppverbot_Anz_04 0;
BA_ "GenSigSendType" SG_ 1629 ESP_Stoppverbot_Anz_05 0;
BA_ "GenSigSwitchedByIgnition" SG_ 1629 ESP_Stoppverbot_Anz_05 0;
BA_ "GenSigSendType" SG_ 1629 ESP_Stoppverbot_Anz_06 0;
BA_ "GenSigSwitchedByIgnition" SG_ 1629 ESP_Stoppverbot_Anz_06 0;
BA_ "GenSigSendType" SG_ 1629 ESP_Stoppverbot_Anz_07 0;
BA_ "GenSigSwitchedByIgnition" SG_ 1629 ESP_Stoppverbot_Anz_07 0;
BA_ "GenSigSendType" SG_ 1629 ESP_Stoppverbot_Anz_08 0;
BA_ "GenSigSwitchedByIgnition" SG_ 1629 ESP_Stoppverbot_Anz_08 0;
BA_ "GenSigSendType" SG_ 1629 ESP_Stoppverbot_Anz_Std 0;
BA_ "GenSigSwitchedByIgnition" SG_ 1629 ESP_Stoppverbot_Anz_Std 0;
BA_ "GenSigSendType" SG_ 1629 ESP_Wiederstart_Anz_01 0;
BA_ "GenSigSwitchedByIgnition" SG_ 1629 ESP_Wiederstart_Anz_01 0;
BA_ "GenSigSendType" SG_ 1629 ESP_Wiederstart_Anz_02 0;
BA_ "GenSigSwitchedByIgnition" SG_ 1629 ESP_Wiederstart_Anz_02 0;
BA_ "GenSigSendType" SG_ 1629 ESP_Wiederstart_Anz_03 0;
BA_ "GenSigSwitchedByIgnition" SG_ 1629 ESP_Wiederstart_Anz_03 0;
BA_ "GenSigSendType" SG_ 1629 ESP_Wiederstart_Anz_04 0;
BA_ "GenSigSwitchedByIgnition" SG_ 1629 ESP_Wiederstart_Anz_04 0;
BA_ "GenSigSendType" SG_ 1629 ESP_Zaehnezahl 0;
BA_ "GenSigFuncType" SG_ 1629 ESP_Zaehnezahl 8;
BA_ "GenSigSwitchedByIgnition" SG_ 1629 ESP_Zaehnezahl 0;
BA_ "GenSigSendType" SG_ 1629 HDC_Charisma_FahrPr 0;
BA_ "GenSigSwitchedByIgnition" SG_ 1629 HDC_Charisma_FahrPr 0;
BA_ "GenSigSendType" SG_ 1629 HDC_Charisma_Status 0;
BA_ "GenSigSwitchedByIgnition" SG_ 1629 HDC_Charisma_Status 0;
BA_ "GenSigSendType" SG_ 253 ABS_Bremsung 0;
BA_ "GenSigSwitchedByIgnition" SG_ 253 ABS_Bremsung 0;
BA_ "GenSigSendType" SG_ 253 ASR_Anf 0;
BA_ "GenSigSwitchedByIgnition" SG_ 253 ASR_Anf 0;
BA_ "GenSigSendType" SG_ 253 ASR_Schalteingriff 0;
BA_ "GenSigSwitchedByIgnition" SG_ 253 ASR_Schalteingriff 0;
BA_ "GenSigSendType" SG_ 253 ASR_Tastung_passiv 0;
BA_ "GenSigSwitchedByIgnition" SG_ 253 ASR_Tastung_passiv 0;
BA_ "GenSigSendType" SG_ 253 BR_Eingriffsmoment 0;
BA_ "GenSigStartValue" SG_ 253 BR_Eingriffsmoment 1022;
BA_ "GenSigSwitchedByIgnition" SG_ 253 BR_Eingriffsmoment 0;
BA_ "Fehlerwert" SG_ 253 BR_Eingriffsmoment 1023;
BA_ "GenSigSendType" SG_ 253 EBV_Eingriff 0;
BA_ "GenSigSwitchedByIgnition" SG_ 253 EBV_Eingriff 0;
BA_ "GenSigSendType" SG_ 253 EDS_Eingriff 0;
BA_ "GenSigSwitchedByIgnition" SG_ 253 EDS_Eingriff 0;
BA_ "GenSigSendType" SG_ 253 ESC_Neutralschaltung 0;
BA_ "GenSigSwitchedByIgnition" SG_ 253 ESC_Neutralschaltung 0;
BA_ "GenSigSendType" SG_ 253 ESC_v_Signal_Qualifier_High_Low 0;
BA_ "GenSigStartValue" SG_ 253 ESC_v_Signal_Qualifier_High_Low 6;
BA_ "GenSigSwitchedByIgnition" SG_ 253 ESC_v_Signal_Qualifier_High_Low 0;
BA_ "Fehlerwert" SG_ 253 ESC_v_Signal_Qualifier_High_Low 7;
BA_ "GenSigSendType" SG_ 253 ESP_21_BZ 0;
BA_ "GenSigFuncType" SG_ 253 ESP_21_BZ 1;
BA_ "GenSigSwitchedByIgnition" SG_ 253 ESP_21_BZ 0;
BA_ "GenSigSendType" SG_ 253 ESP_21_CRC 0;
BA_ "GenSigFuncType" SG_ 253 ESP_21_CRC 2;
BA_ "GenSigSwitchedByIgnition" SG_ 253 ESP_21_CRC 0;
BA_ "GenSigSendType" SG_ 253 ESP_ASP 0;
BA_ "GenSigSwitchedByIgnition" SG_ 253 ESP_ASP 0;
BA_ "GenSigSendType" SG_ 253 ESP_Diagnose 0;
BA_ "GenSigSwitchedByIgnition" SG_ 253 ESP_Diagnose 0;
BA_ "GenSigSendType" SG_ 253 ESP_Eingriff 0;
BA_ "GenSigSwitchedByIgnition" SG_ 253 ESP_Eingriff 0;
BA_ "GenSigSendType" SG_ 253 ESP_QBit_v_Signal 0;
BA_ "GenSigStartValue" SG_ 253 ESP_QBit_v_Signal 1;
BA_ "GenSigSwitchedByIgnition" SG_ 253 ESP_QBit_v_Signal 0;
BA_ "GenSigSendType" SG_ 253 ESP_Systemstatus 0;
BA_ "GenSigSwitchedByIgnition" SG_ 253 ESP_Systemstatus 0;
BA_ "GenSigSendType" SG_ 253 ESP_Tastung_passiv 0;
BA_ "GenSigSwitchedByIgnition" SG_ 253 ESP_Tastung_passiv 0;
BA_ "GenSigSendType" SG_ 253 ESP_v_Signal 0;
BA_ "GenSigStartValue" SG_ 253 ESP_v_Signal 65534;
BA_ "GenSigSwitchedByIgnition" SG_ 253 ESP_v_Signal 0;
BA_ "Fehlerwert" SG_ 253 ESP_v_Signal 65535;
BA_ "GenSigMissingSourceValue" SG_ 253 ESP_v_Signal 65534;
BA_ "GenSigSendType" SG_ 253 ESP_Vorsteuerung 0;
BA_ "GenSigSwitchedByIgnition" SG_ 253 ESP_Vorsteuerung 0;
BA_ "GenSigSendType" SG_ 253 MSR_Anf 0;
BA_ "GenSigSwitchedByIgnition" SG_ 253 MSR_Anf 0;
BA_ "GenSigSendType" SG_ 253 MSR_verfuegbar 0;
BA_ "GenSigStartValue" SG_ 253 MSR_verfuegbar 1;
BA_ "GenSigSwitchedByIgnition" SG_ 253 MSR_verfuegbar 0;
BA_ "GenSigSendType" SG_ 253 OBD_QBit_Schlechtweg 0;
BA_ "GenSigStartValue" SG_ 253 OBD_QBit_Schlechtweg 1;
BA_ "GenSigSwitchedByIgnition" SG_ 253 OBD_QBit_Schlechtweg 0;
BA_ "GenSigSendType" SG_ 253 OBD_Schlechtweg 0;
BA_ "GenSigSwitchedByIgnition" SG_ 253 OBD_Schlechtweg 0;
BA_ "GenSigSendType" SG_ 508 ESC_Anforderung_Airbrake 0;
BA_ "GenSigSwitchedByIgnition" SG_ 508 ESC_Anforderung_Airbrake 0;
BA_ "GenSigSendType" SG_ 508 ESC_FBA_Meldungen 0;
BA_ "GenSigSwitchedByIgnition" SG_ 508 ESC_FBA_Meldungen 0;
BA_ "GenSigSendType" SG_ 508 ESC_MBK_Meldungen 0;
BA_ "GenSigSwitchedByIgnition" SG_ 508 ESC_MBK_Meldungen 0;
BA_ "GenSigSendType" SG_ 508 ESC_Motorstartverzoegerung 0;
BA_ "GenSigSwitchedByIgnition" SG_ 508 ESC_Motorstartverzoegerung 0;
BA_ "GenSigSendType" SG_ 508 ESP_32_BZ 0;
BA_ "GenSigFuncType" SG_ 508 ESP_32_BZ 1;
BA_ "GenSigSwitchedByIgnition" SG_ 508 ESP_32_BZ 0;
BA_ "GenSigSendType" SG_ 508 ESP_32_CRC 0;
BA_ "GenSigFuncType" SG_ 508 ESP_32_CRC 2;
BA_ "GenSigSwitchedByIgnition" SG_ 508 ESP_32_CRC 0;
BA_ "GenSigSendType" SG_ 508 ESP_Aggregataktivitaet 0;
BA_ "GenSigSwitchedByIgnition" SG_ 508 ESP_Aggregataktivitaet 0;
BA_ "GenSigSendType" SG_ 508 ESP_AVH_LED 0;
BA_ "GenSigStartValue" SG_ 508 ESP_AVH_LED 6;
BA_ "GenSigSwitchedByIgnition" SG_ 508 ESP_AVH_LED 0;
BA_ "GenSigSendType" SG_ 508 ESP_EDS_Anzeige 0;
BA_ "GenSigSwitchedByIgnition" SG_ 508 ESP_EDS_Anzeige 0;
BA_ "GenSigSendType" SG_ 508 ESP_HDC_LED 0;
BA_ "GenSigStartValue" SG_ 508 ESP_HDC_LED 6;
BA_ "GenSigSwitchedByIgnition" SG_ 508 ESP_HDC_LED 0;
BA_ "GenSigSendType" SG_ 508 ESP_HDC_Textanzeigen 0;
BA_ "GenSigSwitchedByIgnition" SG_ 508 ESP_HDC_Textanzeigen 0;
BA_ "GenSigSendType" SG_ 508 ESP_HOLD_verf 0;
BA_ "GenSigSwitchedByIgnition" SG_ 508 ESP_HOLD_verf 0;
BA_ "GenSigSendType" SG_ 508 ESP_Notbremsanzeige 3;
BA_ "GenSigSwitchedByIgnition" SG_ 508 ESP_Notbremsanzeige 0;
BA_ "GenSigSendType" SG_ 508 ESP_Off_LED 0;
BA_ "GenSigStartValue" SG_ 508 ESP_Off_LED 6;
BA_ "GenSigSwitchedByIgnition" SG_ 508 ESP_Off_LED 0;
BA_ "GenSigSendType" SG_ 508 ESP_Offroad_Lampe 0;
BA_ "GenSigSwitchedByIgnition" SG_ 508 ESP_Offroad_Lampe 0;
BA_ "GenSigSendType" SG_ 508 ESP_Rollover_Status_dyn 0;
BA_ "GenSigSwitchedByIgnition" SG_ 508 ESP_Rollover_Status_dyn 0;
BA_ "GenSigSendType" SG_ 508 ESP_Rollover_Status_stat 0;
BA_ "GenSigSwitchedByIgnition" SG_ 508 ESP_Rollover_Status_stat 0;
BA_ "GenSigSendType" SG_ 508 ESP_Status_Bremsentemp_02 0;
BA_ "GenSigSwitchedByIgnition" SG_ 508 ESP_Status_Bremsentemp_02 0;
BA_ "GenSigSendType" SG_ 508 ESP_Stillstandsflag 3;
BA_ "GenSigSwitchedByIgnition" SG_ 508 ESP_Stillstandsflag 0;
BA_ "GenSigSendType" SG_ 508 ESP_Wiederstart_Anz_Std 0;
BA_ "GenSigSwitchedByIgnition" SG_ 508 ESP_Wiederstart_Anz_Std 0;
BA_ "GenSigSendType" SG_ 508 RLE_Anzeigen 0;
BA_ "GenSigSwitchedByIgnition" SG_ 508 RLE_Anzeigen 0;
BA_ "GenSigSendType" SG_ 2549875590 FoD_OTA_FC_Req_Data 3;
BA_ "GenSigFuncType" SG_ 2549875590 FoD_OTA_FC_Req_Data 9;
BA_ "GenSigSwitchedByIgnition" SG_ 2549875590 FoD_OTA_FC_Req_Data 0;
BA_ "GenSigSendType" SG_ 2550006662 FoD_OTA_FC_Resp_Data 3;
BA_ "GenSigFuncType" SG_ 2550006662 FoD_OTA_FC_Resp_Data 9;
BA_ "GenSigSwitchedByIgnition" SG_ 2550006662 FoD_OTA_FC_Resp_Data 0;
BA_ "GenSigSendType" SG_ 879 GNSS_Breite_Ortung 0;
BA_ "GenSigStartValue" SG_ 879 GNSS_Breite_Ortung 134217726;
BA_ "GenSigSwitchedByIgnition" SG_ 879 GNSS_Breite_Ortung 0;
BA_ "Fehlerwert" SG_ 879 GNSS_Breite_Ortung 134217727;
BA_ "GenSigSendType" SG_ 879 GNSS_Fehlerzustand 0;
BA_ "GenSigSwitchedByIgnition" SG_ 879 GNSS_Fehlerzustand 0;
BA_ "GenSigSendType" SG_ 879 GNSS_Laenge_Ortung 0;
BA_ "GenSigStartValue" SG_ 879 GNSS_Laenge_Ortung 268435454;
BA_ "GenSigSwitchedByIgnition" SG_ 879 GNSS_Laenge_Ortung 0;
BA_ "Fehlerwert" SG_ 879 GNSS_Laenge_Ortung 268435455;
BA_ "GenSigSendType" SG_ 879 GNSS_Nachrichtenpaket_ID1 0;
BA_ "GenSigSwitchedByIgnition" SG_ 879 GNSS_Nachrichtenpaket_ID1 0;
BA_ "GenSigSendType" SG_ 879 GNSS_Ortung_FIX_Typ 0;
BA_ "GenSigSwitchedByIgnition" SG_ 879 GNSS_Ortung_FIX_Typ 0;
BA_ "GenSigSendType" SG_ 879 GNSS_Richtung_Breite_Ortung 0;
BA_ "GenSigStartValue" SG_ 879 GNSS_Richtung_Breite_Ortung 1;
BA_ "GenSigSwitchedByIgnition" SG_ 879 GNSS_Richtung_Breite_Ortung 0;
BA_ "GenSigSendType" SG_ 879 GNSS_Richtung_Laenge_Ortung 0;
BA_ "GenSigStartValue" SG_ 879 GNSS_Richtung_Laenge_Ortung 1;
BA_ "GenSigSwitchedByIgnition" SG_ 879 GNSS_Richtung_Laenge_Ortung 0;
BA_ "GenSigSendType" SG_ 884 GNSS_Nachrichtenpaket_ID2 0;
BA_ "GenSigSwitchedByIgnition" SG_ 884 GNSS_Nachrichtenpaket_ID2 0;
BA_ "GenSigSendType" SG_ 884 GNSS_Ortung_2D_Geschw_ue_Grund 0;
BA_ "GenSigStartValue" SG_ 884 GNSS_Ortung_2D_Geschw_ue_Grund 510;
BA_ "GenSigSwitchedByIgnition" SG_ 884 GNSS_Ortung_2D_Geschw_ue_Grund 0;
BA_ "Fehlerwert" SG_ 884 GNSS_Ortung_2D_Geschw_ue_Grund 511;
BA_ "GenSigSendType" SG_ 884 GNSS_Ortung_Ausrichtung 0;
BA_ "GenSigStartValue" SG_ 884 GNSS_Ortung_Ausrichtung 4094;
BA_ "GenSigSwitchedByIgnition" SG_ 884 GNSS_Ortung_Ausrichtung 0;
BA_ "Fehlerwert" SG_ 884 GNSS_Ortung_Ausrichtung 4095;
BA_ "GenSigSendType" SG_ 884 GNSS_Ortung_Latenz 0;
BA_ "GenSigStartValue" SG_ 884 GNSS_Ortung_Latenz 1022;
BA_ "GenSigSwitchedByIgnition" SG_ 884 GNSS_Ortung_Latenz 0;
BA_ "Fehlerwert" SG_ 884 GNSS_Ortung_Latenz 1023;
BA_ "GenSigSendType" SG_ 884 GNSS_Ortung_Noerdliche_Geschw 0;
BA_ "GenSigStartValue" SG_ 884 GNSS_Ortung_Noerdliche_Geschw 1022;
BA_ "GenSigSwitchedByIgnition" SG_ 884 GNSS_Ortung_Noerdliche_Geschw 0;
BA_ "Fehlerwert" SG_ 884 GNSS_Ortung_Noerdliche_Geschw 1023;
BA_ "GenSigSendType" SG_ 884 GNSS_Ortung_Oestliche_Geschw 0;
BA_ "GenSigStartValue" SG_ 884 GNSS_Ortung_Oestliche_Geschw 1022;
BA_ "GenSigSwitchedByIgnition" SG_ 884 GNSS_Ortung_Oestliche_Geschw 0;
BA_ "Fehlerwert" SG_ 884 GNSS_Ortung_Oestliche_Geschw 1023;
BA_ "GenSigSendType" SG_ 884 GNSS_Ortung_Vertikale_Geschw 0;
BA_ "GenSigStartValue" SG_ 884 GNSS_Ortung_Vertikale_Geschw 1022;
BA_ "GenSigSwitchedByIgnition" SG_ 884 GNSS_Ortung_Vertikale_Geschw 0;
BA_ "Fehlerwert" SG_ 884 GNSS_Ortung_Vertikale_Geschw 1023;
BA_ "GenSigSendType" SG_ 886 GNSS_Nachrichtenpaket_ID3 0;
BA_ "GenSigSwitchedByIgnition" SG_ 886 GNSS_Nachrichtenpaket_ID3 0;
BA_ "GenSigSendType" SG_ 886 GNSS_Ortung_GDOP 0;
BA_ "GenSigStartValue" SG_ 886 GNSS_Ortung_GDOP 510;
BA_ "GenSigSwitchedByIgnition" SG_ 886 GNSS_Ortung_GDOP 0;
BA_ "Fehlerwert" SG_ 886 GNSS_Ortung_GDOP 511;
BA_ "GenSigSendType" SG_ 886 GNSS_Ortung_Guete_Ausrichtung 0;
BA_ "GenSigStartValue" SG_ 886 GNSS_Ortung_Guete_Ausrichtung 62;
BA_ "GenSigSwitchedByIgnition" SG_ 886 GNSS_Ortung_Guete_Ausrichtung 0;
BA_ "Fehlerwert" SG_ 886 GNSS_Ortung_Guete_Ausrichtung 63;
BA_ "GenSigSendType" SG_ 886 GNSS_Ortung_Guete_Geschwindigk 0;
BA_ "GenSigStartValue" SG_ 886 GNSS_Ortung_Guete_Geschwindigk 62;
BA_ "GenSigSwitchedByIgnition" SG_ 886 GNSS_Ortung_Guete_Geschwindigk 0;
BA_ "Fehlerwert" SG_ 886 GNSS_Ortung_Guete_Geschwindigk 63;
BA_ "GenSigSendType" SG_ 886 GNSS_Ortung_Guete_horizontal 0;
BA_ "GenSigStartValue" SG_ 886 GNSS_Ortung_Guete_horizontal 254;
BA_ "GenSigSwitchedByIgnition" SG_ 886 GNSS_Ortung_Guete_horizontal 0;
BA_ "Fehlerwert" SG_ 886 GNSS_Ortung_Guete_horizontal 255;
BA_ "GenSigSendType" SG_ 886 GNSS_Ortung_Guete_vertikal 0;
BA_ "GenSigStartValue" SG_ 886 GNSS_Ortung_Guete_vertikal 62;
BA_ "GenSigSwitchedByIgnition" SG_ 886 GNSS_Ortung_Guete_vertikal 0;
BA_ "Fehlerwert" SG_ 886 GNSS_Ortung_Guete_vertikal 63;
BA_ "GenSigSendType" SG_ 886 GNSS_Ortung_HDOP 0;
BA_ "GenSigStartValue" SG_ 886 GNSS_Ortung_HDOP 510;
BA_ "GenSigSwitchedByIgnition" SG_ 886 GNSS_Ortung_HDOP 0;
BA_ "Fehlerwert" SG_ 886 GNSS_Ortung_HDOP 511;
BA_ "GenSigSendType" SG_ 886 GNSS_Ortung_PDOP 0;
BA_ "GenSigStartValue" SG_ 886 GNSS_Ortung_PDOP 510;
BA_ "GenSigSwitchedByIgnition" SG_ 886 GNSS_Ortung_PDOP 0;
BA_ "Fehlerwert" SG_ 886 GNSS_Ortung_PDOP 511;
BA_ "GenSigSendType" SG_ 886 GNSS_Ortung_VDOP 0;
BA_ "GenSigStartValue" SG_ 886 GNSS_Ortung_VDOP 510;
BA_ "GenSigSwitchedByIgnition" SG_ 886 GNSS_Ortung_VDOP 0;
BA_ "Fehlerwert" SG_ 886 GNSS_Ortung_VDOP 511;
BA_ "GenSigSendType" SG_ 888 GNSS_Nachrichtenpaket_ID4 0;
BA_ "GenSigSwitchedByIgnition" SG_ 888 GNSS_Nachrichtenpaket_ID4 0;
BA_ "GenSigSendType" SG_ 888 GNSS_Ortung_Hoehe 0;
BA_ "GenSigStartValue" SG_ 888 GNSS_Ortung_Hoehe 4094;
BA_ "GenSigSwitchedByIgnition" SG_ 888 GNSS_Ortung_Hoehe 0;
BA_ "Fehlerwert" SG_ 888 GNSS_Ortung_Hoehe 4095;
BA_ "GenSigSendType" SG_ 888 GNSS_Ortung_Zeit_in_GPSWoche 0;
BA_ "GenSigStartValue" SG_ 888 GNSS_Ortung_Zeit_in_GPSWoche 1073741822;
BA_ "GenSigSwitchedByIgnition" SG_ 888 GNSS_Ortung_Zeit_in_GPSWoche 0;
BA_ "Fehlerwert" SG_ 888 GNSS_Ortung_Zeit_in_GPSWoche 1073741823;
BA_ "GenSigSendType" SG_ 891 GNSS_Empfaenger_Status 0;
BA_ "GenSigSwitchedByIgnition" SG_ 891 GNSS_Empfaenger_Status 0;
BA_ "GenSigSendType" SG_ 891 GNSS_Empfangbare_Satelliten 0;
BA_ "GenSigSwitchedByIgnition" SG_ 891 GNSS_Empfangbare_Satelliten 0;
BA_ "GenSigSendType" SG_ 891 GNSS_Genutzte_Satelliten 0;
BA_ "GenSigSwitchedByIgnition" SG_ 891 GNSS_Genutzte_Satelliten 0;
BA_ "GenSigSendType" SG_ 891 GNSS_GLONASS_in_Nutzung 0;
BA_ "GenSigSwitchedByIgnition" SG_ 891 GNSS_GLONASS_in_Nutzung 0;
BA_ "GenSigSendType" SG_ 891 GNSS_GPS_in_Nutzung 0;
BA_ "GenSigSwitchedByIgnition" SG_ 891 GNSS_GPS_in_Nutzung 0;
BA_ "GenSigSendType" SG_ 891 GNSS_Nachrichtenpaket_ID5 0;
BA_ "GenSigSwitchedByIgnition" SG_ 891 GNSS_Nachrichtenpaket_ID5 0;
BA_ "GenSigSendType" SG_ 891 GNSS_Sichtbare_Satelliten 0;
BA_ "GenSigSwitchedByIgnition" SG_ 891 GNSS_Sichtbare_Satelliten 0;
BA_ "GenSigSendType" SG_ 891 GNSS_UTC_Zeit 0;
BA_ "GenSigSwitchedByIgnition" SG_ 891 GNSS_UTC_Zeit 0;
BA_ "GenSigSendType" SG_ 1364 GNSS_Nachrichtenpaket_ID6 0;
BA_ "GenSigSwitchedByIgnition" SG_ 1364 GNSS_Nachrichtenpaket_ID6 0;
BA_ "GenSigSendType" SG_ 1364 GNSS_Sat_Info_Azimuth_ID_1 0;
BA_ "GenSigStartValue" SG_ 1364 GNSS_Sat_Info_Azimuth_ID_1 511;
BA_ "GenSigSwitchedByIgnition" SG_ 1364 GNSS_Sat_Info_Azimuth_ID_1 0;
BA_ "GenSigSendType" SG_ 1364 GNSS_Sat_Info_Hoehenwinkel_ID_1 0;
BA_ "GenSigStartValue" SG_ 1364 GNSS_Sat_Info_Hoehenwinkel_ID_1 127;
BA_ "GenSigSwitchedByIgnition" SG_ 1364 GNSS_Sat_Info_Hoehenwinkel_ID_1 0;
BA_ "GenSigSendType" SG_ 1364 GNSS_Sat_Info_Sat_ID_1 0;
BA_ "GenSigSwitchedByIgnition" SG_ 1364 GNSS_Sat_Info_Sat_ID_1 0;
BA_ "GenSigSendType" SG_ 1364 GNSS_Sat_Info_SNR_ID_1 0;
BA_ "GenSigStartValue" SG_ 1364 GNSS_Sat_Info_SNR_ID_1 31;
BA_ "GenSigSwitchedByIgnition" SG_ 1364 GNSS_Sat_Info_SNR_ID_1 0;
BA_ "GenSigSendType" SG_ 2463978722 GNSS_DR_Breite_Ortung 0;
BA_ "GenSigStartValue" SG_ 2463978722 GNSS_DR_Breite_Ortung 134217726;
BA_ "GenSigSwitchedByIgnition" SG_ 2463978722 GNSS_DR_Breite_Ortung 0;
BA_ "Fehlerwert" SG_ 2463978722 GNSS_DR_Breite_Ortung 134217727;
BA_ "GenSigSendType" SG_ 2463978722 GNSS_DR_Laenge_Ortung 0;
BA_ "GenSigStartValue" SG_ 2463978722 GNSS_DR_Laenge_Ortung 268435454;
BA_ "GenSigSwitchedByIgnition" SG_ 2463978722 GNSS_DR_Laenge_Ortung 0;
BA_ "Fehlerwert" SG_ 2463978722 GNSS_DR_Laenge_Ortung 268435455;
BA_ "GenSigSendType" SG_ 2463978722 GNSS_DR_Nachrichtenpaket_ID1 0;
BA_ "GenSigSwitchedByIgnition" SG_ 2463978722 GNSS_DR_Nachrichtenpaket_ID1 0;
BA_ "GenSigSendType" SG_ 2463978722 GNSS_DR_Richtung_Breite_Ortung 0;
BA_ "GenSigStartValue" SG_ 2463978722 GNSS_DR_Richtung_Breite_Ortung 1;
BA_ "GenSigSwitchedByIgnition" SG_ 2463978722 GNSS_DR_Richtung_Breite_Ortung 0;
BA_ "GenSigSendType" SG_ 2463978722 GNSS_DR_Richtung_Laenge_Ortung 0;
BA_ "GenSigStartValue" SG_ 2463978722 GNSS_DR_Richtung_Laenge_Ortung 1;
BA_ "GenSigSwitchedByIgnition" SG_ 2463978722 GNSS_DR_Richtung_Laenge_Ortung 0;
BA_REL_ "GenSigTimeoutTime" BU_SG_REL_ conBox SG_ 64 AB_Front_Crash 500;
BA_REL_ "GenSigTimeoutTime" BU_SG_REL_ conBox SG_ 64 AB_Heck_Crash 500;
BA_REL_ "GenSigTimeoutTime" BU_SG_REL_ conBox SG_ 64 AB_SF_Crash 500;
BA_REL_ "GenSigTimeoutTime" BU_SG_REL_ conBox SG_ 64 AB_SB_Crash 500;
BA_REL_ "GenSigTimeoutTime" BU_SG_REL_ conBox SG_ 64 AB_Rollover_Crash 500;
BA_REL_ "GenSigTimeoutTime" BU_SG_REL_ conBox SG_ 64 AB_Crash_Int 500;
BA_REL_ "GenSigTimeoutTime" BU_SG_REL_ conBox SG_ 64 AB_Systemfehler 500;
BA_REL_ "GenSigTimeoutTime" BU_SG_REL_ conBox SG_ 64 AB_Diagnose 500;
BA_REL_ "GenSigTimeoutTime" BU_SG_REL_ conBox SG_ 64 AB_Stellgliedtest 500;
BA_REL_ "GenSigTimeoutTime" BU_SG_REL_ conBox SG_ 64 AB_Anzeige_Fussg 500;
BA_REL_ "GenSigTimeoutTime" BU_SG_REL_ conBox SG_ 1312 AB_Anforderung_eCall 2000;
BA_REL_ "GenSigTimeoutTime" BU_SG_REL_ conBox SG_ 1312 AB_Belegung_VB 2000;
BA_REL_ "GenSigTimeoutTime" BU_SG_REL_ conBox SG_ 1312 AB_Gurtschloss_FA 2000;
BA_REL_ "GenSigTimeoutTime" BU_SG_REL_ conBox SG_ 1312 AB_Gurtschloss_BF 2000;
BA_REL_ "GenSigTimeoutTime" BU_SG_REL_ conBox SG_ 1312 AB_Gurtschloss_Reihe2_FA 2000;
BA_REL_ "GenSigTimeoutTime" BU_SG_REL_ conBox SG_ 1312 AB_Gurtschloss_Reihe2_MI 2000;
BA_REL_ "GenSigTimeoutTime" BU_SG_REL_ conBox SG_ 1312 AB_Gurtschloss_Reihe2_BF 2000;
BA_REL_ "GenSigTimeoutTime" BU_SG_REL_ conBox SG_ 1312 AB_Gurtschloss_Reihe3_FA 2000;
BA_REL_ "GenSigTimeoutTime" BU_SG_REL_ conBox SG_ 1312 AB_Gurtschloss_Reihe3_MI 2000;
BA_REL_ "GenSigTimeoutTime" BU_SG_REL_ conBox SG_ 1312 AB_Gurtschloss_Reihe3_BF 2000;
BA_REL_ "GenSigTimeoutTime" BU_SG_REL_ conBox SG_ 2589283629 BCM_DC_Suchvorgang_Status 5000;
BA_REL_ "GenSigTimeoutTime" BU_SG_REL_ conBox SG_ 2589283629 BCM_DC_Batterie_Status 5000;
BA_REL_ "GenSigTimeoutTime" BU_SG_REL_ conBox SG_ 2589283629 BCM_DC_erkannt 5000;
BA_REL_ "GenSigTimeoutTime" BU_SG_REL_ conBox SG_ 2589283629 BCM_DC_ID 5000;
BA_REL_ "GenSigTimeoutTime" BU_SG_REL_ conBox SG_ 961 eCall_Taste 2000;
BA_REL_ "GenSigTimeoutTime" BU_SG_REL_ conBox SG_ 870 BM_DWA_Alarm 5000;
BA_REL_ "GenSigTimeoutTime" BU_SG_REL_ conBox SG_ 870 BM_Warnblinken 5000;
BA_REL_ "GenSigTimeoutTime" BU_SG_REL_ conBox SG_ 870 BM_links 5000;
BA_REL_ "GenSigTimeoutTime" BU_SG_REL_ conBox SG_ 870 BM_rechts 5000;
BA_REL_ "GenSigTimeoutTime" BU_SG_REL_ conBox SG_ 870 DWA_Alarmquelle 5000;
BA_REL_ "GenSigTimeoutTime" BU_SG_REL_ conBox SG_ 1714 DGN_Verlernzaehler 5000;
BA_REL_ "GenSigTimeoutTime" BU_SG_REL_ conBox SG_ 1714 KBI_Kilometerstand 5000;
BA_REL_ "GenSigTimeoutTime" BU_SG_REL_ conBox SG_ 1714 UH_Jahr 5000;
BA_REL_ "GenSigTimeoutTime" BU_SG_REL_ conBox SG_ 1714 UH_Monat 5000;
BA_REL_ "GenSigTimeoutTime" BU_SG_REL_ conBox SG_ 1714 UH_Tag 5000;
BA_REL_ "GenSigTimeoutTime" BU_SG_REL_ conBox SG_ 1714 UH_Stunde 5000;
BA_REL_ "GenSigTimeoutTime" BU_SG_REL_ conBox SG_ 1714 UH_Minute 5000;
BA_REL_ "GenSigTimeoutTime" BU_SG_REL_ conBox SG_ 1714 UH_Sekunde 5000;
BA_REL_ "GenSigTimeoutTime" BU_SG_REL_ conBox SG_ 1520 DI_KL_58xd 2000;
BA_REL_ "GenSigTimeoutTime" BU_SG_REL_ conBox SG_ 420 EA_eCall_Anf 5000;
BA_REL_ "GenSigTimeoutTime" BU_SG_REL_ conBox SG_ 1603 KBI_Einheit_Sprache 5000;
BA_REL_ "GenSigTimeoutTime" BU_SG_REL_ conBox SG_ 259 ESP_VL_FR 500;
BA_REL_ "GenSigTimeoutTime" BU_SG_REL_ conBox SG_ 259 ESP_VR_FR 500;
BA_REL_ "GenSigTimeoutTime" BU_SG_REL_ conBox SG_ 259 ESP_HL_FR 500;
BA_REL_ "GenSigTimeoutTime" BU_SG_REL_ conBox SG_ 259 ESP_HR_FR 500;
BA_REL_ "GenSigTimeoutTime" BU_SG_REL_ conBox SG_ 259 ESP_VL_Radgeschw 500;
BA_REL_ "GenSigTimeoutTime" BU_SG_REL_ conBox SG_ 259 ESP_VR_Radgeschw 500;
BA_REL_ "GenSigTimeoutTime" BU_SG_REL_ conBox SG_ 259 ESP_HL_Radgeschw 500;
BA_REL_ "GenSigTimeoutTime" BU_SG_REL_ conBox SG_ 259 ESP_HR_Radgeschw 500;
BA_REL_ "GenSigTimeoutTime" BU_SG_REL_ conBox SG_ 278 ESP_QBit_Wegimpuls_VL 500;
BA_REL_ "GenSigTimeoutTime" BU_SG_REL_ conBox SG_ 278 ESP_QBit_Wegimpuls_VR 500;
BA_REL_ "GenSigTimeoutTime" BU_SG_REL_ conBox SG_ 278 ESP_QBit_Wegimpuls_HL 500;
BA_REL_ "GenSigTimeoutTime" BU_SG_REL_ conBox SG_ 278 ESP_QBit_Wegimpuls_HR 500;
BA_REL_ "GenSigTimeoutTime" BU_SG_REL_ conBox SG_ 278 ESP_Wegimpuls_VL 500;
BA_REL_ "GenSigTimeoutTime" BU_SG_REL_ conBox SG_ 278 ESP_Wegimpuls_VR 500;
BA_REL_ "GenSigTimeoutTime" BU_SG_REL_ conBox SG_ 278 ESP_Wegimpuls_HL 500;
BA_REL_ "GenSigTimeoutTime" BU_SG_REL_ conBox SG_ 278 ESP_Wegimpuls_HR 500;
BA_REL_ "GenSigTimeoutTime" BU_SG_REL_ conBox SG_ 278 ESP_VL_Fahrtrichtung 500;
BA_REL_ "GenSigTimeoutTime" BU_SG_REL_ conBox SG_ 278 ESP_VR_Fahrtrichtung 500;
BA_REL_ "GenSigTimeoutTime" BU_SG_REL_ conBox SG_ 278 ESP_HL_Fahrtrichtung 500;
BA_REL_ "GenSigTimeoutTime" BU_SG_REL_ conBox SG_ 278 ESP_HR_Fahrtrichtung 500;
BA_REL_ "GenSigTimeoutTime" BU_SG_REL_ conBox SG_ 1629 ESP_Zaehnezahl 1600;
BA_REL_ "GenSigTimeoutTime" BU_SG_REL_ conBox SG_ 1629 BR_QBit_Reifenumfang 1600;
BA_REL_ "GenSigTimeoutTime" BU_SG_REL_ conBox SG_ 1629 BR_Reifenumfang 1600;
BA_REL_ "GenSigTimeoutTime" BU_SG_REL_ conBox SG_ 253 ESP_v_Signal 500;
BA_REL_ "GenSigTimeoutTime" BU_SG_REL_ conBox SG_ 253 ESP_Systemstatus 500;
BA_REL_ "GenSigTimeoutTime" BU_SG_REL_ conBox SG_ 253 ESP_QBit_v_Signal 500;
BA_REL_ "GenSigTimeoutTime" BU_SG_REL_ conBox SG_ 253 ABS_Bremsung 500;
BA_REL_ "GenSigTimeoutTime" BU_SG_REL_ conBox SG_ 253 EBV_Eingriff 500;
BA_REL_ "GenSigTimeoutTime" BU_SG_REL_ conBox SG_ 253 ESP_Eingriff 500;
BA_REL_ "GenSigTimeoutTime" BU_SG_REL_ conBox SG_ 508 ESP_Stillstandsflag 2000;
BA_REL_ "GenSigTimeoutTime" BU_SG_REL_ conBox SG_ 508 ESP_Notbremsanzeige 2000;
BA_REL_ "GenSigTimeoutTime" BU_SG_REL_ Gateway SG_ 2589283655 eCall2_Statuslicht_Farbe2 5000;
BA_REL_ "GenSigTimeoutTime" BU_SG_REL_ Gateway SG_ 2589283655 eCall2_Statuslicht_Farbe1 5000;
BA_REL_ "GenSigTimeoutTime" BU_SG_REL_ Gateway SG_ 2589283655 eCall2_Funktionsstatus 5000;
BA_REL_ "GenSigTimeoutTime" BU_SG_REL_ Gateway SG_ 2589283655 eCall2_Subscription 5000;
BA_REL_ "GenSigTimeoutTime" BU_SG_REL_ Gateway SG_ 2589283655 ConBox_T6_Status 5000;
BA_REL_ "GenSigTimeoutTime" BU_SG_REL_ Gateway SG_ 2589283655 eCall2_Funktionsstatus_02 5000;
BA_REL_ "GenSigTimeoutTime" BU_SG_REL_ Gateway SG_ 2589283655 ConBox_T3_Status 5000;
BA_REL_ "GenSigTimeoutTime" BU_SG_REL_ Gateway SG_ 2589283655 eCall2_Mute_Anf 5000;
BA_REL_ "GenSigTimeoutTime" BU_SG_REL_ Gateway SG_ 879 GNSS_Nachrichtenpaket_ID1 5000;
BA_REL_ "GenSigTimeoutTime" BU_SG_REL_ Gateway SG_ 879 GNSS_Breite_Ortung 5000;
BA_REL_ "GenSigTimeoutTime" BU_SG_REL_ Gateway SG_ 879 GNSS_Richtung_Breite_Ortung 5000;
BA_REL_ "GenSigTimeoutTime" BU_SG_REL_ Gateway SG_ 879 GNSS_Laenge_Ortung 5000;
BA_REL_ "GenSigTimeoutTime" BU_SG_REL_ Gateway SG_ 879 GNSS_Richtung_Laenge_Ortung 5000;
BA_REL_ "GenSigTimeoutTime" BU_SG_REL_ Gateway SG_ 879 GNSS_Ortung_FIX_Typ 5000;
BA_REL_ "GenSigTimeoutTime" BU_SG_REL_ Gateway SG_ 879 GNSS_Fehlerzustand 5000;
BA_REL_ "GenSigTimeoutTime" BU_SG_REL_ Gateway SG_ 884 GNSS_Nachrichtenpaket_ID2 5000;
BA_REL_ "GenSigTimeoutTime" BU_SG_REL_ Gateway SG_ 884 GNSS_Ortung_Latenz 5000;
BA_REL_ "GenSigTimeoutTime" BU_SG_REL_ Gateway SG_ 884 GNSS_Ortung_Ausrichtung 5000;
BA_REL_ "GenSigTimeoutTime" BU_SG_REL_ Gateway SG_ 884 GNSS_Ortung_2D_Geschw_ue_Grund 5000;
BA_REL_ "GenSigTimeoutTime" BU_SG_REL_ Gateway SG_ 884 GNSS_Ortung_Noerdliche_Geschw 5000;
BA_REL_ "GenSigTimeoutTime" BU_SG_REL_ Gateway SG_ 884 GNSS_Ortung_Oestliche_Geschw 5000;
BA_REL_ "GenSigTimeoutTime" BU_SG_REL_ Gateway SG_ 884 GNSS_Ortung_Vertikale_Geschw 5000;
BA_REL_ "GenSigTimeoutTime" BU_SG_REL_ Gateway SG_ 886 GNSS_Nachrichtenpaket_ID3 5000;
BA_REL_ "GenSigTimeoutTime" BU_SG_REL_ Gateway SG_ 886 GNSS_Ortung_GDOP 5000;
BA_REL_ "GenSigTimeoutTime" BU_SG_REL_ Gateway SG_ 886 GNSS_Ortung_PDOP 5000;
BA_REL_ "GenSigTimeoutTime" BU_SG_REL_ Gateway SG_ 886 GNSS_Ortung_HDOP 5000;
BA_REL_ "GenSigTimeoutTime" BU_SG_REL_ Gateway SG_ 886 GNSS_Ortung_VDOP 5000;
BA_REL_ "GenSigTimeoutTime" BU_SG_REL_ Gateway SG_ 886 GNSS_Ortung_Guete_Geschwindigk 5000;
BA_REL_ "GenSigTimeoutTime" BU_SG_REL_ Gateway SG_ 886 GNSS_Ortung_Guete_Ausrichtung 5000;
BA_REL_ "GenSigTimeoutTime" BU_SG_REL_ Gateway SG_ 886 GNSS_Ortung_Guete_horizontal 5000;
BA_REL_ "GenSigTimeoutTime" BU_SG_REL_ Gateway SG_ 886 GNSS_Ortung_Guete_vertikal 5000;
BA_REL_ "GenSigTimeoutTime" BU_SG_REL_ Gateway SG_ 888 GNSS_Nachrichtenpaket_ID4 5000;
BA_REL_ "GenSigTimeoutTime" BU_SG_REL_ Gateway SG_ 888 GNSS_Ortung_Zeit_in_GPSWoche 5000;
BA_REL_ "GenSigTimeoutTime" BU_SG_REL_ Gateway SG_ 888 GNSS_Ortung_Hoehe 5000;
BA_REL_ "GenSigTimeoutTime" BU_SG_REL_ Gateway SG_ 891 GNSS_UTC_Zeit 5000;
BA_REL_ "GenSigTimeoutTime" BU_SG_REL_ Gateway SG_ 891 GNSS_Empfaenger_Status 5000;
BA_REL_ "GenSigTimeoutTime" BU_SG_REL_ Gateway SG_ 891 GNSS_GPS_in_Nutzung 5000;
BA_REL_ "GenSigTimeoutTime" BU_SG_REL_ Gateway SG_ 891 GNSS_GLONASS_in_Nutzung 5000;
BA_REL_ "GenSigTimeoutTime" BU_SG_REL_ Gateway SG_ 891 GNSS_Empfangbare_Satelliten 5000;
BA_REL_ "GenSigTimeoutTime" BU_SG_REL_ Gateway SG_ 891 GNSS_Sichtbare_Satelliten 5000;
BA_REL_ "GenSigTimeoutTime" BU_SG_REL_ Gateway SG_ 891 GNSS_Genutzte_Satelliten 5000;
BA_REL_ "GenSigTimeoutTime" BU_SG_REL_ Gateway SG_ 891 GNSS_Nachrichtenpaket_ID5 5000;
BA_REL_ "GenSigTimeoutTime" BU_SG_REL_ Gateway SG_ 1364 GNSS_Sat_Info_Sat_ID_1 5000;
BA_REL_ "GenSigTimeoutTime" BU_SG_REL_ Gateway SG_ 1364 GNSS_Sat_Info_SNR_ID_1 5000;
BA_REL_ "GenSigTimeoutTime" BU_SG_REL_ Gateway SG_ 1364 GNSS_Sat_Info_Azimuth_ID_1 5000;
BA_REL_ "GenSigTimeoutTime" BU_SG_REL_ Gateway SG_ 1364 GNSS_Sat_Info_Hoehenwinkel_ID_1 5000;
BA_REL_ "GenSigTimeoutTime" BU_SG_REL_ Gateway SG_ 1364 GNSS_Nachrichtenpaket_ID6 5000;
BA_REL_ "GenSigTimeoutTime" BU_SG_REL_ Gateway SG_ 2463978722 GNSS_DR_Nachrichtenpaket_ID1 1000;
BA_REL_ "GenSigTimeoutTime" BU_SG_REL_ Gateway SG_ 2463978722 GNSS_DR_Breite_Ortung 1000;
BA_REL_ "GenSigTimeoutTime" BU_SG_REL_ Gateway SG_ 2463978722 GNSS_DR_Richtung_Breite_Ortung 1000;
BA_REL_ "GenSigTimeoutTime" BU_SG_REL_ Gateway SG_ 2463978722 GNSS_DR_Laenge_Ortung 1000;
BA_REL_ "GenSigTimeoutTime" BU_SG_REL_ Gateway SG_ 2463978722 GNSS_DR_Richtung_Laenge_Ortung 1000;
BA_REL_ "GenSigTimeoutTime" BU_SG_REL_ Gateway_PAG SG_ 2589283655 eCall2_Statuslicht_Farbe2 5000;
BA_REL_ "GenSigTimeoutTime" BU_SG_REL_ Gateway_PAG SG_ 2589283655 eCall2_Statuslicht_Farbe1 5000;
BA_REL_ "GenSigTimeoutTime" BU_SG_REL_ Gateway_PAG SG_ 2589283655 eCall2_Funktionsstatus 5000;
BA_REL_ "GenSigTimeoutTime" BU_SG_REL_ Gateway_PAG SG_ 2589283655 eCall2_Subscription 5000;
BA_REL_ "GenSigTimeoutTime" BU_SG_REL_ Gateway_PAG SG_ 2589283655 ConBox_T6_Status 5000;
BA_REL_ "GenSigTimeoutTime" BU_SG_REL_ Gateway_PAG SG_ 2589283655 eCall2_Funktionsstatus_02 5000;
BA_REL_ "GenSigTimeoutTime" BU_SG_REL_ Gateway_PAG SG_ 2589283655 ConBox_T3_Status 5000;
BA_REL_ "GenSigTimeoutTime" BU_SG_REL_ Gateway_PAG SG_ 2589283655 eCall2_Mute_Anf 5000;
BA_REL_ "GenSigTimeoutTime" BU_SG_REL_ Gateway_PAG SG_ 879 GNSS_Nachrichtenpaket_ID1 5000;
BA_REL_ "GenSigTimeoutTime" BU_SG_REL_ Gateway_PAG SG_ 879 GNSS_Breite_Ortung 5000;
BA_REL_ "GenSigTimeoutTime" BU_SG_REL_ Gateway_PAG SG_ 879 GNSS_Richtung_Breite_Ortung 5000;
BA_REL_ "GenSigTimeoutTime" BU_SG_REL_ Gateway_PAG SG_ 879 GNSS_Laenge_Ortung 5000;
BA_REL_ "GenSigTimeoutTime" BU_SG_REL_ Gateway_PAG SG_ 879 GNSS_Richtung_Laenge_Ortung 5000;
BA_REL_ "GenSigTimeoutTime" BU_SG_REL_ Gateway_PAG SG_ 879 GNSS_Ortung_FIX_Typ 5000;
BA_REL_ "GenSigTimeoutTime" BU_SG_REL_ Gateway_PAG SG_ 879 GNSS_Fehlerzustand 5000;
BA_REL_ "GenSigTimeoutTime" BU_SG_REL_ Gateway_PAG SG_ 884 GNSS_Nachrichtenpaket_ID2 5000;
BA_REL_ "GenSigTimeoutTime" BU_SG_REL_ Gateway_PAG SG_ 884 GNSS_Ortung_Latenz 5000;
BA_REL_ "GenSigTimeoutTime" BU_SG_REL_ Gateway_PAG SG_ 884 GNSS_Ortung_Ausrichtung 5000;
BA_REL_ "GenSigTimeoutTime" BU_SG_REL_ Gateway_PAG SG_ 884 GNSS_Ortung_2D_Geschw_ue_Grund 5000;
BA_REL_ "GenSigTimeoutTime" BU_SG_REL_ Gateway_PAG SG_ 884 GNSS_Ortung_Noerdliche_Geschw 5000;
BA_REL_ "GenSigTimeoutTime" BU_SG_REL_ Gateway_PAG SG_ 884 GNSS_Ortung_Oestliche_Geschw 5000;
BA_REL_ "GenSigTimeoutTime" BU_SG_REL_ Gateway_PAG SG_ 884 GNSS_Ortung_Vertikale_Geschw 5000;
BA_REL_ "GenSigTimeoutTime" BU_SG_REL_ Gateway_PAG SG_ 886 GNSS_Nachrichtenpaket_ID3 5000;
BA_REL_ "GenSigTimeoutTime" BU_SG_REL_ Gateway_PAG SG_ 886 GNSS_Ortung_GDOP 5000;
BA_REL_ "GenSigTimeoutTime" BU_SG_REL_ Gateway_PAG SG_ 886 GNSS_Ortung_PDOP 5000;
BA_REL_ "GenSigTimeoutTime" BU_SG_REL_ Gateway_PAG SG_ 886 GNSS_Ortung_HDOP 5000;
BA_REL_ "GenSigTimeoutTime" BU_SG_REL_ Gateway_PAG SG_ 886 GNSS_Ortung_VDOP 5000;
BA_REL_ "GenSigTimeoutTime" BU_SG_REL_ Gateway_PAG SG_ 886 GNSS_Ortung_Guete_Geschwindigk 5000;
BA_REL_ "GenSigTimeoutTime" BU_SG_REL_ Gateway_PAG SG_ 886 GNSS_Ortung_Guete_Ausrichtung 5000;
BA_REL_ "GenSigTimeoutTime" BU_SG_REL_ Gateway_PAG SG_ 886 GNSS_Ortung_Guete_horizontal 5000;
BA_REL_ "GenSigTimeoutTime" BU_SG_REL_ Gateway_PAG SG_ 886 GNSS_Ortung_Guete_vertikal 5000;
BA_REL_ "GenSigTimeoutTime" BU_SG_REL_ Gateway_PAG SG_ 888 GNSS_Nachrichtenpaket_ID4 5000;
BA_REL_ "GenSigTimeoutTime" BU_SG_REL_ Gateway_PAG SG_ 888 GNSS_Ortung_Zeit_in_GPSWoche 5000;
BA_REL_ "GenSigTimeoutTime" BU_SG_REL_ Gateway_PAG SG_ 888 GNSS_Ortung_Hoehe 5000;
BA_REL_ "GenSigTimeoutTime" BU_SG_REL_ Gateway_PAG SG_ 891 GNSS_UTC_Zeit 5000;
BA_REL_ "GenSigTimeoutTime" BU_SG_REL_ Gateway_PAG SG_ 891 GNSS_Empfaenger_Status 5000;
BA_REL_ "GenSigTimeoutTime" BU_SG_REL_ Gateway_PAG SG_ 891 GNSS_GPS_in_Nutzung 5000;
BA_REL_ "GenSigTimeoutTime" BU_SG_REL_ Gateway_PAG SG_ 891 GNSS_GLONASS_in_Nutzung 5000;
BA_REL_ "GenSigTimeoutTime" BU_SG_REL_ Gateway_PAG SG_ 891 GNSS_Empfangbare_Satelliten 5000;
BA_REL_ "GenSigTimeoutTime" BU_SG_REL_ Gateway_PAG SG_ 891 GNSS_Sichtbare_Satelliten 5000;
BA_REL_ "GenSigTimeoutTime" BU_SG_REL_ Gateway_PAG SG_ 891 GNSS_Genutzte_Satelliten 5000;
BA_REL_ "GenSigTimeoutTime" BU_SG_REL_ Gateway_PAG SG_ 891 GNSS_Nachrichtenpaket_ID5 5000;
BA_REL_ "GenSigTimeoutTime" BU_SG_REL_ Gateway_PAG SG_ 1364 GNSS_Sat_Info_Sat_ID_1 5000;
BA_REL_ "GenSigTimeoutTime" BU_SG_REL_ Gateway_PAG SG_ 1364 GNSS_Sat_Info_SNR_ID_1 5000;
BA_REL_ "GenSigTimeoutTime" BU_SG_REL_ Gateway_PAG SG_ 1364 GNSS_Sat_Info_Azimuth_ID_1 5000;
BA_REL_ "GenSigTimeoutTime" BU_SG_REL_ Gateway_PAG SG_ 1364 GNSS_Sat_Info_Hoehenwinkel_ID_1 5000;
BA_REL_ "GenSigTimeoutTime" BU_SG_REL_ Gateway_PAG SG_ 1364 GNSS_Nachrichtenpaket_ID6 5000;
BA_REL_ "GenSigTimeoutTime" BU_SG_REL_ Gateway_PAG SG_ 2463978722 GNSS_DR_Nachrichtenpaket_ID1 1000;
BA_REL_ "GenSigTimeoutTime" BU_SG_REL_ Gateway_PAG SG_ 2463978722 GNSS_DR_Breite_Ortung 1000;
BA_REL_ "GenSigTimeoutTime" BU_SG_REL_ Gateway_PAG SG_ 2463978722 GNSS_DR_Richtung_Breite_Ortung 1000;
BA_REL_ "GenSigTimeoutTime" BU_SG_REL_ Gateway_PAG SG_ 2463978722 GNSS_DR_Laenge_Ortung 1000;
BA_REL_ "GenSigTimeoutTime" BU_SG_REL_ Gateway_PAG SG_ 2463978722 GNSS_DR_Richtung_Laenge_Ortung 1000;
VAL_ 64 AB_RGS_Anst 4 "aktiv_Niveau_1" 5 "aktiv_Niveau_2" 6 "aktiv_Niveau_3" 7 "aktiv_Niveau_4" 8 "deaktiviert" ;
VAL_ 64 AB_Front_Crash 0 "kein_Front_Crash" 1 "Front_Crash" ;
VAL_ 64 AB_Heck_Crash 0 "kein_Heck_Crash" 1 "Heck_Crash" ;
VAL_ 64 AB_SF_Crash 0 "kein_Seiten_Crash_Fahrer" 1 "Seiten_Crash_Fahrer" ;
VAL_ 64 AB_SB_Crash 0 "kein_Seiten_Crash_Beifahrer" 1 "Seiten_Crash_Beifahrer" ;
VAL_ 64 AB_Rollover_Crash 0 "kein_Rollover" 1 "Rollover" ;
VAL_ 64 AB_Crash_Int 0 "kein_Crash" 1 "Crash_Intensitaet_1" 2 "Crash_Intensitaet_2_(nur_Stellgliedtest_MLB_B8)" 3 "Crash_Intensitaet_2_(nur_D4_C7_Colorado_NF_PAG__Crash_im_MLB_B8)" 4 "Crash_Intensitaet_3_(alt_VW/AUDI__Stellgliedtest_MLB_B8)" 5 "Crash_Intensitaet_3_(alt_PAG)" 7 "Crash_Intensitaet_3" ;
VAL_ 64 AB_Lampe 0 "Aus" 1 "Ein" ;
VAL_ 64 AB_Deaktiviert 0 "aktiv" 1 "deaktiviert" ;
VAL_ 64 AB_VB_deaktiviert 0 "Beifahrerairbag_aktiv" 1 "Beifahrerairbag_deaktiviert" ;
VAL_ 64 AB_Systemfehler 0 "kein_Fehler" 1 "Airbag_Systemfehler" ;
VAL_ 64 AB_Diagnose 0 "nicht_in_Diagnose" 1 "in_Diagnose" ;
VAL_ 64 AB_Stellgliedtest 0 "nicht_im_Stellgliedtest" 1 "Airbag_im_Stellgliedtest" ;
VAL_ 64 AB_Erh_Auf_VB 0 "keine_Anzeige" 1 "Beifahrerairbag_deaktiviert" 2 "Beifahrerairbag_aktiviert" 3 "nicht_definiert" ;
VAL_ 64 AB_Gurtwarn_VF 0 "keine_Warnung" 1 "Gurtwarnung_ausloesen" ;
VAL_ 64 AB_Gurtwarn_VB 0 "keine_Warnung" 1 "Gurtwarnung_ausloesen" ;
VAL_ 64 AB_Anzeige_Fussg 0 "keine_FSG_Aktion_ausgeloest" 1 "Motorhaube_offen" 2 "Systemfehler" ;
VAL_ 64 AB_Texte_AKS 0 "keine_AKS_Ausloesung" 1 "AKS_ausgeloest" 2 "AKS_Systemfehler" ;
VAL_ 64 AB_MKB_gueltig 0 "Multikollisionsbremsung_nicht_freigeschaltet" 1 "Multikollisionsbremsung_freigeschaltet" ;
VAL_ 64 AB_MKB_Anforderung 0 "Multikollisionsbremsung_nicht_angefordert" 1 "Multikollisionsbremsung_angefordert" ;
VAL_ 64 AB_Versorgungsspannung 0 "plausibel" 1 "unplausibel" ;
VAL_ 64 AB_Deaktivierung_HV 0 "keine_Deaktivierung" 1 "Deaktivierung_1" 2 "Deaktivierung_2" 3 "Deaktivierung_3" 4 "Deaktivierung_4" 5 "Deaktivierung_5" 6 "Deaktivierung_6" 7 "Fehler" ;
VAL_ 64 AB_EDR_Trigger 0 "No_Event" 1 "Start_Event" 2 "NonDeployment_Event" 3 "Deployment_Event" ;
VAL_ 64 AB_Belegung_VF 0 "nicht_verfuegbar" 1 "Fehler" 2 "nicht_belegt" 3 "belegt" ;
VAL_ 64 SC_LowSpeedCrashErkannt 0 "kein_Crash_erkannt" 1 "Crash_Frontbereich_erkannt" 2 "Crash_Heckbereich_erkannt" 3 "Crash_Front_und_Heckbereich_erkannt" ;
VAL_ 64 SC_Masterzeit 127 "Init" ;
VAL_ 1312 LoGeWa_Event_Kombiwarnung 0 "Init" 1 "Unfall" 2 "Traktionsverlust" 3 "Panne" 4 "Sichtbehinderung" 5 "Aquaplaning" ;
VAL_ 1312 AB_Anforderung_eCall 0 "keine_Anforderung" 1 "Anforderung" ;
VAL_ 1312 AB_Anprall_Seite_Beifahrer 0 "kein_Anprall" 1 "Anprall_erkannt" ;
VAL_ 1312 AB_Anprall_Rollover 0 "kein_Anprall" 1 "Anprall_erkannt" ;
VAL_ 1312 AB_Anprall_FGS 0 "kein_Anprall" 1 "Anprall_erkannt" ;
VAL_ 1312 AB_Anprall_Front_Beifahrer 0 "kein_Anprall" 1 "Anprall_erkannt" ;
VAL_ 1312 AB_Anprall_Front_Fahrer 0 "kein_Anprall" 1 "Anprall_erkannt" ;
VAL_ 1312 AB_Anprall_Heck_Beifahrer 0 "kein_Anprall" 1 "Anprall_erkannt" ;
VAL_ 1312 AB_Anprall_Heck_Fahrer 0 "kein_Anprall" 1 "Anprall_erkannt" ;
VAL_ 1312 AB_Wickelklappung_Reihe2_MI 0 "nicht_verbaut" 1 "nicht_verfuegbar__Fehler_oder_Init" 2 "nicht_verriegelt" 3 "verriegelt" ;
VAL_ 1312 AB_Belegung_VB 0 "nicht_verfuegbar" 1 "Fehler" 2 "nicht_belegt" 3 "belegt" ;
VAL_ 1312 AB_Abschaltanf_SIH_BF 0 "Normalbetrieb" 1 "Abschaltung_angefordert" ;
VAL_ 1312 AB_Anprall_Seite_Fahrer 0 "kein_Anprall" 1 "Anprall_erkannt" ;
VAL_ 1312 SC_PAO_Schriftzug_Anf 0 "LED aus" 1 "LED an" 2 "LED blinken" 3 "reserviert" ;
VAL_ 1312 SC_PAO_ON_Anf 0 "LED aus" 1 "LED an" 2 "LED blinken" 3 "reserviert" ;
VAL_ 1312 SC_PAO_OFF_Anf 0 "LED aus" 1 "LED an" 2 "LED blinken" 3 "reserviert" ;
VAL_ 1312 AB_Crashschwere 0 "kein_Ereignis" 1 "Crashschwere_1" 2 "Crashschwere_2" 3 "Crashschwere_3" 4 "Crashschwere_4" 5 "Crashschwere_5" 6 "Crashschwere_2_bis_5" 7 "Fehler" ;
VAL_ 1312 AB_Anforderung_USM 0 "keine_Anforderung" 1 "Anforderung" ;
VAL_ 1312 AB_Gurtschloss_FA 0 "nicht_verbaut" 1 "nicht_verfügbar (Fehler oder Init)" 2 "nicht_gesteckt" 3 "gesteckt" ;
VAL_ 1312 AB_Gurtschloss_BF 0 "nicht_verbaut" 1 "nicht_verfügbar (Fehler oder Init)" 2 "nicht_gesteckt" 3 "gesteckt" ;
VAL_ 1312 AB_Gurtschloss_Reihe2_FA 0 "nicht_verbaut" 1 "nicht_verfügbar (Fehler oder Init)" 2 "nicht_gesteckt" 3 "gesteckt" ;
VAL_ 1312 AB_Gurtschloss_Reihe2_MI 0 "nicht_verbaut" 1 "nicht_verfügbar (Fehler oder Init)" 2 "nicht_gesteckt" 3 "gesteckt" ;
VAL_ 1312 AB_Gurtschloss_Reihe2_BF 0 "nicht_verbaut" 1 "nicht_verfügbar (Fehler oder Init)" 2 "nicht_gesteckt" 3 "gesteckt" ;
VAL_ 1312 AB_Gurtschloss_Reihe3_FA 0 "nicht_verbaut" 1 "nicht_verfügbar (Fehler oder Init)" 2 "nicht_gesteckt" 3 "gesteckt" ;
VAL_ 1312 AB_Gurtschloss_Reihe3_MI 0 "nicht_verbaut" 1 "nicht_verfügbar (Fehler oder Init)" 2 "nicht_gesteckt" 3 "gesteckt" ;
VAL_ 1312 AB_Gurtschloss_Reihe3_BF 0 "nicht_verbaut" 1 "nicht_verfügbar (Fehler oder Init)" 2 "nicht_gesteckt" 3 "gesteckt" ;
VAL_ 1312 AB_Sitzpos_Sens_FA 0 "nicht verfügbar" 1 "Fehler" 2 "Sitz nicht vorne" 3 "Sitz vorne" ;
VAL_ 1312 AB_Sitzpos_Sens_BF 0 "nicht verfügbar" 1 "Fehler" 2 "Sitz nicht vorne" 3 "Sitz vorne" ;
VAL_ 1312 AB_Wickelklappung_Reihe2_BF 0 "nicht_verbaut" 1 "nicht_verfuegbar__Fehler_oder_Init" 2 "nicht_verriegelt" 3 "verriegelt" ;
VAL_ 1312 AB_Wickelklappung_Reihe2_FA 0 "nicht_verbaut" 1 "nicht_verfuegbar__Fehler_oder_Init" 2 "nicht_verriegelt" 3 "verriegelt" ;
VAL_ 2589283629 BCM_DC_Suchvorgang_Status 0 "Init" 1 "Suche_nicht_OK" 2 "Transponderbetrieb_Suche_nicht_moeglich" 3 "reserved" ;
VAL_ 2589283629 BCM_DC_Batterie_Status 0 "Batteriestatus_OK" 1 "Batteriestatus_schwach" ;
VAL_ 2589283629 BCM_DC_erkannt 0 "Init" 1 "Driver_Card_Nr_1" 2 "Driver_Card_Nr_2" 3 "Driver_Card_Nr_3" 4 "Driver_Card_Nr_4" 5 "Driver_Card_Nr_5" 6 "Driver_Card_Nr_6" 7 "Driver_Card_Nr_7" ;
VAL_ 961 Heckrollo_2_Taster 0 "Taste_nicht_betaetigt" 1 "Taste_entprellt_betaetigt" 2 "Init_oder_nicht_verbaut" 3 "Fehler" ;
VAL_ 961 APS_Taster 0 "Taste_nicht_betaetigt" 1 "Taste_entprellt_betaetigt" 2 "Init_oder_nicht_verbaut" 3 "Fehler" ;
VAL_ 961 PLA_Taster 0 "Taste_nicht_betaetigt" 1 "Taste_entprellt_betaetigt" 2 "Init_oder_nicht_verbaut" 3 "Fehler" ;
VAL_ 961 ESP_Off_Taster 0 "Taste_nicht_betaetigt" 1 "Taste_entprellt_betaetigt" 2 "Init_oder_nicht_verbaut" 3 "Fehler" ;
VAL_ 961 HDC_Taster 0 "Taste_nicht_betaetigt" 1 "Taste_entprellt_betaetigt" 2 "Init_oder_nicht_verbaut" 3 "Fehler" ;
VAL_ 961 AVH_Taster 0 "Taste_nicht_betaetigt" 1 "Taste_entprellt_betaetigt" 2 "Init_oder_nicht_verbaut" 3 "Fehler" ;
VAL_ 961 Display_Taster 0 "Taste_nicht_betaetigt" 1 "Taste_entprellt_betaetigt" 2 "Init_oder_nicht_verbaut" 3 "Fehler" ;
VAL_ 961 Heckrollo_Taster 0 "Taste_nicht_betaetigt" 1 "Taste_entprellt_betaetigt" 2 "Init_oder_nicht_verbaut" 3 "Fehler" ;
VAL_ 961 Spoiler_Taster 0 "Taste_nicht_betaetigt" 1 "Taste_entprellt_betaetigt" 2 "Init_oder_nicht_verbaut" 3 "Fehler" ;
VAL_ 961 Drivesel_1_Taster 0 "Taste_nicht_betaetigt" 1 "Taste_entprellt_betaetigt" 2 "Init_oder_nicht_verbaut" 3 "Fehler" ;
VAL_ 961 Drivesel_2_Taster 0 "Taste_nicht_betaetigt" 1 "Taste_entprellt_betaetigt" 2 "Init_oder_nicht_verbaut" 3 "Fehler" ;
VAL_ 961 Sideview_Taster 0 "Taste_nicht_betaetigt" 1 "Taste_entprellt_betaetigt" 2 "Init_oder_nicht_verbaut" 3 "Fehler" ;
VAL_ 961 LKS_Taster 0 "Taste_nicht_betaetigt" 1 "Taste_betaetigt" 2 "INIT_Taste_nicht_verbaut" 3 "Fehler" ;
VAL_ 961 SWA_Taster 0 "nicht_betaetigt" 1 "betaetigt" 2 "nicht_vorhanden" 3 "Fehler" ;
VAL_ 961 LIM_bCall_Taster 0 "nicht_betaetigt" 1 "betaetigt" ;
VAL_ 961 eCall_Taste 0 "button_released" 1 "button_pressed" 2 "discrete_line_broken" 3 "Fehler" ;
VAL_ 961 PLA_Taster_Fehler_Roh 0 "kein Fehler vorhanden" 1 "Fehler vorhanden" ;
VAL_ 961 LIM_PAO_ON_Status 0 "LED aus" 1 "LED an" 2 "LED blinkt" 3 "LED defekt" ;
VAL_ 961 LIM_PAO_OFF_Status 0 "LED aus" 1 "LED an" 2 "LED blinkt" 3 "LED defekt" ;
VAL_ 961 LIM_PAO_Schriftzug_Status 0 "LED aus" 1 "LED an" 2 "LED blinkt" 3 "LED defekt" ;
VAL_ 961 Spoiler_LED_Status 0 "LED_aus" 1 "LED_ein" 2 "LED_blinken" 3 "Fehler" ;
VAL_ 961 AVH_LED_Status 0 "LED_aus" 1 "LED_ein" 2 "LED_blinken" 3 "Fehler" ;
VAL_ 961 HDC_LED_Status 0 "LED_aus" 1 "LED_ein" 2 "LED_blinken" 3 "Fehler" ;
VAL_ 961 PLA_LED_Status 0 "LED_aus" 1 "LED_ein" 2 "LED_blinken" 3 "Fehler" ;
VAL_ 961 APS_LED_Status 0 "LED_aus" 1 "LED_ein" 2 "LED_blinken" 3 "Fehler" ;
VAL_ 870 BM_ZV_auf 0 "inaktiv" 1 "aktiv" ;
VAL_ 870 BM_ZV_zu 0 "inaktiv" 1 "aktiv" ;
VAL_ 870 BM_DWA_ein 0 "inaktiv" 1 "aktiv" ;
VAL_ 870 BM_DWA_Alarm 0 "inaktiv" 1 "aktiv" ;
VAL_ 870 BM_Crash 0 "inaktiv" 1 "aktiv" ;
VAL_ 870 BM_Panik 0 "inaktiv" 1 "aktiv" ;
VAL_ 870 BM_Not_Bremsung 0 "kein_blinken" 1 "Notbremswarnblinken_aktiv" ;
VAL_ 870 BM_GDO 0 "inaktiv" 1 "aktiv" ;
VAL_ 870 BM_Warnblinken 0 "inaktiv" 1 "aktiv" ;
VAL_ 870 BM_Taxi_Notalarm 0 "inaktiv" 1 "aktiv" ;
VAL_ 870 BM_Telematik 0 "inaktiv" 1 "aktiv" ;
VAL_ 870 BM_links 0 "inaktiv" 1 "aktiv" ;
VAL_ 870 BM_rechts 0 "inaktiv" 1 "aktiv" ;
VAL_ 870 Blinken_li_Fzg_Takt 0 "Blinker_links_ausgeschaltet" 1 "Blinker_links_eingeschaltet" ;
VAL_ 870 Blinken_re_Fzg_Takt 0 "Blinker_rechts_ausgeschaltet" 1 "Blinker_rechts_eingeschaltet" ;
VAL_ 870 Blinken_li_Kombi_Takt 0 "Blinkerkontrolllampe_links_ausgeschaltet" 1 "Blinkerkontrolllampe_links_eingeschaltet" ;
VAL_ 870 Blinken_re_Kombi_Takt 0 "Blinkerkontrolllampe_rechts_ausgeschaltet" 1 "Blinkerkontrolllampe_rechts_eingeschaltet" ;
VAL_ 870 BM_NBA_n_codiert_n_aktiv 0 "codiert_AND_kein_Fehler" 1 "nicht_codiert_OR_Fehler_erkannt" ;
VAL_ 870 BM_NBA_Status 0 "NBA_nicht_aktiv" 1 "BRL_Dunkelphase" 3 "BRL_Hellphase" ;
VAL_ 870 BM_WBT_Beleuchtung 0 "inaktiv" 1 "aktiv" ;
VAL_ 870 BM_HD_Oeffnung_angelernt 0 "keine_Quittierung" 1 "Quittierung" ;
VAL_ 870 BM_Autobahn 0 "inaktiv" 1 "aktiv" ;
VAL_ 870 BM_Rollenmodus_Blinken 0 "inaktiv" 1 "aktiv" ;
VAL_ 870 BM_Recas 0 "kein_blinken" 1 "Recasblinken_aktiv" ;
VAL_ 870 BM_Wischblinken 0 "inaktiv" 1 "aktiv" ;
VAL_ 870 BM_Telematik_Abbruchgrund 0 "Init" 1 "speed_out_of_range" 2 "defect" 3 "clamp_s_on" 4 "clamp_15_on" 5 "door_open" 6 "engine_hood_open" 7 "trunk_open" 8 "convertible_top_not_locked" 9 "horn_activated_by_user" 10 "Higher_Prioritiy_Function_active" 11 "Central_Lock_status_changed" 12 "Request_Dropped_by_Requester" 13 "Service_Duration_Expired" 14 "not_possible_due_to_coding" 15 "no_reason_or_unknown_timeout" ;
VAL_ 870 BM_PiloPa 0 "PiloPa_Blinkerquittierung_inaktiv" 1 "PiloPa_Blinkerquittierung_aktiv" ;
VAL_ 870 DWA_Alarmquelle 0 "kein_Ausloesegrund" 1 "Tuerkontakt_Fahrertuer" 2 "Tuerkontakt_Beifahrertuer" 3 "Tuerkontakt_hinten_links" 4 "Tuerkontakt_hinten_rechts" 5 "Motorhaubenkontakt_vorne" 6 "Kofferraum_hinten" 7 "Masseschleife_der_Heckscheibe" 8 "Innenraumueberwachung" 9 "Alarm_durch_Noteinstieg" 10 "Sounder" 11 "Neigungssensor" 12 "TSG_FT_am_CAN_Bus" 13 "TSG_BT_am_CAN_Bus" 14 "TSG_HFS_am_CAN_Bus" 15 "TSG_HBFS_am_CAN_Bus" 16 "Klemme_15" 17 "Klemme_15sig" 18 "frei" 19 "Anhaengerueberwachung" 20 "Scheinwerferueberwachung_links" 21 "Scheinwerferueberwachung_rechts" 22 "Handschuhkasten" 23 "Verdeckueberwachung" 24 "OBD_Alarm" 25 "Power_on_Reset" 30 "Init" 31 "Fehler" ;
VAL_ 1714 DGN_Verlernzaehler 255 "ungültiger Zählerstand oder kein gültiger Fahrzyklus" ;
VAL_ 1714 KBI_Kilometerstand 1048574 "Init" 1048575 "Fehler" ;
VAL_ 1714 UH_Monat 0 "Init" 14 "Relatives_Datum" 15 "Fehler" ;
VAL_ 1714 UH_Tag 0 "Init" ;
VAL_ 1714 Kombi_02_alt 0 "aktuell" 1 "veraltet" ;
VAL_ 1714 Uhrzeit_01_alt 0 "aktuell" 1 "veraltet" ;
VAL_ 1520 DI_KL_58xd 254 "Init" 255 "Fehler" ;
VAL_ 1520 DI_KL_58xs 126 "Init" 127 "Fehler" ;
VAL_ 1520 DI_KL_58xt 126 "Init" 127 "Fehler" ;
VAL_ 1520 BCM1_Stellgroesse_Kl_58s 125 "Nicht_verbaut" 126 "Init" 127 "Fehler" ;
VAL_ 2589283628 VTS_Anf_DC_Suche 0 "keine_Anforderung" 1 "Anforderung_aktiv" ;
VAL_ 2589283628 VTS_Anf_DC_Suche_ID 0 "Init" 1 "Driver_Card_Nr_1" 2 "Driver_Card_Nr_2" 3 "Driver_Card_Nr_3" 4 "Driver_Card_Nr_4" 5 "Driver_Card_Nr_5" 6 "Driver_Card_Nr_6" 7 "Driver_Card_Nr_7" ;
VAL_ 420 EA_Parken_beibehalten_HMS 0 "Parken_nicht_beibehalten" 1 "Parken_beibehalten" 2 "Init" 3 "Fehler" ;
VAL_ 420 EA_Warnruckprofil 0 "keine_Ruckanforderung" 1 "Profil_1" 2 "Profil_2" 3 "Profil_3" 4 "Profil_4" 5 "Profil_5" 6 "Profil_6" 7 "Profil_7" ;
VAL_ 420 EA_eCall_Anf 0 "Keine_Anforderung" 1 "Ausloesen_eCall" ;
VAL_ 420 EA_Funktionsstatus 0 "EA_INIT" 1 "EA_OFF" 2 "EA_STANDBY" 3 "EA_PHASE0_AKTIV" 4 "EA_PHASE1_AKTIV" 5 "EA_PHASE2_AKTIV" 6 "EA_PHASE3_AKTIV" 7 "EA_REVERSIBLER_FEHLER" 8 "EA_IRREVERSIBLER_FEHLER" ;
VAL_ 420 EA_Gurtstraffer_Anf 0 "Keine_Anforderung" 1 "Haptik_1" 2 "Haptik_2" 3 "Haptik_3" ;
VAL_ 420 EA_Anforderung_HMS 0 "keine_Anforderung" 1 "halten" 2 "parken" 3 "halten_Standby" 4 "anfahren" 5 "Loesen_ueber_Rampe" 6 "Parken_mit_P" ;
VAL_ 420 EA_Sollbeschleunigung 2046 "Neutralwert" 2047 "Fehler" ;
VAL_ 2589283655 eCall2_Statuslicht_Farbe2 0 "Aus" 1 "Blinken_1" 2 "Blinken_2" 3 "An" ;
VAL_ 2589283655 eCall2_Statuslicht_Farbe1 0 "Aus" 1 "Blinken_1" 2 "Blinken_2" 3 "An" ;
VAL_ 2589283655 eCall2_Funktionsstatus 0 "kein_Fehler" 1 "Fkt_eingeschraenkt" 2 "Fkt_eingeschraenkt_service" 3 "Fkt_nicht_verfuegbar" 4 "Fkt_Service" 5 "Fkt_deaktiviert" 6 "Fkt_aktiviert" 7 "init" ;
VAL_ 2589283655 eCall2_Subscription 0 "Init" 1 "unsubscribed" 2 "subscribed" ;
VAL_ 2589283655 ConBox_T6_Status 0 "Init" 1 "Timer_nicht_gestartet" 2 "Timer_gestartet" 3 "Timer_abgelaufen" ;
VAL_ 2589283655 eCall2_Funktionsstatus_02 0 "kein_Fehler" 1 "Manueller_Notruf_aktiv" 2 "Automatischer_Notruf_aktiv" 7 "Init" ;
VAL_ 2589283655 ConBox_T3_Status 0 "Init" 1 "Timer_nicht_gestartet" 2 "Timer_gestartet" 3 "Timer_abgelaufen" ;
VAL_ 2589283655 eCall2_Mute_Anf 0 "kein_mute" 1 "mute" ;
VAL_ 1603 KBI_Einheit_Datum 0 "Tag/Monat/Jahr" 1 "Monat/Tag/Jahr" 2 "Jahr/Monat/Tag" 3 "reserviert" ;
VAL_ 1603 KBI_Einheit_Druck 0 "Druckangabe in bar" 1 "Druckangabe in psi" 2 "Druckangabe in kPa" 3 "tbd." ;
VAL_ 1603 KBI_Einheit_Streckenanz 0 "Kilometer" 1 "Meilen" ;
VAL_ 1603 KBI_MFA_v_Einheit_02 0 "kmh" 1 "mph" ;
VAL_ 1603 KBI_Einheit_Temp 0 "Grad Celsius °C" 1 "Grad Fahrenheit °F" ;
VAL_ 1603 KBI_Einheit_Uhrzeit 0 "24h" 1 " 12h AM/PM" ;
VAL_ 1603 KBI_Einheit_Verbrauch 0 "mpg UK" 1 "mpg USA" 2 "Liter/100km" 3 "km/Liter" ;
VAL_ 1603 KBI_Einheit_Volumen 0 "Liter" 1 "Gallonen UK" 2 "Gallonen USA" 3 "reserviert" ;
VAL_ 1603 KBI_Einheit_Verbrauch_elektr 0 "kWh_pro_100km" 1 "km_pro_kWh" 2 "kWh_pro_100mls" 3 "mls_pro_kWh" 4 "MPGe" ;
VAL_ 1603 KBI_Einheit_Verbrauch_Gas 0 "kg_per_100km" 1 "km_per_kg" 2 "m3_per_100km" 3 "km_per_m3" 4 "miles_per_lbs" 5 "miles_per_yard3" 6 "miles_per_kg" 7 "miles_per_m3" 8 "miles_per_gallon_equivalent_US" ;
VAL_ 1603 KBI_Einheit_Masse 0 "kg" 1 "lbs" 2 "reserviert" ;
VAL_ 259 ESP_VL_FR 0 "Vorwaerts" 1 "Rueckwaerts" ;
VAL_ 259 ESP_VR_FR 0 "Vorwaerts" 1 "Rueckwaerts" ;
VAL_ 259 ESP_HL_FR 0 "Vorwaerts" 1 "Rueckwaerts" ;
VAL_ 259 ESP_HR_FR 0 "Vorwaerts" 1 "Rueckwaerts" ;
VAL_ 259 ESP_VL_Radgeschw 4093 "Unterspannung" 4094 "Init" 4095 "Fehler" ;
VAL_ 259 ESP_VR_Radgeschw 4093 "Unterspannung" 4094 "Init" 4095 "Fehler" ;
VAL_ 259 ESP_HL_Radgeschw 4093 "Unterspannung" 4094 "Init" 4095 "Fehler" ;
VAL_ 259 ESP_HR_Radgeschw 4093 "Unterspannung" 4094 "Init" 4095 "Fehler" ;
VAL_ 278 ESP_QBit_Wegimpuls_VL 0 "gueltiger_Wert" 1 "Ersatz_Init_oder_Fehlerwert" ;
VAL_ 278 ESP_QBit_Wegimpuls_VR 0 "gueltiger_Wert" 1 "Ersatz_Init_oder_Fehlerwert" ;
VAL_ 278 ESP_QBit_Wegimpuls_HL 0 "gueltiger_Wert" 1 "Ersatz_Init_oder_Fehlerwert" ;
VAL_ 278 ESP_QBit_Wegimpuls_HR 0 "gueltiger_Wert" 1 "Ersatz_Init_oder_Fehlerwert" ;
VAL_ 278 ESP_Wegimpuls_VL 1021 "Init" 1022 "Unterspannung" 1023 "Fehler" ;
VAL_ 278 ESP_Wegimpuls_VR 1021 "Init" 1022 "Unterspannung" 1023 "Fehler" ;
VAL_ 278 ESP_Wegimpuls_HL 1021 "Init" 1022 "Unterspannung" 1023 "Fehler" ;
VAL_ 278 ESP_Wegimpuls_HR 1021 "Init" 1022 "Unterspannung" 1023 "Fehler" ;
VAL_ 278 ESP_VL_Fahrtrichtung 0 "Vorwaerts" 1 "Rueckwaerts" 2 "Init" 3 "ungueltig_oder_nicht_verbaut" ;
VAL_ 278 ESP_VR_Fahrtrichtung 0 "Vorwaerts" 1 "Rueckwaerts" 2 "Init" 3 "ungueltig_oder_nicht_verbaut" ;
VAL_ 278 ESP_HL_Fahrtrichtung 0 "Vorwaerts" 1 "Rueckwaerts" 2 "Init" 3 "ungueltig_oder_nicht_verbaut" ;
VAL_ 278 ESP_HR_Fahrtrichtung 0 "Vorwaerts" 1 "Rueckwaerts" 2 "Init" 3 "ungueltig_oder_nicht_verbaut" ;
VAL_ 1629 BR_Systemart 0 "ABS" 1 "ABS_ASR" 2 "ESP" 3 "ESP_mit_integrierter_EPB" ;
VAL_ 1629 ESP_SpannungsAnf_02 0 "keine_Anforderung" 1 "Anforderung_Stufe1" 2 "Anforderung_Stufe2" 3 "Anforderung_Stufe3" ;
VAL_ 1629 ESP_Charisma_FahrPr 0 "keine_Funktion" 1 "Programm_1" 2 "Programm_2" 3 "Programm_3" 4 "Programm_4" 5 "Programm_5" 6 "Programm_6" 7 "Programm_7" 8 "Programm_8" 9 "Programm_9" 10 "Programm_10" 11 "Programm_11" 12 "Programm_12" 13 "Programm_13" 14 "Programm_14" 15 "Programm_15" ;
VAL_ 1629 ESP_Charisma_Status 0 "Init" 1 "verfuegbar" 2 "nicht_verfuegbar" 3 "asynchron_durch_Fahrerwunsch" ;
VAL_ 1629 ESP_Wiederstart_Anz_01 0 "keine_Anzeige" 1 "Rueckwaertsrollen" ;
VAL_ 1629 ESP_Wiederstart_Anz_02 0 "keine_Anzeige" 1 "Autohold_Rutschen" ;
VAL_ 1629 ESP_Wiederstart_Anz_03 0 "keine_Anzeige" 1 "Offroad_HDC" ;
VAL_ 1629 ESP_Wiederstart_Anz_04 0 "keine_Anzeige" 1 "ESC_Off" ;
VAL_ 1629 ESP_Stoppverbot_Anz_01 0 "keine_Anzeige" 1 "Notbremsung_aktiv" ;
VAL_ 1629 ESP_Stoppverbot_Anz_02 0 "keine_Anzeige" 1 "Autohold_AVH_Rutschen" ;
VAL_ 1629 ESP_Stoppverbot_Anz_03 0 "keine_Anzeige" 1 "Rueckwaertsrollen" ;
VAL_ 1629 ESP_Stoppverbot_Anz_04 0 "keine_Anzeige" 1 "ESP_Pumpenlauf" ;
VAL_ 1629 ESP_Stoppverbot_Anz_05 0 "keine_Anzeige" 1 "ESP_OFF" ;
VAL_ 1629 ESP_Stoppverbot_Anz_06 0 "keine_Anzeige" 1 "Offroad_HDC" ;
VAL_ 1629 ESP_Stoppverbot_Anz_07 0 "keine_Anzeige" 1 "ESP_Haltefunktion_nicht_verfuegbar" ;
VAL_ 1629 ESP_Stoppverbot_Anz_Std 0 "keine_Anzeige" 1 "Standard_Stoppvetogrund" ;
VAL_ 1629 ESP_Dachrelingsensor 0 "Sensor_nicht_verbaut" 1 "Quertraeger_montiert" 2 "Quertraeger_nicht_montiert" 3 "Fehler" ;
VAL_ 1629 ESP_Stoppverbot_Anz_08 0 "keine_Anzeige" 1 "Neigungsbegrenzung" ;
VAL_ 1629 HDC_Charisma_FahrPr 0 "keine_Funktion" 1 "Programm_1" 2 "Programm_2" 3 "Programm_3" 4 "Programm_4" 5 "Programm_5" 6 "Programm_6" 7 "Programm_7" 8 "Programm_8" 9 "Programm_9" 10 "Programm_10" 11 "Programm_11" 12 "Programm_12" 13 "Programm_13" 14 "Programm_14" 15 "Programm_15" ;
VAL_ 1629 HDC_Charisma_Status 0 "Init" 1 "verfuegbar" 2 "nicht_verfuegbar" 3 "asynchron_durch_Fahrerwunsch" ;
VAL_ 1629 BR_QBit_Reifenumfang 0 "gueltiger_Wert" 1 "Ersatz_Init_oder_Fehlerwert" ;
VAL_ 253 BR_Eingriffsmoment 1022 "Init" 1023 "Fehler" ;
VAL_ 253 MSR_verfuegbar 0 "verfuegbar" 1 "nicht_verfuegbar" ;
VAL_ 253 ESP_Diagnose 0 "ESP_nicht_in_Diagnose" 1 "ESP_in_Diagnose" ;
VAL_ 253 ESC_v_Signal_Qualifier_High_Low 0 "Gueteschwelle_kleiner_1kmh" 1 "Gueteschwelle_kleiner_3kmh" 2 "Gueteschwelle_kleiner_5kmh" 3 "Gueteschwelle_kleiner_10kmh" 4 "Gueteschwelle_kleiner_20kmh" 5 "Gueteschwelle_groessergleich_20kmh" 6 "Init" 7 "Fehler" ;
VAL_ 253 ESP_Vorsteuerung 0 "keine_Vorsteuerung_aktiv" 1 "Vorsteuerung_aktiv" ;
VAL_ 253 OBD_Schlechtweg 0 "kein_Schlechtweg_erkannt" 1 "Schlechtweg_erkannt" ;
VAL_ 253 OBD_QBit_Schlechtweg 0 "gueltiger_Wert" 1 "Ersatz_Init_oder_Fehlerwert" ;
VAL_ 253 ESP_v_Signal 65533 "Unterspannung" 65534 "Init" 65535 "Fehler" ;
VAL_ 253 ASR_Tastung_passiv 0 "ASR_aktiviert" 1 "ASR_passiv_getastet_oder_Schwellen_geaendert" ;
VAL_ 253 ESP_Tastung_passiv 0 "ESP_aktiviert" 1 "ESP_passiv_getastet_oder_Schwellen_geaendert" ;
VAL_ 253 ESP_Systemstatus 0 "iO" 1 "Fehler" ;
VAL_ 253 ASR_Schalteingriff 0 "keine_Anforderung" 1 "ASR_Schaltkennfeld" 2 "Rueckschaltung" 3 "Schaltverbot" ;
VAL_ 253 ESP_QBit_v_Signal 0 "gueltiger_Wert" 1 "Ersatz_Init_oder_Fehlerwert" ;
VAL_ 253 ABS_Bremsung 0 "keine_ABS_Regelung" 1 "ABS_Regelung_aktiv" ;
VAL_ 253 ASR_Anf 0 "keine_Anforderung" 1 "ASR_Anforderung" ;
VAL_ 253 MSR_Anf 0 "keine Anfoderung" 1 "MSR-Anforderung" ;
VAL_ 253 EBV_Eingriff 0 "kein_EBV_Eingriff" 1 "EBV_Eingriff" ;
VAL_ 253 EDS_Eingriff 0 "kein_EDS_Eingriff" 1 "EDS_Eingriff" ;
VAL_ 253 ESP_Eingriff 0 "kein_ESP_Eingriff" 1 "ESP_Eingriff_aktiv" ;
VAL_ 253 ESP_ASP 0 "inaktiv" 1 "aktiv" ;
VAL_ 253 ESC_Neutralschaltung 0 "keine_Anforderung" 1 "Neutralschaltung_angefordert" ;
VAL_ 508 ESP_Status_Bremsentemp_02 0 "nicht_erhoeht" 1 "Schwelle_1" 2 "Schwelle_2" ;
VAL_ 508 ESP_Aggregataktivitaet 0 "inaktiv" 1 "aktiv" ;
VAL_ 508 ESP_Stillstandsflag 0 "kein_Stillstand_erkannt" 1 "Stillstand_erkannt" ;
VAL_ 508 ESC_MBK_Meldungen 0 "kein_Text" 1 "MBK_Hinweis_aktiv" 2 "MBK_Eskalation1_aktiv" ;
VAL_ 508 ESP_EDS_Anzeige 0 "Keine_Anzeige_aktiv" 1 "EDS_nicht_aktiv" 2 "EDS_aktiv_an_VA" 3 "EDS_aktiv_an_HA" 4 "EDS_aktiv_an_VA_und_HA" 5 "EDS_Uebertemperatur" 6 "EDS_Fehler" ;
VAL_ 508 RLE_Anzeigen 0 "keine_Anzeige" 1 "Rad_lose_allgemein" 2 "Rad_VL_lose" 3 "Rad_VR_lose" 4 "Rad_HL_lose" 5 "Rad_HR_lose" 6 "RLE_Pruefphase" 7 "RLE_Systemstoerung" ;
VAL_ 508 ESP_Wiederstart_Anz_Std 0 "keine_Anzeige" 1 "Standard_Wiederstartgrund" ;
VAL_ 508 ESC_Anforderung_Airbrake 0 "keine_Anforderung" 1 "Anf_Bremsperformancestellung" ;
VAL_ 508 ESC_FBA_Meldungen 0 "kein_Text" 1 "FBA_Warnung_aktiv_MT" 2 "FBA_Warnung_aktiv_AT" ;
VAL_ 508 ESP_Rollover_Status_dyn 0 "Auspraegung1" 1 "Auspraegung2" 2 "Auspraegung3" 3 "Auspraegung4" ;
VAL_ 508 ESP_Rollover_Status_stat 0 "Auspraegung1" 1 "Auspraegung2" 2 "Auspraegung3" 3 "Auspraegung4" ;
VAL_ 508 ESP_AVH_LED 0 "LED_aus" 1 "LED_ein" 2 "LED_blinken" 3 "Funktion_gesperrt__LED_aus" 6 "Init" ;
VAL_ 508 ESP_HDC_LED 0 "LED_aus" 1 "LED_ein" 2 "LED_blinken" 3 "Funktion_gesperrt__LED_aus" 6 "Init" ;
VAL_ 508 ESP_Off_LED 0 "LED_aus" 1 "LED_ein" 2 "LED_blinken" 3 "Funktion_gesperrt__LED_aus" 6 "Init" ;
VAL_ 508 ESP_Notbremsanzeige 0 "keine_Notbremsung_erkannt" 1 "Notbremsung_erkannt" ;
VAL_ 508 ESC_Motorstartverzoegerung 0 "Startfreigabe" 1 "Anforderung_Startverzoegerung" ;
VAL_ 508 ESP_Offroad_Lampe 0 "Aus" 1 "Ein" ;
VAL_ 508 ESP_HDC_Textanzeigen 0 "kein_Text" 1 "HDC_ein" 2 "HDC_aus" 3 "HDC_nicht_verfuegbar_in_FahrPr" 4 "HDC_nicht_verfuegbar_Uebertemp" 5 "HDC_verfuegbar_keine_Uebertemp" 6 "HDC_nicht_verfuegbar_ACC_aktiv" 7 "HDC_nicht_verfuegbar_GRA_aktiv" 8 "HDC_nicht_verfuegbar_LIM_aktiv" 9 "HDC_nicht_verfuegbar_IPA_aktiv" 10 "HDC_nicht_verfuegbar_PLA_aktiv" 11 "HDC_nicht_verf_anderes_Syst_akt" 12 "HDC_nicht_verfuegbar_Fehler" 13 "GRA_Hebel_einschalten" 14 "Funk_nicht_verfuegbar_bei_HDC" 15 "Funk_verfuegbar_wenn_HDC_aktiv" 16 "Deaktivierung_ESP_Eingriff" 17 "HDC_nicht_verfuegbar_ABS_solo" 18 "HDC_nicht_verfuegbar_Gaspedal" ;
VAL_ 508 ESP_HOLD_verf 0 "nicht_verfuegbar" 1 "verfuegbar" ;
VAL_ 879 GNSS_Breite_Ortung 134217726 "Init" 134217727 "Fehler" ;
VAL_ 879 GNSS_Richtung_Breite_Ortung 0 "Nord" 1 "Sued" ;
VAL_ 879 GNSS_Laenge_Ortung 268435454 "Init" 268435455 "Fehler" ;
VAL_ 879 GNSS_Richtung_Laenge_Ortung 0 "Ost" 1 "West" ;
VAL_ 879 GNSS_Ortung_FIX_Typ 0 "Init" 1 "No_Fix" 2 "2D_Fix" 3 "3D_Fix" ;
VAL_ 879 GNSS_Fehlerzustand 0 "Kein_Fehler" 1 "P_Mode" 2 "T_Mode" 3 "GNSS_Receiver_Problem" 4 "Kommunikationsproblem_im_SG" 5 "Start_GNSS_Receiver" 6 "GNSS_Receiver_aus" 7 "SG_spezifischer_Fehler" ;
VAL_ 884 GNSS_Ortung_Latenz 1022 "Init" 1023 "Fehler" ;
VAL_ 884 GNSS_Ortung_Ausrichtung 4094 "Init" 4095 "Fehler" ;
VAL_ 884 GNSS_Ortung_2D_Geschw_ue_Grund 510 "Init" 511 "Fehler" ;
VAL_ 884 GNSS_Ortung_Noerdliche_Geschw 1022 "Init" 1023 "Fehler" ;
VAL_ 884 GNSS_Ortung_Oestliche_Geschw 1022 "Init" 1023 "Fehler" ;
VAL_ 884 GNSS_Ortung_Vertikale_Geschw 1022 "Init" 1023 "Fehler" ;
VAL_ 886 GNSS_Ortung_GDOP 510 "Init" 511 "Fehler" ;
VAL_ 886 GNSS_Ortung_PDOP 510 "Init" 511 "Fehler" ;
VAL_ 886 GNSS_Ortung_HDOP 510 "Init" 511 "Fehler" ;
VAL_ 886 GNSS_Ortung_VDOP 510 "Init" 511 "Fehler" ;
VAL_ 886 GNSS_Ortung_Guete_Geschwindigk 62 "Init" 63 "Fehler" ;
VAL_ 886 GNSS_Ortung_Guete_Ausrichtung 62 "Init" 63 "Fehler" ;
VAL_ 886 GNSS_Ortung_Guete_horizontal 254 "Init" 255 "Fehler" ;
VAL_ 886 GNSS_Ortung_Guete_vertikal 62 "Init" 63 "Fehler" ;
VAL_ 888 GNSS_Ortung_Zeit_in_GPSWoche 1073741822 "Init" 1073741823 "Fehler" ;
VAL_ 888 GNSS_Ortung_Hoehe 4094 "Init" 4095 "Fehler" ;
VAL_ 891 GNSS_UTC_Zeit 0 "Init" ;
VAL_ 891 GNSS_Empfaenger_Status 0 "Backup_Mode" 1 "Live" ;
VAL_ 891 GNSS_GPS_in_Nutzung 0 "unbenutzt" 1 "benutzt" ;
VAL_ 891 GNSS_GLONASS_in_Nutzung 0 "unbenutzt" 1 "benutzt" ;
VAL_ 891 GNSS_Empfangbare_Satelliten 0 "Init" 31 "31_oder_mehr" ;
VAL_ 891 GNSS_Sichtbare_Satelliten 0 "Init" 31 "31_oder_mehr" ;
VAL_ 891 GNSS_Genutzte_Satelliten 0 "Init" 31 "31_oder_mehr" ;
VAL_ 1364 GNSS_Sat_Info_SNR_ID_1 31 "SNR_mehr_als_61_dB" ;
VAL_ 1364 GNSS_Sat_Info_Azimuth_ID_1 511 "Init" ;
VAL_ 1364 GNSS_Sat_Info_Hoehenwinkel_ID_1 127 "Init" ;
VAL_ 2463978722 GNSS_DR_Breite_Ortung 134217726 "Init" 134217727 "Fehler" ;
VAL_ 2463978722 GNSS_DR_Richtung_Breite_Ortung 0 "Nord" 1 "Sued" ;
VAL_ 2463978722 GNSS_DR_Laenge_Ortung 268435454 "Init" 268435455 "Fehler" ;
VAL_ 2463978722 GNSS_DR_Richtung_Laenge_Ortung 0 "Ost" 1 "West" ;
